VERSION "dbc-export 1 2025.20.8"

NS_ :

BS_:

BU_: ADSP APB APP APS APSB BB BMS CC CMP CMPD CP DAS DI DIF DIR DPB EPAS3P EPAS3S EPASTP EPASTS EPBL EPBR ESP EVSE FC GTW HCML HCMR HVP IBST ICR IDB LS OCS1P PARK PCS PM PMF PMR PNCD PTC RADC RCM RCM2 RCM3 RCU SCCM SCM SCS SDCR TAS TCU TPMS TRCM UI UIS UMC USM VC VCFRONT VCLEFT VCRIGHT VCSEC VEH

BO_ 1021 UI_autopilotControl: 8 UI
 SG_ UI_autopilotControlIndex M : 0|3@1+ (1,0) [0|7] "" Vector__XXX
 SG_ UI_hovEnabled m0 : 3|1@1+ (1,0) [0|1] "" Vector__XXX
 SG_ UI_donDisableAutoWiperDuration m0 : 4|3@1+ (1,0) [0|7] "" Vector__XXX
 SG_ UI_donDisableOnAutoWiperSpeed m0 : 7|4@1+ (1,0) [0|15] "" Vector__XXX
 SG_ UI_blindspotMinSpeed m0 : 11|4@1+ (1,0) [0|15] "" Vector__XXX
 SG_ UI_blindspotDistance m0 : 15|3@1+ (1,0) [0|7] "" Vector__XXX
 SG_ UI_blindspotTTC m0 : 18|3@1+ (1,0) [0|7] "" Vector__XXX
 SG_ UI_donStopEndOfRampBuffer m0 : 21|3@1+ (1,0) [0|7] "" Vector__XXX
 SG_ UI_donDisableCutin m0 : 24|1@1+ (1,0) [0|1] "" Vector__XXX
 SG_ UI_smartSetSpeedOffset m0 : 25|6@1+ (1,-30) [-30|33] "%" Vector__XXX
 SG_ UI_smartSetSpeedOffsetType m0 : 31|1@1+ (1,0) [0|1] "" Vector__XXX
 SG_ UI_autopilotMonarchBackup m0 : 32|1@1+ (1,0) [0|1] "" Vector__XXX
 SG_ UI_fsdVisualizationEnabled m0 : 37|1@1+ (1,0) [0|1] "" Vector__XXX
 SG_ UI_fsdStopsControlEnabled m0 : 38|1@1+ (1,0) [0|1] "" Vector__XXX
 SG_ UI_fsdContinueOnGreenWithCIPV m0 : 39|1@1+ (1,0) [0|1] "" Vector__XXX
 SG_ UI_smartSetSpeed m0 : 40|1@1+ (1,0) [0|1] "" Vector__XXX
 SG_ UI_automaticSetSpeedOffset m0 : 41|1@1+ (1,0) [0|1] "" Vector__XXX
 SG_ UI_apply2021_1958_ISA m0 : 42|1@1+ (1,0) [0|1] "" Vector__XXX
 SG_ UI_apply2021_646_ELKS m0 : 43|1@1+ (1,0) [0|1] "" Vector__XXX
 SG_ UI_apply2021_1341_DDAW m0 : 44|1@1+ (1,0) [0|1] "" Vector__XXX
 SG_ UI_homelinkNearby m0 : 45|1@1+ (1,0) [0|1] "" Vector__XXX
 SG_ UI_enableFullSelfDriving m0 : 46|1@1+ (1,0) [0|1] "" Vector__XXX
 SG_ UI_hasFullSelfDriving m0 : 47|1@1+ (1,0) [0|1] "" Vector__XXX
 SG_ UI_autosteerActivation m0 : 48|1@1+ (1,0) [0|1] "" Vector__XXX
 SG_ UI_autopilotDrivingProfile m0 : 49|2@1+ (1,0) [0|3] "" Vector__XXX
 SG_ UI_fsdBetaRequest m0 : 51|1@1+ (1,0) [0|1] "" Vector__XXX
 SG_ UI_fullSelfDrivingSuspended m0 : 52|1@1+ (1,0) [0|1] "" Vector__XXX
 SG_ UI_disableOptionalLaneChanges m0 : 53|1@1+ (1,0) [0|1] "" Vector__XXX
 SG_ UI_applyR152_AEBS m0 : 59|1@1+ (1,0) [0|1] "" Vector__XXX
 SG_ UI_autopilotControlMux0Valid m0 : 63|1@1+ (1,0) [0|1] "" Vector__XXX
 SG_ UI_selectableCameraRequest m1 : 8|4@1+ (1,0) [0|14] "" Vector__XXX
 SG_ UI_overrideSleepWithSuspend m1 : 16|1@1+ (1,0) [0|1] "" Vector__XXX
 SG_ UI_driverMonitorConfirmation m1 : 17|1@1+ (1,0) [0|1] "" Vector__XXX
 SG_ UI_parkAssistUseVision m1 : 18|1@1+ (1,0) [0|1] "" Vector__XXX
 SG_ UI_applyEceR79 m1 : 19|1@1+ (1,0) [0|1] "" Vector__XXX
 SG_ UI_enableMapStops m1 : 20|1@1+ (1,0) [0|1] "" Vector__XXX
 SG_ UI_disableMain m1 : 23|1@1+ (1,0) [0|1] "" Vector__XXX
 SG_ UI_disableNarrow m1 : 24|1@1+ (1,0) [0|1] "" Vector__XXX
 SG_ UI_disableFisheye m1 : 25|1@1+ (1,0) [0|1] "" Vector__XXX
 SG_ UI_disableLeftPillar m1 : 26|1@1+ (1,0) [0|1] "" Vector__XXX
 SG_ UI_disableRightPillar m1 : 27|1@1+ (1,0) [0|1] "" Vector__XXX
 SG_ UI_disableLeftRepeater m1 : 28|1@1+ (1,0) [0|1] "" Vector__XXX
 SG_ UI_disableRightRepeater m1 : 29|1@1+ (1,0) [0|1] "" Vector__XXX
 SG_ UI_disableBackup m1 : 30|1@1+ (1,0) [0|1] "" Vector__XXX
 SG_ UI_disableRadar m1 : 31|1@1+ (1,0) [0|1] "" Vector__XXX
 SG_ UI_noStalkConfirmAlertHaptic m1 : 32|1@1+ (1,0) [0|1] "" Vector__XXX
 SG_ UI_regulatoryLKA m1 : 33|1@1+ (1,0) [0|1] "" Vector__XXX
 SG_ UI_regulatoryLaneAssistLevel m1 : 34|1@1+ (1,0) [0|1] "" Vector__XXX
 SG_ UI_ulcSnooze m1 : 36|1@1+ (1,0) [0|1] "" Vector__XXX
 SG_ UI_noStalkConfirmAlertChime m1 : 37|1@1+ (1,0) [0|1] "" Vector__XXX
 SG_ UI_factorySummonEnable m1 : 39|1@1+ (1,0) [0|1] "" Vector__XXX
 SG_ UI_apmv3Branch m1 : 40|3@1+ (1,0) [0|7] "" Vector__XXX
 SG_ UI_enableCabinCamera m1 : 43|1@1+ (1,0) [0|1] "" Vector__XXX
 SG_ UI_enableAutopilotStopWarning m1 : 44|1@1+ (1,0) [0|1] "" Vector__XXX
 SG_ UI_showLaneGraph m1 : 45|1@1+ (1,0) [0|1] "" Vector__XXX
 SG_ UI_showTrackLabels m1 : 46|1@1+ (1,0) [0|1] "" Vector__XXX
 SG_ UI_hardCoreSummon m1 : 47|1@1+ (1,0) [0|1] "" Vector__XXX
 SG_ UI_enableCabinCameraTelemetry m1 : 48|1@1+ (1,0) [0|1] "" Vector__XXX
 SG_ UI_enableVisionSpeedControl m1 : 49|1@1+ (1,0) [0|1] "" Vector__XXX
 SG_ UI_autopilotTelemetryInChina m1 : 50|1@1+ (1,0) [0|1] "" Vector__XXX
 SG_ UI_enableTeslaAutopark m1 : 51|1@1+ (1,0) [0|1] "" Vector__XXX
 SG_ UI_autoTurnSignalMode m1 : 52|1@1+ (1,0) [0|1] "" Vector__XXX
 SG_ UI_enableCautionLightControl m1 : 54|1@1+ (1,0) [0|1] "" Vector__XXX
 SG_ UI_applyEceR79SmartSummonOnly m1 : 55|1@1+ (1,0) [0|1] "" Vector__XXX
 SG_ UI_autopilotMonarchEnabled m1 : 56|1@1+ (1,0) [0|1] "" Vector__XXX
 SG_ UI_autopilotEphemerisEnabled m1 : 57|1@1+ (1,0) [0|1] "" Vector__XXX
 SG_ UI_enableCabinAudioRecording m1 : 59|1@1+ (1,0) [0|1] "" Vector__XXX
 SG_ UI_autopilotControlMux1Valid m1 : 63|1@1+ (1,0) [0|1] "" Vector__XXX
 SG_ UI_enableApproachingEmergencyVeh m2 : 5|1@1+ (1,0) [0|1] "" Vector__XXX
 SG_ UI_enableStartFsdFromParkBrakeCo m2 : 6|1@1+ (1,0) [0|1] "" Vector__XXX
 SG_ UI_enableStartFsdFromPark m2 : 7|1@1+ (1,0) [0|1] "" Vector__XXX
 SG_ UI_fsdMaxSpeedOffsetPercentage m2 : 8|6@1+ (1,0) [0|63] "%" Vector__XXX
 SG_ UI_coldStartMonarchInFactory m2 : 16|1@1+ (1,0) [0|1] "" Vector__XXX
 SG_ UI_autopilotControlMux2Valid m2 : 63|1@1+ (1,0) [0|1] "" Vector__XXX

BO_ 819 UI_chargeRequest: 5 UI
 SG_ UI_openChargePortDoorRequest : 0|1@1+ (1,0) [0|1] "" Vector__XXX
 SG_ UI_closeChargePortDoorRequest : 1|1@1+ (1,0) [0|1] "" Vector__XXX
 SG_ UI_chargeEnableRequest : 2|1@1+ (1,0) [0|1] "" Vector__XXX
 SG_ UI_brickVLoggingRequest : 3|1@1+ (1,0) [0|1] "" Vector__XXX
 SG_ UI_brickBalancingDisabled : 4|1@1+ (1,0) [0|1] "" Vector__XXX
 SG_ UI_dSocAlertThreshold : 5|3@1+ (0.5,-4) [-4|-0.5] "%" Vector__XXX
 SG_ UI_acChargeCurrentLimit : 8|7@1+ (1,0) [0|126] "A" Vector__XXX
 SG_ UI_dSocAlertEnable : 15|1@1+ (1,0) [0|1] "" Vector__XXX
 SG_ UI_chargeTerminationPct : 16|10@1+ (0.1,0) [5|100] "%" Vector__XXX
 SG_ UI_chargeFeature1 : 26|1@1+ (1,0) [0|1] "" Vector__XXX
 SG_ UI_chargeFeature2 : 27|1@1+ (1,0) [0|1] "" Vector__XXX
 SG_ UI_chargeFeature3 : 28|1@1+ (1,0) [0|1] "" Vector__XXX
 SG_ UI_scheduledDepartureEnabled : 29|1@1+ (1,0) [0|1] "" Vector__XXX
 SG_ UI_chargePortLatchRequest : 30|2@1+ (1,0) [0|3] "" Vector__XXX
 SG_ UI_socSnapshotExpirationTime : 32|4@1+ (2,2) [2|32] "weeks" Vector__XXX
 SG_ UI_cpInletHeaterRequest : 36|2@1+ (1,0) [0|3] "" Vector__XXX
 SG_ UI_chargePowerSampleRequest : 38|1@1+ (1,0) [0|1] "" Vector__XXX
 SG_ UI_enableIso15118 : 39|1@1+ (1,0) [0|1] "" Vector__XXX

BO_ 659 UI_chassisControl: 8 UI
 SG_ UI_steeringTuneRequest : 0|2@1+ (1,0) [0|3] "" Vector__XXX
 SG_ UI_tractionControlMode : 2|3@1+ (1,0) [0|7] "" Vector__XXX
 SG_ UI_parkBrakeRequest : 5|2@1+ (1,0) [0|2] "" Vector__XXX
 SG_ UI_narrowGarages : 7|1@1+ (1,0) [0|1] "" Vector__XXX
 SG_ UI_winchModeRequest : 8|2@1+ (1,0) [0|3] "" Vector__XXX
 SG_ UI_zeroSpeedConfirmed : 10|2@1+ (1,0) [0|2] "" Vector__XXX
 SG_ UI_trailerMode : 12|1@1+ (1,0) [0|1] "" Vector__XXX
 SG_ UI_distanceUnits : 13|1@1+ (1,0) [0|1] "" Vector__XXX
 SG_ UI_dasDebugEnable : 14|1@1+ (1,0) [0|1] "" Vector__XXX
 SG_ UI_accOvertakeEnable : 16|2@1+ (1,0) [0|2] "" Vector__XXX
 SG_ UI_aebEnable : 18|2@1+ (1,0) [0|2] "" Vector__XXX
 SG_ UI_aesEnable : 20|2@1+ (1,0) [0|2] "" Vector__XXX
 SG_ UI_ahlbEnable : 22|2@1+ (1,0) [0|2] "" Vector__XXX
 SG_ UI_autoLaneChangeEnable : 24|2@1+ (1,0) [0|2] "" Vector__XXX
 SG_ UI_winchProxUserOverride : 26|1@1+ (1,0) [0|1] "" Vector__XXX
 SG_ UI_rebootAutopilot : 27|1@1+ (1,0) [0|1] "" Vector__XXX
 SG_ UI_autoParkRequest : 28|4@1+ (1,0) [0|14] "" Vector__XXX
 SG_ UI_bsdEnable : 32|2@1+ (1,0) [0|2] "" Vector__XXX
 SG_ UI_fcwEnable : 34|2@1+ (1,0) [0|2] "" Vector__XXX
 SG_ UI_fcwSensitivity : 36|2@1+ (1,0) [0|2] "" Vector__XXX
 SG_ UI_latControlEnable : 38|2@1+ (1,0) [0|2] "" Vector__XXX
 SG_ UI_ldwEnable : 40|2@1+ (1,0) [0|2] "" Vector__XXX
 SG_ UI_pedalSafetyEnable : 42|2@1+ (1,0) [0|2] "" Vector__XXX
 SG_ UI_pedalMap_epas : 44|2@1+ (1,0) [0|3] "" Vector__XXX
 SG_ UI_redLightStopSignEnable : 46|2@1+ (1,0) [0|2] "" Vector__XXX
 SG_ UI_selfParkTune : 48|4@1+ (1,0) [0|14] "" Vector__XXX
 SG_ UI_chassisControlCounter : 52|4@1+ (1,0) [0|15] "" Vector__XXX
 SG_ UI_chassisControlChecksum : 56|8@1+ (1,0) [0|255] "" Vector__XXX

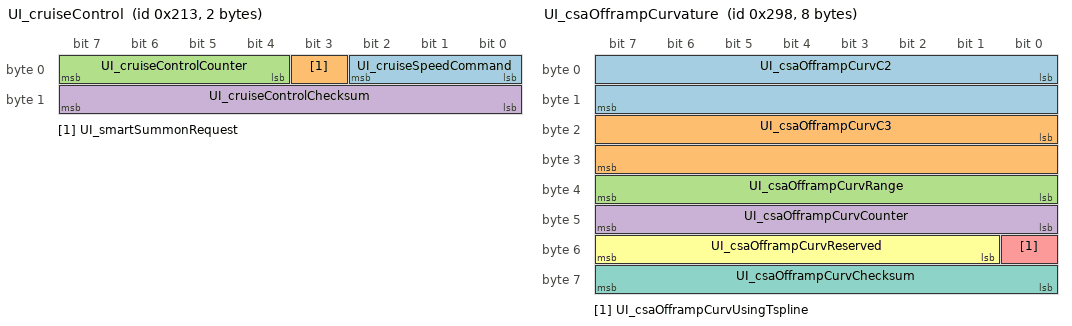
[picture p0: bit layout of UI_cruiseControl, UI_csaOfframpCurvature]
BO_ 531 UI_cruiseControl: 2 UI
 SG_ UI_cruiseSpeedCommand : 0|3@1+ (1,0) [0|7] "" Vector__XXX
 SG_ UI_smartSummonRequest : 3|1@1+ (1,0) [0|1] "" Vector__XXX
 SG_ UI_cruiseControlCounter : 4|4@1+ (1,0) [0|15] "" Vector__XXX
 SG_ UI_cruiseControlChecksum : 8|8@1+ (1,0) [0|255] "" Vector__XXX

BO_ 664 UI_csaOfframpCurvature: 8 UI
 SG_ UI_csaOfframpCurvC2 : 0|16@1- (1.0e-06,0) [-0.032768|0.032767] "1/m" Vector__XXX
 SG_ UI_csaOfframpCurvC3 : 16|16@1- (4.0e-09,0) [-0.000131072|0.000131068] "1/m2" Vector__XXX
 SG_ UI_csaOfframpCurvRange : 32|8@1+ (2,0) [0|510] "m" Vector__XXX
 SG_ UI_csaOfframpCurvCounter : 40|8@1+ (1,0) [0|255] "" Vector__XXX
 SG_ UI_csaOfframpCurvUsingTspline : 48|1@1+ (1,0) [0|1] "" Vector__XXX
 SG_ UI_csaOfframpCurvReserved : 49|7@1+ (1,0) [0|127] "" Vector__XXX
 SG_ UI_csaOfframpCurvChecksum : 56|8@1+ (1,0) [0|255] "" Vector__XXX

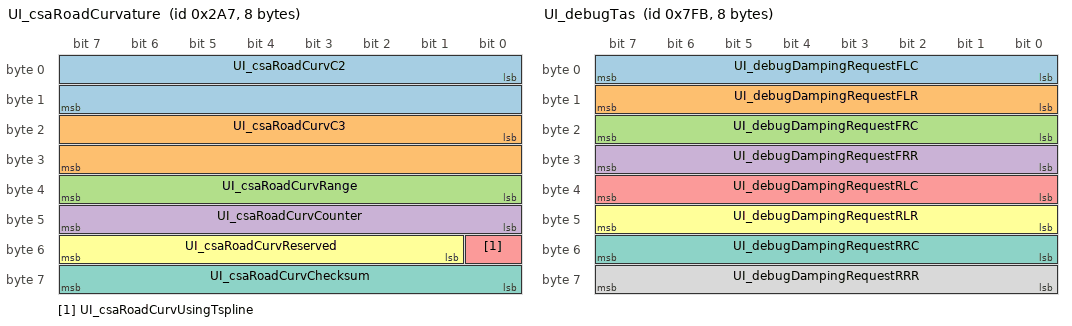
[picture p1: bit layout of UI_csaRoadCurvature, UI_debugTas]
BO_ 679 UI_csaRoadCurvature: 8 UI
 SG_ UI_csaRoadCurvC2 : 0|16@1- (1.0e-06,0) [-0.032768|0.032767] "1/m" Vector__XXX
 SG_ UI_csaRoadCurvC3 : 16|16@1- (4.0e-09,0) [-0.000131072|0.000131068] "1/m2" Vector__XXX
 SG_ UI_csaRoadCurvRange : 32|8@1+ (2,0) [0|510] "m" Vector__XXX
 SG_ UI_csaRoadCurvCounter : 40|8@1+ (1,0) [0|255] "" Vector__XXX
 SG_ UI_csaRoadCurvUsingTspline : 48|1@1+ (1,0) [0|1] "" Vector__XXX
 SG_ UI_csaRoadCurvReserved : 49|7@1+ (1,0) [0|127] "" Vector__XXX
 SG_ UI_csaRoadCurvChecksum : 56|8@1+ (1,0) [0|255] "" Vector__XXX

BO_ 1280 UI_debugECU: 2 UI
 SG_ UI_debugEcuTarget M : 0|5@1+ (1,0) [0|31] "" Vector__XXX
 SG_ UI_DI_debugEnable m1 : 8|1@1+ (1,0) [0|1] "" Vector__XXX
 SG_ UI_DIS_debugEnable m2 : 8|1@1+ (1,0) [0|1] "" Vector__XXX
 SG_ UI_PM_debugEnable m3 : 8|1@1+ (1,0) [0|1] "" Vector__XXX
 SG_ UI_PM_debugAt100Hz m3 : 9|1@1+ (1,0) [0|1] "" Vector__XXX
 SG_ UI_PMS_debugEnable m4 : 8|1@1+ (1,0) [0|1] "" Vector__XXX
 SG_ UI_PMS_debugAt100Hz m4 : 9|1@1+ (1,0) [0|1] "" Vector__XXX
 SG_ UI_BMS_debugAllEnable m5 : 8|1@1+ (1,0) [0|1] "" Vector__XXX
 SG_ UI_BMS_debugDisable m5 : 9|1@1+ (1,0) [0|1] "" Vector__XXX
 SG_ UI_VCRIGHT_debugEnable m6 : 8|1@1+ (1,0) [0|1] "" Vector__XXX
 SG_ UI_VCFRONT_debugEnable m7 : 5|1@1+ (1,0) [0|1] "" Vector__XXX
 SG_ UI_DIF_debugEnable m8 : 8|1@1+ (1,0) [0|1] "" Vector__XXX
 SG_ UI_DIR_debugEnable m9 : 8|1@1+ (1,0) [0|1] "" Vector__XXX
 SG_ UI_PMF_debugEnable m10 : 8|1@1+ (1,0) [0|1] "" Vector__XXX
 SG_ UI_PMR_debugEnable m11 : 8|1@1+ (1,0) [0|1] "" Vector__XXX

BO_ 2043 UI_debugTas: 8 UI
 SG_ UI_debugDampingRequestFLC : 0|8@1+ (0.01,0) [0|2.54] "A" Vector__XXX
 SG_ UI_debugDampingRequestFLR : 8|8@1+ (0.01,0) [0|2.54] "A" Vector__XXX
 SG_ UI_debugDampingRequestFRC : 16|8@1+ (0.01,0) [0|2.54] "A" Vector__XXX
 SG_ UI_debugDampingRequestFRR : 24|8@1+ (0.01,0) [0|2.54] "A" Vector__XXX
 SG_ UI_debugDampingRequestRLC : 32|8@1+ (0.01,0) [0|2.54] "A" Vector__XXX
 SG_ UI_debugDampingRequestRLR : 40|8@1+ (0.01,0) [0|2.54] "A" Vector__XXX
 SG_ UI_debugDampingRequestRRC : 48|8@1+ (0.01,0) [0|2.54] "A" Vector__XXX
 SG_ UI_debugDampingRequestRRR : 56|8@1+ (0.01,0) [0|2.54] "A" Vector__XXX

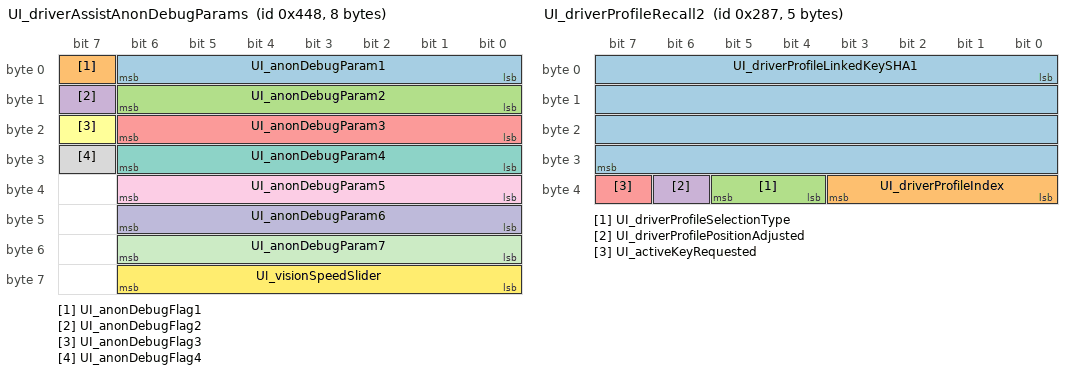
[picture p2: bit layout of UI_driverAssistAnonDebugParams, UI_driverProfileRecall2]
BO_ 1096 UI_driverAssistAnonDebugParams: 8 UI
 SG_ UI_anonDebugParam1 : 0|7@1+ (1,0) [0|127] "" Vector__XXX
 SG_ UI_anonDebugFlag1 : 7|1@1+ (1,0) [0|1] "" Vector__XXX
 SG_ UI_anonDebugParam2 : 8|7@1+ (1,0) [0|127] "" Vector__XXX
 SG_ UI_anonDebugFlag2 : 15|1@1+ (1,0) [0|1] "" Vector__XXX
 SG_ UI_anonDebugParam3 : 16|7@1+ (1,0) [0|127] "" Vector__XXX
 SG_ UI_anonDebugFlag3 : 23|1@1+ (1,0) [0|1] "" Vector__XXX
 SG_ UI_anonDebugParam4 : 24|7@1+ (1,0) [0|127] "" Vector__XXX
 SG_ UI_anonDebugFlag4 : 31|1@1+ (1,0) [0|1] "" Vector__XXX
 SG_ UI_anonDebugParam5 : 32|7@1+ (1,0) [0|127] "" Vector__XXX
 SG_ UI_anonDebugParam6 : 40|7@1+ (1,0) [0|127] "" Vector__XXX
 SG_ UI_anonDebugParam7 : 48|7@1+ (1,0) [0|127] "" Vector__XXX
 SG_ UI_visionSpeedSlider : 56|7@1+ (1,0) [0|127] "" Vector__XXX

BO_ 1016 UI_driverAssistControl: 8 UI
 SG_ UI_autopilotControlRequest : 0|1@1+ (1,0) [0|1] "" Vector__XXX
 SG_ UI_ulcStalkConfirm : 1|1@1+ (1,0) [0|1] "" Vector__XXX
 SG_ UI_summonHeartbeat : 2|2@1+ (1,0) [0|3] "" Vector__XXX
 SG_ UI_curvSpeedAdaptDisable : 4|1@1+ (1,0) [0|1] "" Vector__XXX
 SG_ UI_dasDeveloper : 5|1@1+ (1,0) [0|1] "" Vector__XXX
 SG_ UI_enableVinAssociation : 6|1@1+ (1,0) [0|1] "" Vector__XXX
 SG_ UI_lssLkaEnabled : 7|1@1+ (1,0) [0|1] "" Vector__XXX
 SG_ UI_lssLdwEnabled : 8|1@1+ (1,0) [0|1] "" Vector__XXX
 SG_ UI_coastToCoast : 9|1@1+ (1,0) [0|1] "" Vector__XXX
 SG_ UI_autoSummonEnable : 10|1@1+ (1,0) [0|1] "" Vector__XXX
 SG_ UI_exceptionListEnable : 11|1@1+ (1,0) [0|1] "" Vector__XXX
 SG_ UI_roadCheckDisable : 12|1@1+ (1,0) [0|1] "" Vector__XXX
 SG_ UI_driveOnMapsEnable : 13|1@1+ (1,0) [0|1] "" Vector__XXX
 SG_ UI_handsOnRequirementDisable : 14|1@1+ (1,0) [0|1] "" Vector__XXX
 SG_ UI_ulcOffHighway : 15|1@1+ (1,0) [0|1] "" Vector__XXX
 SG_ UI_fuseLanesDisable : 16|1@1+ (1,0) [0|1] "" Vector__XXX
 SG_ UI_fuseHPPDisable : 17|1@1+ (1,0) [0|1] "" Vector__XXX
 SG_ UI_fuseVehiclesDisable : 18|1@1+ (1,0) [0|1] "" Vector__XXX
 SG_ UI_enableClipParkedTelemetry : 19|1@1+ (1,0) [0|1] "" Vector__XXX
 SG_ UI_visionSpeedType : 20|2@1+ (1,0) [0|3] "" Vector__XXX
 SG_ UI_curvatureDatabaseOnly : 22|1@1+ (1,0) [0|1] "" Vector__XXX
 SG_ UI_lssElkEnabled : 23|1@1+ (1,0) [0|1] "" Vector__XXX
 SG_ UI_summonExitType : 24|2@1+ (1,0) [0|2] "" Vector__XXX
 SG_ UI_summonEntryType : 26|2@1+ (1,0) [0|2] "" Vector__XXX
 SG_ UI_selfParkRequest : 28|4@1+ (1,0) [0|14] "" Vector__XXX
 SG_ UI_summonReverseDist : 32|6@1+ (1,0) [0|62] "" Vector__XXX
 SG_ UI_undertakeAssistEnable : 38|1@1+ (1,0) [0|1] "" Vector__XXX
 SG_ UI_adaptiveSetSpeedEnable : 39|1@1+ (1,0) [0|1] "" Vector__XXX
 SG_ UI_drivingSide : 40|2@1+ (1,0) [0|3] "" Vector__XXX
 SG_ UI_enableClipTelemetry : 42|1@1+ (1,0) [0|1] "" Vector__XXX
 SG_ UI_enableTripTelemetry : 43|1@1+ (1,0) [0|1] "" Vector__XXX
 SG_ UI_enableRoadSegmentTelemetry : 44|1@1+ (1,0) [0|1] "" Vector__XXX
 SG_ UI_accFollowDistanceSetting : 45|3@1+ (1,0) [0|6] "" Vector__XXX
 SG_ UI_hasDriveOnNav : 48|1@1+ (1,0) [0|1] "" Vector__XXX
 SG_ UI_followNavRouteEnable : 49|1@1+ (1,0) [0|1] "" Vector__XXX
 SG_ UI_ulcSpeedConfig : 50|2@1+ (1,0) [0|3] "" Vector__XXX
 SG_ UI_ulcBlindSpotConfig : 52|2@1+ (1,0) [0|3] "" Vector__XXX
 SG_ UI_suppressExitPassingLane : 54|1@1+ (1,0) [0|1] "" Vector__XXX
 SG_ UI_enableClipStartStopTelemetry : 55|1@1+ (1,0) [0|1] "" Vector__XXX
 SG_ UI_alcOffHighwayEnable : 56|1@1+ (1,0) [0|1] "" Vector__XXX
 SG_ UI_validationLoop : 57|1@1+ (1,0) [0|1] "" Vector__XXX
 SG_ UI_smartSummonType : 58|2@1+ (1,0) [0|3] "" Vector__XXX
 SG_ UI_enableVisionOnlyStops : 60|1@1+ (1,0) [0|1] "" Vector__XXX
 SG_ UI_source3D : 61|2@1+ (1,0) [0|3] "" Vector__XXX
 SG_ UI_isaSpeedingChimeMuted : 63|1@1+ (1,0) [0|1] "" Vector__XXX

BO_ 568 UI_driverAssistMapData: 8 UI
 SG_ UI_mapSpeedLimitDependency : 0|3@1+ (1,0) [0|6] "" Vector__XXX
 SG_ UI_roadClass : 3|3@1+ (1,0) [1|7] "" Vector__XXX
 SG_ UI_inSuperchargerGeofence : 6|1@1+ (1,0) [0|1] "" Vector__XXX
 SG_ UI_mapSpeedUnits : 7|1@1+ (1,0) [0|1] "" Vector__XXX
 SG_ UI_mapSpeedLimit : 8|5@1+ (1,0) [0|30] "" Vector__XXX
 SG_ UI_mapSpeedLimitType : 13|3@1+ (1,0) [0|6] "" Vector__XXX
 SG_ UI_countryCode : 16|10@1+ (1,0) [0|1022] "" Vector__XXX
 SG_ UI_streetCount : 26|2@1+ (1,0) [0|3] "" Vector__XXX
 SG_ UI_gpsRoadMatch : 28|1@1+ (1,0) [0|1] "" Vector__XXX
 SG_ UI_navRouteActive : 29|1@1+ (1,0) [0|1] "" Vector__XXX
 SG_ UI_parallelAutoparkEnabled : 30|1@1+ (1,0) [0|1] "" Vector__XXX
 SG_ UI_perpendicularAutoparkEnabled : 31|1@1+ (1,0) [0|1] "" Vector__XXX
 SG_ UI_nextBranchDist : 32|5@1+ (10,0) [0|300] "m" Vector__XXX
 SG_ UI_controlledAccess : 37|1@1+ (1,0) [0|1] "" Vector__XXX
 SG_ UI_nextBranchLeftOffRamp : 38|1@1+ (1,0) [0|1] "" Vector__XXX
 SG_ UI_nextBranchRightOffRamp : 39|1@1+ (1,0) [0|1] "" Vector__XXX
 SG_ UI_rejectLeftLane : 40|1@1+ (1,0) [0|1] "" Vector__XXX
 SG_ UI_rejectRightLane : 41|1@1+ (1,0) [0|1] "" Vector__XXX
 SG_ UI_rejectHPP : 42|1@1+ (1,0) [0|1] "" Vector__XXX
 SG_ UI_rejectNav : 43|1@1+ (1,0) [0|1] "" Vector__XXX
 SG_ UI_rejectLeftFreeSpace : 44|1@1+ (1,0) [0|1] "" Vector__XXX
 SG_ UI_rejectRightFreeSpace : 45|1@1+ (1,0) [0|1] "" Vector__XXX
 SG_ UI_rejectAutosteer : 46|1@1+ (1,0) [0|1] "" Vector__XXX
 SG_ UI_rejectHandsOn : 47|1@1+ (1,0) [0|1] "" Vector__XXX
 SG_ UI_acceptBottsDots : 48|1@1+ (1,0) [0|1] "" Vector__XXX
 SG_ UI_autosteerRestricted : 49|1@1+ (1,0) [0|1] "" Vector__XXX
 SG_ UI_pmmEnabled : 50|1@1+ (1,0) [0|1] "" Vector__XXX
 SG_ UI_scaEnabled : 51|1@1+ (1,0) [0|1] "" Vector__XXX
 SG_ UI_mapDataCounter : 52|4@1+ (1,0) [0|15] "" Vector__XXX
 SG_ UI_mapDataChecksum : 56|8@1+ (1,0) [0|255] "" Vector__XXX

BO_ 536 UI_driverAssistRoadSign: 8 UI
 SG_ UI_roadSign M : 0|8@1+ (1,0) [0|254] "" Vector__XXX
 SG_ UI_splineLocConfidence : 40|7@1+ (1,0) [1|127] "1" Vector__XXX
 SG_ UI_splineID : 48|4@1+ (1,0) [0|15] "" Vector__XXX
 SG_ UI_roadSignCounter : 52|4@1+ (1,0) [0|15] "" Vector__XXX
 SG_ UI_roadSignChecksum : 56|8@1+ (1,0) [0|255] "" Vector__XXX
 SG_ UI_dummyData m0 : 8|1@1+ (1,0) [0|1] "" Vector__XXX
 SG_ UI_stopSignStopLineDist m1 : 8|10@1+ (0.25,-8) [-8|247.5] "m" Vector__XXX
 SG_ UI_stopSignStopLineConf m1 : 18|7@1+ (1,0) [1|127] "1" Vector__XXX
 SG_ UI_trafficLightStopLineDist m2 : 8|10@1+ (0.25,-8) [-8|247.5] "m" Vector__XXX
 SG_ UI_trafficLightStopLineConf m2 : 18|7@1+ (1,0) [1|127] "1" Vector__XXX
 SG_ UI_baseMapSpeedLimitMPS m3 : 8|8@1+ (0.25,0) [0|63.5] "m/s" Vector__XXX
 SG_ UI_bottomQrtlFleetSpeedMPS m3 : 16|8@1+ (0.25,0) [0|63.5] "m/s" Vector__XXX
 SG_ UI_topQrtlFleetSpeedMPS m3 : 24|8@1+ (0.25,0) [0|63.5] "m/s" Vector__XXX
 SG_ UI_meanFleetSplineSpeedMPS m4 : 8|8@1+ (0.25,0) [0|63.5] "m/s" Vector__XXX
 SG_ UI_medianFleetSpeedMPS m4 : 16|8@1+ (0.25,0) [0|63.5] "m/s" Vector__XXX
 SG_ UI_meanFleetSplineAccelMPS2 m4 : 24|8@1+ (0.05,-6.35) [-6.35|6.35] "m/s^2" Vector__XXX
 SG_ UI_rampType m4 : 32|3@1+ (1,0) [1|7] "" Vector__XXX
 SG_ UI_valhallaRamp m4 : 35|2@1+ (1,0) [1|3] "" Vector__XXX
 SG_ UI_overrideACMFleetSpeed m4 : 38|1@1+ (1,0) [0|1] "" Vector__XXX
 SG_ UI_currSplineIdFull m5 : 8|32@1+ (1,0) [1|4294967295] "1" Vector__XXX

BO_ 645 UI_driverProfileRecall: 8 UI
 SG_ UI_driverProfileRecallIndex M : 0|3@1+ (1,0) [1|7] "" Vector__XXX
 SG_ UI_driverProfileRecallStop : 3|1@1+ (1,0) [0|1] "" Vector__XXX
 SG_ UI_frontSeatRecallActive m1 : 4|1@1+ (1,0) [0|1] "" Vector__XXX
 SG_ UI_frontSeatTrackPos m1 : 5|10@1- (4,0) [-2048|2044] "mm" Vector__XXX
 SG_ UI_frontSeatBackPos m1 : 16|12@1- (0.1,0) [-204.8|204.7] "deg" Vector__XXX
 SG_ UI_frontSeatLiftPos m1 : 32|10@1- (4,0) [-2048|2044] "mm" Vector__XXX
 SG_ UI_frontSeatTiltPos m1 : 48|12@1- (0.1,0) [-204.8|204.7] "deg" Vector__XXX
 SG_ UI_columnAndLumbarRecallActive m2 : 4|1@1+ (1,0) [0|1] "" Vector__XXX
 SG_ UI_steeringColumnUpDownPos m2 : 8|8@1- (1,103) [-25|230] "mm" Vector__XXX
 SG_ UI_lumbarAPressureHpa m2 : 16|16@1+ (1,0) [0|65535] "" Vector__XXX
 SG_ UI_lumbarBPressureHpa m2 : 32|16@1+ (1,0) [0|65535] "" Vector__XXX
 SG_ UI_steeringColumnInOutPos m2 : 48|8@1- (1,103) [-25|230] "mm" Vector__XXX
 SG_ UI_leftMirrorTiltXPosition m3 : 8|8@1+ (0.02,0) [0|5] "V" Vector__XXX
 SG_ UI_leftMirrorTiltYPosition m3 : 16|8@1+ (0.02,0) [0|5] "V" Vector__XXX
 SG_ UI_rightMirrorTiltXPosition m3 : 24|8@1+ (0.02,0) [0|5.1] "V" Vector__XXX
 SG_ UI_rightMirrorTiltYPosition m3 : 32|8@1+ (0.02,0) [0|5.1] "V" Vector__XXX
 SG_ UI_mirrorRecallActive m4 : 4|1@1+ (1,0) [0|1] "" Vector__XXX
 SG_ UI_customMirrorDipPositionsSet m4 : 5|1@1+ (1,0) [0|1] "" Vector__XXX
 SG_ UI_leftMirrorDipXPosition m4 : 8|8@1+ (0.02,0) [0|5] "V" Vector__XXX
 SG_ UI_leftMirrorDipYPosition m4 : 16|8@1+ (0.02,0) [0|5] "V" Vector__XXX
 SG_ UI_rightMirrorDipXPosition m4 : 24|8@1+ (0.02,0) [0|5.1] "V" Vector__XXX
 SG_ UI_rightMirrorDipYPosition m4 : 32|8@1+ (0.02,0) [0|5.1] "V" Vector__XXX
 SG_ UI_modifyMirrorDipRequest m4 : 40|2@1+ (1,0) [0|3] "" Vector__XXX

BO_ 647 UI_driverProfileRecall2: 5 UI
 SG_ UI_driverProfileLinkedKeySHA1 : 0|32@1+ (1,0) [0|4294967294] "" Vector__XXX
 SG_ UI_driverProfileIndex : 32|4@1+ (1,0) [0|15] "" Vector__XXX
 SG_ UI_driverProfileSelectionType : 36|2@1+ (1,0) [0|3] "" Vector__XXX
 SG_ UI_driverProfilePositionAdjusted : 38|1@1+ (1,0) [0|1] "" Vector__XXX
 SG_ UI_activeKeyRequested : 39|1@1+ (1,0) [0|1] "" Vector__XXX

BO_ 1971 UI_dynamicTriggersCampaignFired: 8 UI
 SG_ UI_campaignFired : 0|64@1+ (1,0) [0|1.84467440737e+19] "" Vector__XXX

BO_ 984 UI_elevationStatus: 4 UI
 SG_ UI_elevation : 0|14@1- (1,0) [-8192|8190] "m" Vector__XXX
 SG_ UI_navElevation : 16|14@1- (1,0) [-8192|8190] "m" Vector__XXX

BO_ 1279 UI_energyConsumptionInfo: 8 UI
 SG_ UI_energyConsumptionInfoIndex M : 0|5@1+ (1,0) [0|31] "" Vector__XXX
 SG_ UI_energyLossTotal_epa m0 : 16|16@1- (1,0) [-32768|32767] "Wh" Vector__XXX
 SG_ UI_energyLossDriving_epa m0 : 32|16@1- (1,0) [-32768|32767] "Wh" Vector__XXX
 SG_ UI_energyLossClimate_epa m0 : 48|16@1- (1,0) [-32768|32767] "Wh" Vector__XXX
 SG_ UI_energyLossBattCond_epa m1 : 16|16@1- (1,0) [-32768|32767] "Wh" Vector__XXX
 SG_ UI_energyLossElevation_epa m1 : 32|16@1- (1,0) [-32768|32767] "Wh" Vector__XXX
 SG_ UI_energyLossAcc_epa m1 : 48|16@1- (1,0) [-32768|32767] "Wh" Vector__XXX
 SG_ UI_energyLossTotalSinceCharge_ep m2 : 16|16@1- (1,0) [-32768|32767] "Wh" Vector__XXX
 SG_ UI_energyLossDrivingSinceCharge_ m2 : 32|16@1- (1,0) [-32768|32767] "Wh" Vector__XXX
 SG_ UI_energyLossClimateSinceCharge_ m2 : 48|16@1- (1,0) [-32768|32767] "Wh" Vector__XXX
 SG_ UI_energyLossBattCondSinceCharge m3 : 16|16@1- (1,0) [-32768|32767] "Wh" Vector__XXX
 SG_ UI_energyLossElevationSinceCharg m3 : 32|16@1- (1,0) [-32768|32767] "Wh" Vector__XXX
 SG_ UI_energyLossAccSinceCharge_epa m3 : 48|16@1- (1,0) [-32768|32767] "Wh" Vector__XXX
 SG_ UI_energyLossTotalSinceTripStart m4 : 16|16@1- (1,0) [-32768|32767] "Wh" Vector__XXX
 SG_ UI_energyLossDrivingSinceTripSta m4 : 32|16@1- (1,0) [-32768|32767] "Wh" Vector__XXX
 SG_ UI_energyLossClimateSinceTripSta m4 : 48|16@1- (1,0) [-32768|32767] "Wh" Vector__XXX
 SG_ UI_energyLossBattCondSinceTripSt m5 : 16|16@1- (1,0) [-32768|32767] "Wh" Vector__XXX
 SG_ UI_energyLossElevationSinceTripS m5 : 32|16@1- (1,0) [-32768|32767] "Wh" Vector__XXX
 SG_ UI_energyLossAccSinceTripStart m5 : 48|16@1- (1,0) [-32768|32767] "Wh" Vector__XXX
 SG_ UI_energyDeltaTotal_epa m6 : 16|16@1- (1,0) [-32768|32767] "Wh" Vector__XXX
 SG_ UI_energyDeltaDriving_epa m6 : 32|16@1- (1,0) [-32768|32767] "Wh" Vector__XXX
 SG_ UI_energyDeltaClimate_epa m6 : 48|16@1- (1,0) [-32768|32767] "Wh" Vector__XXX
 SG_ UI_energyDeltaBattCond_epa m7 : 16|16@1- (1,0) [-32768|32767] "Wh" Vector__XXX
 SG_ UI_energyDeltaElevation_epa m7 : 32|16@1- (1,0) [-32768|32767] "Wh" Vector__XXX
 SG_ UI_energyDeltaAcc_epa m7 : 48|16@1- (1,0) [-32768|32767] "Wh" Vector__XXX
 SG_ UI_uiDeltaOffsetTotal_epa m8 : 16|16@1- (1,0) [-32768|32767] "Wh" Vector__XXX
 SG_ UI_uiDeltaOffsetDriving_epa m8 : 32|16@1- (1,0) [-32768|32767] "Wh" Vector__XXX
 SG_ UI_uiDeltaOffsetClimate_epa m8 : 48|16@1- (1,0) [-32768|32767] "Wh" Vector__XXX
 SG_ UI_uiDeltaOffsetBattCond_epa m9 : 16|16@1- (1,0) [-32768|32767] "Wh" Vector__XXX
 SG_ UI_uiDeltaOffsetElevation_epa m9 : 32|16@1- (1,0) [-32768|32767] "Wh" Vector__XXX
 SG_ UI_uiDeltaOffsetAcc_epa m9 : 48|16@1- (1,0) [-32768|32767] "Wh" Vector__XXX
 SG_ UI_rawToUiEnergyRatio_epa m10 : 8|8@1+ (0.01,0) [0|2.55] "-" Vector__XXX
 SG_ UI_driveDistance_epa m10 : 16|16@1+ (0.01,0) [0|655.35] "miles" Vector__XXX
 SG_ UI_energyDeltaTotalSinceCharge_e m11 : 16|16@1- (1,0) [-32768|32767] "Wh" Vector__XXX
 SG_ UI_energyDeltaDrivingSinceCharge m11 : 32|16@1- (1,0) [-32768|32767] "Wh" Vector__XXX
 SG_ UI_energyDeltaClimateSinceCharge m11 : 48|16@1- (1,0) [-32768|32767] "Wh" Vector__XXX
 SG_ UI_energyDeltaBattCondSinceCharg m12 : 16|16@1- (1,0) [-32768|32767] "Wh" Vector__XXX
 SG_ UI_energyDeltaElevationSinceChar m12 : 32|16@1- (1,0) [-32768|32767] "Wh" Vector__XXX
 SG_ UI_energyDeltaAccSinceCharge_epa m12 : 48|16@1- (1,0) [-32768|32767] "Wh" Vector__XXX
 SG_ UI_uiDeltaOffsetTotalSinceCharge m13 : 16|16@1- (1,0) [-32768|32767] "Wh" Vector__XXX
 SG_ UI_uiDeltaOffsetDrivingSinceChar m13 : 32|16@1- (1,0) [-32768|32767] "Wh" Vector__XXX
 SG_ UI_uiDeltaOffsetClimateSinceChar m13 : 48|16@1- (1,0) [-32768|32767] "Wh" Vector__XXX
 SG_ UI_uiDeltaOffsetBattCondSinceCha m14 : 16|16@1- (1,0) [-32768|32767] "Wh" Vector__XXX
 SG_ UI_uiDeltaOffsetElevationSinceCh m14 : 32|16@1- (1,0) [-32768|32767] "Wh" Vector__XXX
 SG_ UI_uiDeltaOffsetAccSinceCharge_e m14 : 48|16@1- (1,0) [-32768|32767] "Wh" Vector__XXX
 SG_ UI_rawToUiEnergyRatioSinceCharge m15 : 8|8@1+ (0.01,0) [0|2.55] "-" Vector__XXX
 SG_ UI_driveDistanceSinceCharge_epa m15 : 16|16@1+ (0.01,0) [0|655.35] "miles" Vector__XXX
 SG_ UI_energyDeltaTotalSinceTripStar m16 : 16|16@1- (1,0) [-32768|32767] "Wh" Vector__XXX
 SG_ UI_energyDeltaDrivingSinceTripSt m16 : 32|16@1- (1,0) [-32768|32767] "Wh" Vector__XXX
 SG_ UI_energyDeltaClimateSinceTripSt m16 : 48|16@1- (1,0) [-32768|32767] "Wh" Vector__XXX
 SG_ UI_energyDeltaBattCondSinceTripS m17 : 16|16@1- (1,0) [-32768|32767] "Wh" Vector__XXX
 SG_ UI_energyDeltaElevationSinceTrip m17 : 32|16@1- (1,0) [-32768|32767] "Wh" Vector__XXX
 SG_ UI_energyDeltaAccSinceTripStart m17 : 48|16@1- (1,0) [-32768|32767] "Wh" Vector__XXX
 SG_ UI_uiDeltaOffsetTotalSinceTripSt m18 : 16|16@1- (1,0) [-32768|32767] "Wh" Vector__XXX
 SG_ UI_uiDeltaOffsetDrivingSinceTrip m18 : 32|16@1- (1,0) [-32768|32767] "Wh" Vector__XXX
 SG_ UI_uiDeltaOffsetClimateSinceTrip m18 : 48|16@1- (1,0) [-32768|32767] "Wh" Vector__XXX
 SG_ UI_uiDeltaOffsetBattCondSinceTri m19 : 16|16@1- (1,0) [-32768|32767] "Wh" Vector__XXX
 SG_ UI_uiDeltaOffsetElevationSinceTr m19 : 32|16@1- (1,0) [-32768|32767] "Wh" Vector__XXX
 SG_ UI_uiDeltaOffsetAccSinceTripStar m19 : 48|16@1- (1,0) [-32768|32767] "Wh" Vector__XXX
 SG_ UI_rawToUiEnergyRatioSinceTripSt m20 : 8|8@1+ (0.01,0) [0|2.55] "-" Vector__XXX
 SG_ UI_driveDistanceSinceTripStart m20 : 16|16@1+ (0.01,0) [0|655.35] "miles" Vector__XXX
 SG_ UI_voyagerEnabled m21 : 5|1@1+ (1,0) [0|1] "" Vector__XXX
 SG_ UI_trailerMass m21 : 16|16@1+ (1,0) [0|65535] "kg" Vector__XXX

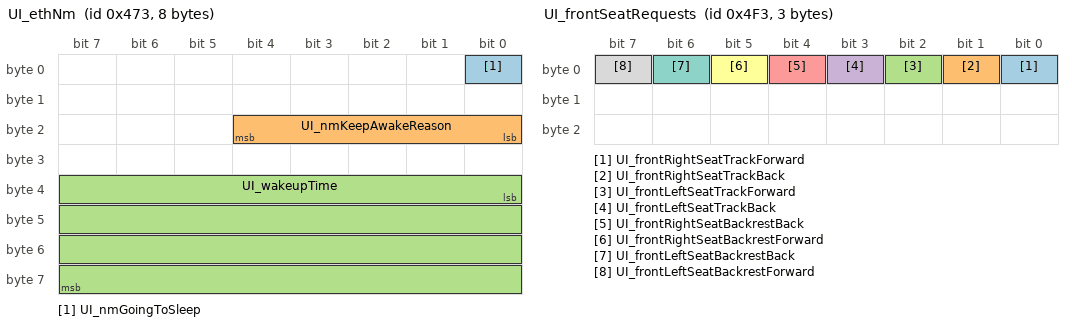
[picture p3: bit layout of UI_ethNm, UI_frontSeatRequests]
BO_ 1139 UI_ethNm: 8 UI
 SG_ UI_nmGoingToSleep : 0|1@1+ (1,0) [0|1] "" Vector__XXX
 SG_ UI_nmKeepAwakeReason : 16|5@1+ (1,0) [1|31] "" Vector__XXX
 SG_ UI_wakeupTime : 32|32@1+ (1,0) [0|4294967295] "" Vector__XXX

BO_ 1267 UI_frontSeatRequests: 3 UI
 SG_ UI_frontRightSeatTrackForward : 0|1@1+ (1,0) [0|1] "" Vector__XXX
 SG_ UI_frontRightSeatTrackBack : 1|1@1+ (1,0) [0|1] "" Vector__XXX
 SG_ UI_frontLeftSeatTrackForward : 2|1@1+ (1,0) [0|1] "" Vector__XXX
 SG_ UI_frontLeftSeatTrackBack : 3|1@1+ (1,0) [0|1] "" Vector__XXX
 SG_ UI_frontRightSeatBackrestBack : 4|1@1+ (1,0) [0|1] "" Vector__XXX
 SG_ UI_frontRightSeatBackrestForward : 5|1@1+ (1,0) [0|1] "" Vector__XXX
 SG_ UI_frontLeftSeatBackrestBack : 6|1@1+ (1,0) [0|1] "" Vector__XXX
 SG_ UI_frontLeftSeatBackrestForward : 7|1@1+ (1,0) [0|1] "" Vector__XXX

BO_ 804 UI_gpsTime: 8 UI
 SG_ UI_gpsTime : 0|64@1+ (1,0) [0|1.84467440737e+19] "" Vector__XXX

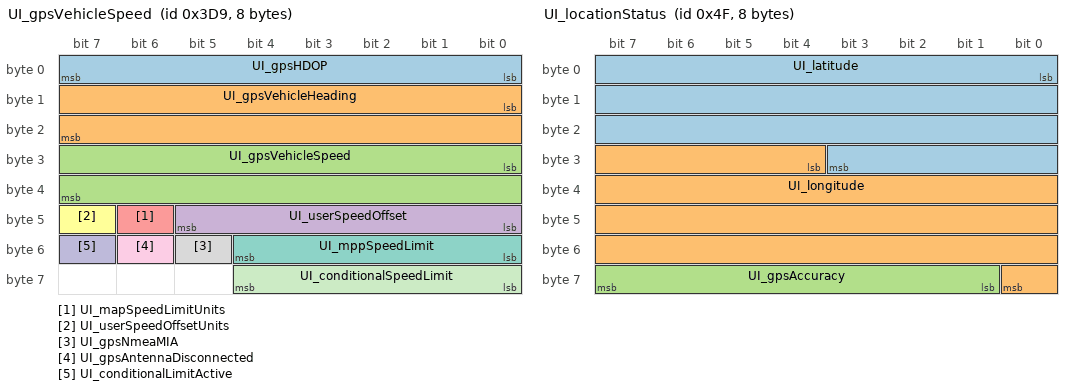
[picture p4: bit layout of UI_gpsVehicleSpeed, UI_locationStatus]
BO_ 985 UI_gpsVehicleSpeed: 8 UI
 SG_ UI_gpsHDOP : 0|8@1+ (0.1,0) [0|25.5] "1" Vector__XXX
 SG_ UI_gpsVehicleHeading : 8|16@1+ (0.0078125,0) [0|511.9921875] "deg" Vector__XXX
 SG_ UI_gpsVehicleSpeed : 24|16@1+ (0.00390625,0) [0|255.99609375] "km/hr" Vector__XXX
 SG_ UI_userSpeedOffset : 40|6@1+ (1,-30) [-30|33] "kph/mph" Vector__XXX
 SG_ UI_mapSpeedLimitUnits : 46|1@1+ (1,0) [0|1] "" Vector__XXX
 SG_ UI_userSpeedOffsetUnits : 47|1@1+ (1,0) [0|1] "" Vector__XXX
 SG_ UI_mppSpeedLimit : 48|5@1+ (5,0) [0|155] "kph/mph" Vector__XXX
 SG_ UI_gpsNmeaMIA : 53|1@1+ (1,0) [0|1] "" Vector__XXX
 SG_ UI_gpsAntennaDisconnected : 54|1@1+ (1,0) [0|1] "" Vector__XXX
 SG_ UI_conditionalLimitActive : 55|1@1+ (1,0) [0|1] "" Vector__XXX
 SG_ UI_conditionalSpeedLimit : 56|5@1+ (5,0) [0|150] "kph/mph" Vector__XXX

BO_ 755 UI_hvacRequest: 8 UI
 SG_ UI_hvacReqTempSetpointLeft : 0|5@1+ (0.5,15) [15|28] "degC" Vector__XXX
 SG_ UI_hvacReqAutoBlowerLevel : 5|3@1+ (1,0) [0|7] "" Vector__XXX
 SG_ UI_hvacReqTempSetpointRight : 8|5@1+ (0.5,15) [15|28] "degC" Vector__XXX
 SG_ UI_hvacReqAirDistributionMode : 13|3@1+ (1,0) [0|7] "" Vector__XXX
 SG_ UI_hvacReqBlowerSegment : 16|4@1+ (1,0) [0|15] "" Vector__XXX
 SG_ UI_hvacReqRecirc : 20|2@1+ (1,0) [0|3] "" Vector__XXX
 SG_ UI_hvacReqACDisable : 22|2@1+ (1,0) [0|3] "" Vector__XXX
 SG_ UI_hvacDefogState : 24|2@1+ (1,0) [0|3] "" Vector__XXX
 SG_ UI_hvacReqUserPowerState : 26|3@1+ (1,0) [0|7] "" Vector__XXX
 SG_ UI_hvacReqSecondRowState : 29|3@1+ (1,0) [0|7] "" Vector__XXX
 SG_ UI_hvacUseModeledDuctTemp : 32|1@1+ (1,0) [0|1] "" Vector__XXX
 SG_ UI_hvacReqKeepClimateOn : 33|2@1+ (1,0) [0|3] "" Vector__XXX
 SG_ UI_hvacReqBioWeaponDefMode : 35|1@1+ (1,0) [0|1] "" Vector__XXX
 SG_ UI_hvacLatchPassengerPresent : 39|1@1+ (1,0) [0|1] "" Vector__XXX
 SG_ UI_enableHvacControlsFeatures1 : 44|1@1+ (1,0) [0|1] "" Vector__XXX
 SG_ UI_enableHvacNotifications : 45|1@1+ (1,0) [0|1] "" Vector__XXX
 SG_ UI_hvacPhoneCallAirFlowAdjustEna : 46|1@1+ (1,0) [0|1] "" Vector__XXX
 SG_ UI_enableHvacVOCPurgeRoutine : 47|1@1+ (1,0) [0|1] "" Vector__XXX
 SG_ UI_enableCustomerTHSAlerts : 53|1@1+ (1,0) [0|1] "" Vector__XXX
 SG_ UI_evapDryingSelectiveEnable : 54|1@1+ (1,0) [0|1] "" Vector__XXX
 SG_ UI_enableHvacWeatherDataBasedHum : 55|1@1+ (1,0) [0|1] "" Vector__XXX
 SG_ UI_hvacReqTempSetpointCOP : 56|2@1+ (1,0) [0|3] "" Vector__XXX
 SG_ UI_hvacClimateNudgeStatus : 58|3@1+ (1,0) [0|7] "" Vector__XXX
 SG_ UI_enableHvacControlsFeatures2 : 61|1@1+ (1,0) [0|1] "" Vector__XXX
 SG_ UI_enableHvacAPFoggingMonitor : 62|1@1+ (1,0) [0|1] "" Vector__XXX
 SG_ UI_enableHvacLimpMode : 63|1@1+ (1,0) [0|1] "" Vector__XXX

BO_ 989 UI_locationOffset: 8 UI
 SG_ UI_latitudeOffset : 0|28@1- (1.0e-06,0) [-134.217728|134.217727] "deg" Vector__XXX
 SG_ UI_longitudeOffset : 28|29@1- (1.0e-06,0) [-268.435456|268.435455] "deg" Vector__XXX

BO_ 79 UI_locationStatus: 8 UI
 SG_ UI_latitude : 0|28@1- (1.0e-06,0) [-134.217728|134.217727] "deg" Vector__XXX
 SG_ UI_longitude : 28|29@1- (1.0e-06,0) [-268.435456|268.435455] "deg" Vector__XXX
 SG_ UI_gpsAccuracy : 57|7@1+ (0.2,0) [0|25.2] "m" Vector__XXX

BO_ 1011 UI_odo: 3 UI
 SG_ UI_odometer : 0|24@1+ (0.1,0) [0|1677721.4] "km" Vector__XXX

BO_ 443 UI_peripheralPowerRequests: 1 UI
 SG_ UI_usbFrontHubPowerStateRequest : 0|2@1+ (1,0) [1|3] "" Vector__XXX

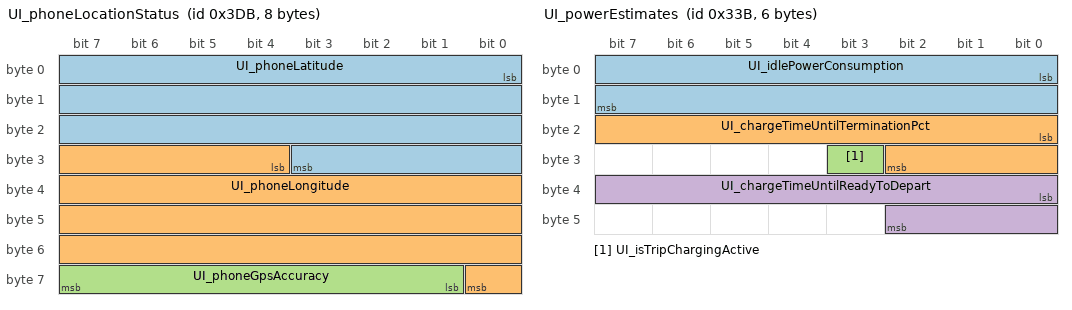
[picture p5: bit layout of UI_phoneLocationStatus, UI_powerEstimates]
BO_ 987 UI_phoneLocationStatus: 8 UI
 SG_ UI_phoneLatitude : 0|28@1- (1.0e-06,0) [-134.217728|134.217727] "deg" Vector__XXX
 SG_ UI_phoneLongitude : 28|29@1- (1.0e-06,0) [-268.435456|268.435455] "deg" Vector__XXX
 SG_ UI_phoneGpsAccuracy : 57|7@1+ (0.5,0) [0|63] "m" Vector__XXX

BO_ 955 UI_power: 2 UI
 SG_ UI_powerExpected : 0|8@1+ (1,0) [0|255] "kW" Vector__XXX
 SG_ UI_powerIdeal : 8|8@1+ (1,0) [0|255] "kW" Vector__XXX

BO_ 827 UI_powerEstimates: 6 UI
 SG_ UI_idlePowerConsumption : 0|16@1+ (0.001,0) [0|50] "kW" Vector__XXX
 SG_ UI_chargeTimeUntilTerminationPct : 16|11@1+ (1,0) [0|2046] "min" Vector__XXX
 SG_ UI_isTripChargingActive : 27|1@1+ (1,0) [0|1] "" Vector__XXX
 SG_ UI_chargeTimeUntilReadyToDepart : 32|11@1+ (1,0) [0|2046] "min" Vector__XXX

BO_ 629 UI_powerRationalityConfig: 8 UI
 SG_ UI_powerRationalityConfigIndex M : 56|8@1+ (1,0) [0|255] "" Vector__XXX
 SG_ UI_vcleftCfgRationalityThreshold m0 : 0|4@1+ (1,0) [1|15] "" Vector__XXX
 SG_ UI_vcleftCfgRationalityTime0 m0 : 4|4@1+ (1,0) [1|15] "" Vector__XXX
 SG_ UI_vcleftCfgRationalityThre_0001 m0 : 8|4@1+ (1,0) [1|15] "" Vector__XXX
 SG_ UI_vcleftCfgRationalityTime1 m0 : 12|4@1+ (1,0) [1|15] "" Vector__XXX
 SG_ UI_vcleftCfgRationalityStaticA m1 : 0|16@1+ (50,0) [0|3276700] "-" Vector__XXX
 SG_ UI_vcleftCfgRationalityStaticB m1 : 16|16@1- (1,0) [-32768|32767] "-" Vector__XXX
 SG_ UI_vcleftCfgRationalityStaticC m1 : 32|16@1- (50,0) [-1638400|1638350] "-" Vector__XXX
 SG_ UI_vcleftCfgRationalityDynamicA m2 : 0|16@1+ (50,0) [0|3276700] "-" Vector__XXX
 SG_ UI_vcleftCfgRationalityDynamicB m2 : 16|16@1- (1,0) [-32768|32767] "-" Vector__XXX
 SG_ UI_vcleftCfgRationalityDynamicC m2 : 32|16@1- (50,0) [-1638400|1638350] "-" Vector__XXX
 SG_ UI_vcrightCfgRationalityThreshol m3 : 0|4@1+ (1,0) [1|15] "" Vector__XXX
 SG_ UI_vcrightCfgRationalityTime0 m3 : 4|4@1+ (1,0) [1|15] "" Vector__XXX
 SG_ UI_vcrightCfgRationalityThr_0001 m3 : 8|4@1+ (1,0) [1|15] "" Vector__XXX
 SG_ UI_vcrightCfgRationalityTime1 m3 : 12|4@1+ (1,0) [1|15] "" Vector__XXX
 SG_ UI_vcrightCfgRationalityStaticA m4 : 0|16@1+ (50,0) [0|3276700] "-" Vector__XXX
 SG_ UI_vcrightCfgRationalityStaticB m4 : 16|16@1- (1,0) [-32768|32767] "-" Vector__XXX
 SG_ UI_vcrightCfgRationalityStaticC m4 : 32|16@1- (50,0) [-1638400|1638350] "-" Vector__XXX
 SG_ UI_vcrightCfgRationalityDynamicA m5 : 0|16@1+ (50,0) [0|3276700] "-" Vector__XXX
 SG_ UI_vcrightCfgRationalityDynamicB m5 : 16|16@1- (1,0) [-32768|32767] "-" Vector__XXX
 SG_ UI_vcrightCfgRationalityDynamicC m5 : 32|16@1- (50,0) [-1638400|1638350] "-" Vector__XXX
 SG_ UI_vcleftCfgCutoffThreshold0 m6 : 0|4@1+ (1,0) [1|15] "" Vector__XXX
 SG_ UI_vcleftCfgCutoffTime0 m6 : 4|4@1+ (1,0) [1|15] "" Vector__XXX
 SG_ UI_vcleftCfgCutoffThreshold1 m6 : 8|4@1+ (1,0) [1|15] "" Vector__XXX
 SG_ UI_vcleftCfgCutoffTime1 m6 : 12|4@1+ (1,0) [1|15] "" Vector__XXX
 SG_ UI_vcleftCfgCutoffStaticA m7 : 0|16@1+ (50,0) [0|3276700] "-" Vector__XXX
 SG_ UI_vcleftCfgCutoffStaticB m7 : 16|16@1- (1,0) [-32768|32767] "-" Vector__XXX
 SG_ UI_vcleftCfgCutoffStaticC m7 : 32|16@1- (50,0) [-1638400|1638350] "-" Vector__XXX
 SG_ UI_vcleftCfgCutoffDynamicA m8 : 0|16@1+ (50,0) [0|3276700] "-" Vector__XXX
 SG_ UI_vcleftCfgCutoffDynamicB m8 : 16|16@1- (1,0) [-32768|32767] "-" Vector__XXX
 SG_ UI_vcleftCfgCutoffDynamicC m8 : 32|16@1- (50,0) [-1638400|1638350] "-" Vector__XXX
 SG_ UI_vcrightCfgCutoffThreshold0 m9 : 0|4@1+ (1,0) [1|15] "" Vector__XXX
 SG_ UI_vcrightCfgCutoffTime0 m9 : 4|4@1+ (1,0) [1|15] "" Vector__XXX
 SG_ UI_vcrightCfgCutoffThreshold1 m9 : 8|4@1+ (1,0) [1|15] "" Vector__XXX
 SG_ UI_vcrightCfgCutoffTime1 m9 : 12|4@1+ (1,0) [1|15] "" Vector__XXX
 SG_ UI_vcrightCfgCutoffStaticA m10 : 0|16@1+ (50,0) [0|3276700] "-" Vector__XXX
 SG_ UI_vcrightCfgCutoffStaticB m10 : 16|16@1- (1,0) [-32768|32767] "-" Vector__XXX
 SG_ UI_vcrightCfgCutoffStaticC m10 : 32|16@1- (50,0) [-1638400|1638350] "-" Vector__XXX
 SG_ UI_vcrightCfgCutoffDynamicA m11 : 0|16@1+ (50,0) [0|3276700] "-" Vector__XXX
 SG_ UI_vcrightCfgCutoffDynamicB m11 : 16|16@1- (1,0) [-32768|32767] "-" Vector__XXX
 SG_ UI_vcrightCfgCutoffDynamicC m11 : 32|16@1- (50,0) [-1638400|1638350] "-" Vector__XXX

BO_ 820 UI_powertrainControl: 8 UI
 SG_ UI_systemPowerLimit : 0|5@1+ (20,20) [20|620] "kW" Vector__XXX
 SG_ UI_pedalMap : 5|2@1+ (1,0) [0|3] "" Vector__XXX
 SG_ UI_enableRegenBackfill : 7|1@1+ (1,0) [0|1] "" Vector__XXX
 SG_ UI_systemTorqueLimit : 8|6@1+ (150,1000) [1000|10300] "Nm" Vector__XXX
 SG_ UI_closureConfirmed : 14|2@1+ (1,0) [0|3] "" Vector__XXX
 SG_ UI_regenTorqueMax : 16|5@1+ (5,0) [0|100] "%" Vector__XXX
 SG_ UI_limitMode : 21|2@1+ (1,0) [0|3] "" Vector__XXX
 SG_ UI_factoryCustomerDrivingModeReq : 23|1@1+ (1,0) [0|1] "" Vector__XXX
 SG_ UI_motorOnMode : 24|2@1+ (1,0) [0|3] "" Vector__XXX
 SG_ UI_wasteMode : 26|2@1+ (1,0) [0|3] "" Vector__XXX
 SG_ UI_wasteModeRegenLimit : 28|2@1+ (1,0) [0|3] "" Vector__XXX
 SG_ UI_stoppingMode : 30|2@1+ (1,0) [0|3] "" Vector__XXX
 SG_ UI_DIAppSliderDebug : 32|2@1+ (1,0) [0|3] "" Vector__XXX
 SG_ UI_speedLimit : 34|12@1+ (0.1,0) [0|335] "kph" Vector__XXX
 SG_ UI_enableSmartShift : 46|2@1+ (1,0) [0|3] "" Vector__XXX
 SG_ UI_navVehParallelToRdCanContinue : 49|2@1+ (1,0) [1|3] "" Vector__XXX
 SG_ UI_powertrainControlCounter : 52|4@1+ (1,0) [0|15] "" Vector__XXX
 SG_ UI_powertrainControlChecksum : 56|8@1+ (1,0) [0|255] "" Vector__XXX

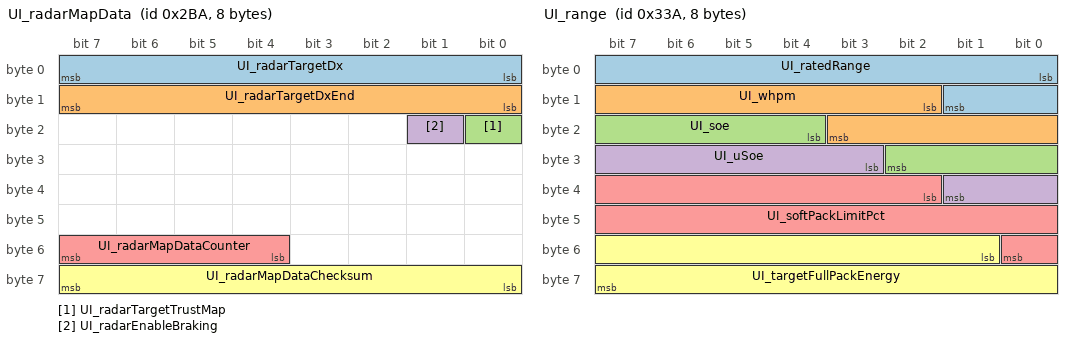
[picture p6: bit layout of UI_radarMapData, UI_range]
BO_ 698 UI_radarMapData: 8 UI
 SG_ UI_radarTargetDx : 0|8@1+ (1,-95) [-95|160] "m" Vector__XXX
 SG_ UI_radarTargetDxEnd : 8|8@1+ (1,0) [0|255] "m" Vector__XXX
 SG_ UI_radarTargetTrustMap : 16|1@1+ (1,0) [0|1] "" Vector__XXX
 SG_ UI_radarEnableBraking : 17|1@1+ (1,0) [0|1] "" Vector__XXX
 SG_ UI_radarMapDataCounter : 52|4@1+ (1,0) [0|15] "" Vector__XXX
 SG_ UI_radarMapDataChecksum : 56|8@1+ (1,0) [0|255] "" Vector__XXX

BO_ 826 UI_range: 8 UI
 SG_ UI_ratedRange : 0|10@1+ (1,0) [0|1023] "mi" Vector__XXX
 SG_ UI_whpm : 10|10@1+ (1,0) [0|1023] "" Vector__XXX
 SG_ UI_soe : 20|7@1+ (1,0) [0|127] "%" Vector__XXX
 SG_ UI_uSoe : 27|7@1+ (1,0) [0|127] "%" Vector__XXX
 SG_ UI_softPackLimitPct : 34|15@1+ (0.003051851,0) [0|100.000001717] "%" Vector__XXX
 SG_ UI_targetFullPackEnergy : 49|15@1+ (0.006103702,0) [0|200.000003434] "kWh" Vector__XXX

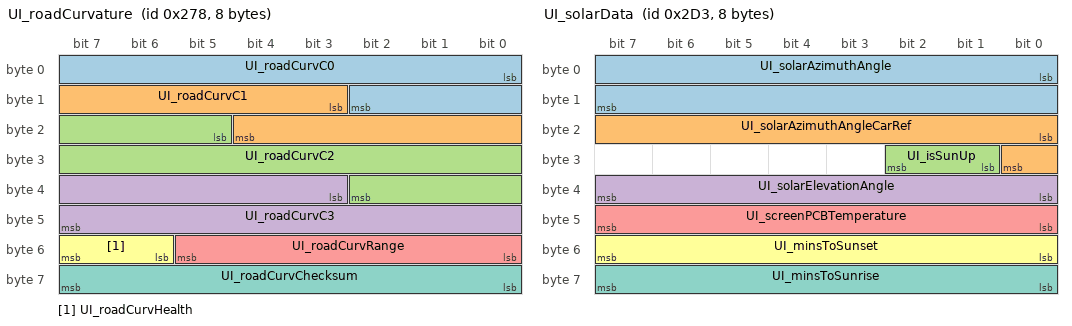
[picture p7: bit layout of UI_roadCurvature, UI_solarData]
BO_ 632 UI_roadCurvature: 8 UI
 SG_ UI_roadCurvC0 : 0|11@1- (0.02,0) [-20.48|20.46] "m" Vector__XXX
 SG_ UI_roadCurvC1 : 11|10@1- (0.00075,0) [-0.384|0.38325] "1" Vector__XXX
 SG_ UI_roadCurvC2 : 21|14@1- (7.5e-06,0) [-0.06144|0.0614325] "1/m" Vector__XXX
 SG_ UI_roadCurvC3 : 35|13@1- (3.0e-08,0) [-0.00012288|0.00012285] "1/m2" Vector__XXX
 SG_ UI_roadCurvRange : 48|6@1+ (4,0) [0|252] "m" Vector__XXX
 SG_ UI_roadCurvHealth : 54|2@1+ (1,0) [0|3] "" Vector__XXX
 SG_ UI_roadCurvChecksum : 56|8@1+ (1,0) [0|255] "" Vector__XXX

BO_ 723 UI_solarData: 8 UI
 SG_ UI_solarAzimuthAngle : 0|16@1- (1,0) [-32768|32767] "degrees" Vector__XXX
 SG_ UI_solarAzimuthAngleCarRef : 16|9@1- (1,0) [-256|254] "degrees" Vector__XXX
 SG_ UI_isSunUp : 25|2@1+ (1,0) [0|2] "" Vector__XXX
 SG_ UI_solarElevationAngle : 32|8@1- (1,0) [-128|126] "degrees" Vector__XXX
 SG_ UI_screenPCBTemperature : 40|8@1- (0.5,40) [-20|100] "degC" Vector__XXX
 SG_ UI_minsToSunset : 48|8@1+ (10,0) [0|2550] "min" Vector__XXX
 SG_ UI_minsToSunrise : 56|8@1+ (10,0) [0|2550] "min" Vector__XXX

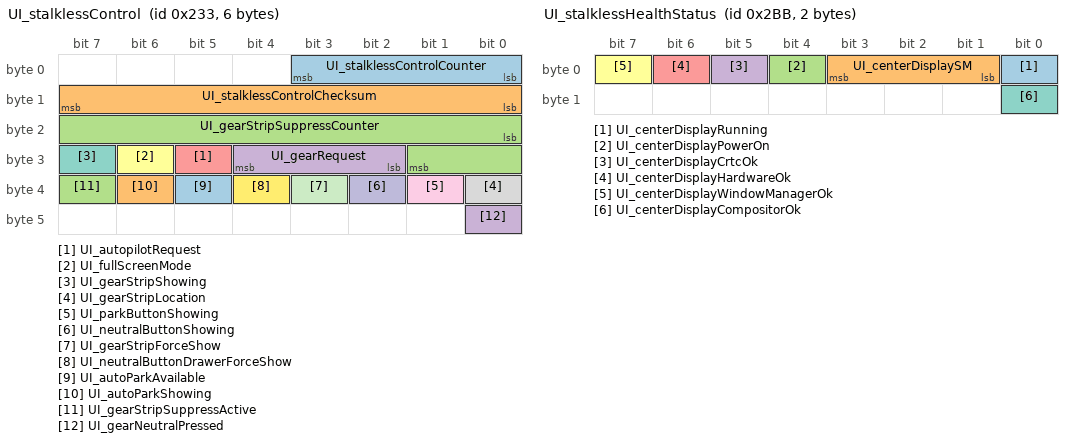
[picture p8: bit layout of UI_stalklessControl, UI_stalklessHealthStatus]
BO_ 563 UI_stalklessControl: 6 UI
 SG_ UI_stalklessControlCounter : 0|4@1+ (1,0) [0|15] "" Vector__XXX
 SG_ UI_stalklessControlChecksum : 8|8@1+ (1,0) [0|255] "" Vector__XXX
 SG_ UI_gearStripSuppressCounter : 16|10@1+ (1,0) [0|1023] "" Vector__XXX
 SG_ UI_gearRequest : 26|3@1+ (1,0) [1|7] "" Vector__XXX
 SG_ UI_autopilotRequest : 29|1@1+ (1,0) [0|1] "" Vector__XXX
 SG_ UI_fullScreenMode : 30|1@1+ (1,0) [0|1] "" Vector__XXX
 SG_ UI_gearStripShowing : 31|1@1+ (1,0) [0|1] "" Vector__XXX
 SG_ UI_gearStripLocation : 32|1@1+ (1,0) [0|1] "" Vector__XXX
 SG_ UI_parkButtonShowing : 33|1@1+ (1,0) [0|1] "" Vector__XXX
 SG_ UI_neutralButtonShowing : 34|1@1+ (1,0) [0|1] "" Vector__XXX
 SG_ UI_gearStripForceShow : 35|1@1+ (1,0) [0|1] "" Vector__XXX
 SG_ UI_neutralButtonDrawerForceShow : 36|1@1+ (1,0) [0|1] "" Vector__XXX
 SG_ UI_autoParkAvailable : 37|1@1+ (1,0) [0|1] "" Vector__XXX
 SG_ UI_autoParkShowing : 38|1@1+ (1,0) [0|1] "" Vector__XXX
 SG_ UI_gearStripSuppressActive : 39|1@1+ (1,0) [0|1] "" Vector__XXX
 SG_ UI_gearNeutralPressed : 40|1@1+ (1,0) [0|1] "" Vector__XXX

BO_ 699 UI_stalklessHealthStatus: 2 UI
 SG_ UI_centerDisplayRunning : 0|1@1+ (1,0) [0|1] "" Vector__XXX
 SG_ UI_centerDisplaySM : 1|3@1+ (1,0) [0|7] "" Vector__XXX
 SG_ UI_centerDisplayPowerOn : 4|1@1+ (1,0) [0|1] "" Vector__XXX
 SG_ UI_centerDisplayCrtcOk : 5|1@1+ (1,0) [0|1] "" Vector__XXX
 SG_ UI_centerDisplayHardwareOk : 6|1@1+ (1,0) [0|1] "" Vector__XXX
 SG_ UI_centerDisplayWindowManagerOk : 7|1@1+ (1,0) [0|1] "" Vector__XXX
 SG_ UI_centerDisplayCompositorOk : 8|1@1+ (1,0) [0|1] "" Vector__XXX

BO_ 851 UI_status: 8 UI
 SG_ UI_touchActive : 0|1@1+ (1,0) [0|1] "" Vector__XXX
 SG_ UI_audioActive : 1|1@1+ (1,0) [0|1] "" Vector__XXX
 SG_ UI_bluetoothActive : 2|1@1+ (1,0) [0|1] "" Vector__XXX
 SG_ UI_cellActive : 3|1@1+ (1,0) [0|1] "" Vector__XXX
 SG_ UI_displayReady : 4|1@1+ (1,0) [0|1] "" Vector__XXX
 SG_ UI_displayOn : 5|1@1+ (1,0) [0|1] "" Vector__XXX
 SG_ UI_wifiActive : 6|1@1+ (1,0) [0|1] "" Vector__XXX
 SG_ UI_wifiConnected : 7|1@1+ (1,0) [0|1] "" Vector__XXX
 SG_ UI_systemActive : 8|1@1+ (1,0) [0|1] "" Vector__XXX
 SG_ UI_readyForDrive : 9|1@1+ (1,0) [0|1] "" Vector__XXX
 SG_ UI_cellConnected : 10|1@1+ (1,0) [0|1] "" Vector__XXX
 SG_ UI_vpnActive : 11|1@1+ (1,0) [0|1] "" Vector__XXX
 SG_ UI_autopilotTrial : 12|2@1+ (1,0) [0|3] "" Vector__XXX
 SG_ UI_factoryReset : 14|2@1+ (1,0) [1|3] "" Vector__XXX
 SG_ UI_gpsActive : 16|1@1+ (1,0) [0|1] "" Vector__XXX
 SG_ UI_screenshotActive : 17|1@1+ (1,0) [0|1] "" Vector__XXX
 SG_ UI_radioActive : 18|1@1+ (1,0) [0|1] "" Vector__XXX
 SG_ UI_cellNetworkTechnology : 19|4@1+ (1,0) [0|14] "" Vector__XXX
 SG_ UI_cellReceiverPower : 24|8@1+ (1,-128) [-128|127] "dB" Vector__XXX
 SG_ UI_falseTouchCounter : 32|8@1+ (1,0) [0|255] "1" Vector__XXX
 SG_ UI_developmentCar : 40|1@1+ (1,0) [0|1] "" Vector__XXX
 SG_ UI_cameraActive : 41|1@1+ (1,0) [0|1] "" Vector__XXX
 SG_ UI_cellSignalBars : 42|3@1+ (1,0) [0|6] "" Vector__XXX
 SG_ UI_trailerModeTelltale : 45|2@1+ (1,0) [0|3] "" Vector__XXX
 SG_ UI_pcbTemperature : 48|8@1- (1,40) [-20|100] "degC" Vector__XXX
 SG_ UI_cpuTemperature : 56|8@1- (1,40) [-20|100] "degC" Vector__XXX

BO_ 991 UI_status2: 8 UI
 SG_ UI_mobileAppStepCount : 0|16@1+ (1,0) [0|65535] "" Vector__XXX
 SG_ UI_userRequestSnapshot : 16|1@1+ (1,0) [0|1] "" Vector__XXX
 SG_ UI_touchDetected : 17|1@1+ (1,0) [0|1] "" Vector__XXX
 SG_ UI_validDeviceForEUSummon : 18|1@1+ (1,0) [0|1] "" Vector__XXX
 SG_ UI_locatedAtHome : 19|1@1+ (1,0) [0|1] "" Vector__XXX
 SG_ UI_locatedAtWork : 20|1@1+ (1,0) [0|1] "" Vector__XXX
 SG_ UI_locatedAtFavorite : 21|1@1+ (1,0) [0|1] "" Vector__XXX
 SG_ UI_displayInDarkMode : 22|1@1+ (1,0) [0|1] "" Vector__XXX
 SG_ UI_userActivity : 23|1@1+ (1,0) [0|1] "" Vector__XXX
 SG_ UI_activeTouchPoints : 24|8@1+ (1,0) [0|255] "1" Vector__XXX
 SG_ UI_linkState : 32|2@1+ (1,0) [0|3] "" Vector__XXX
 SG_ UI_sentryModeState : 34|3@1+ (1,0) [0|7] "" Vector__XXX
 SG_ UI_autopilotSentryRequest : 37|1@1+ (1,0) [0|1] "" Vector__XXX
 SG_ UI_mobileAppConnected : 38|1@1+ (1,0) [0|1] "" Vector__XXX
 SG_ UI_autoshiftDRState : 40|3@1+ (1,0) [0|7] "" Vector__XXX
 SG_ UI_wifiBtModuleType : 43|3@1+ (1,0) [0|7] "" Vector__XXX
 SG_ UI_sohHealthStatus : 46|2@1+ (1,0) [0|3] "" Vector__XXX
 SG_ UI_selfParkState : 48|8@1+ (1,0) [0|254] "" Vector__XXX
 SG_ UI_summonDeviceIndex : 56|2@1+ (1,0) [0|3] "" Vector__XXX
 SG_ UI_sentryModeCameraDetection : 58|1@1+ (1,0) [0|1] "" Vector__XXX
 SG_ UI_wakeOnIPActive : 59|1@1+ (1,0) [0|1] "" Vector__XXX

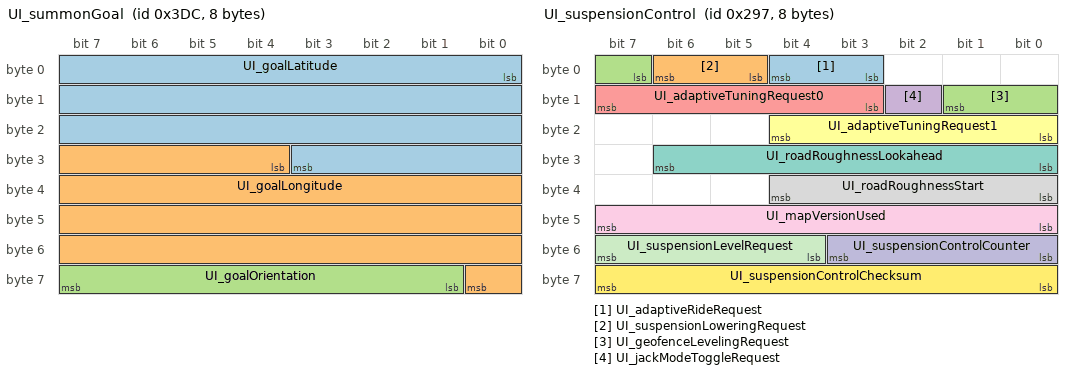
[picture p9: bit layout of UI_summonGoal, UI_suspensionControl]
BO_ 988 UI_summonGoal: 8 UI
 SG_ UI_goalLatitude : 0|28@1- (1.0e-06,0) [-134.217728|134.217727] "deg" Vector__XXX
 SG_ UI_goalLongitude : 28|29@1- (1.0e-06,0) [-268.435456|268.435455] "deg" Vector__XXX
 SG_ UI_goalOrientation : 57|7@1+ (2.8125,0) [0|357.1875] "deg" Vector__XXX

BO_ 663 UI_suspensionControl: 8 UI
 SG_ UI_adaptiveRideRequest : 3|2@1+ (1,0) [0|3] "" Vector__XXX
 SG_ UI_suspensionLoweringRequest : 5|2@1+ (1,0) [0|2] "" Vector__XXX
 SG_ UI_geofenceLevelingRequest : 7|3@1+ (1,0) [0|7] "" Vector__XXX
 SG_ UI_jackModeToggleRequest : 10|1@1+ (1,0) [0|1] "" Vector__XXX
 SG_ UI_adaptiveTuningRequest0 : 11|5@1- (0.1,0) [-1.6|1.5] "-" Vector__XXX
 SG_ UI_adaptiveTuningRequest1 : 16|5@1- (0.1,0) [-1.6|1.5] "-" Vector__XXX
 SG_ UI_roadRoughnessLookahead : 24|7@1+ (0.01,0) [0|1.26] "%" Vector__XXX
 SG_ UI_roadRoughnessStart : 32|5@1+ (10,0) [0|300] "m" Vector__XXX
 SG_ UI_mapVersionUsed : 40|8@1+ (1,0) [0|254] "-" Vector__XXX
 SG_ UI_suspensionControlCounter : 48|4@1+ (1,0) [0|15] "" Vector__XXX
 SG_ UI_suspensionLevelRequest : 52|4@1+ (1,0) [0|15] "" Vector__XXX
 SG_ UI_suspensionControlChecksum : 56|8@1+ (1,0) [0|255] "" Vector__XXX

BO_ 661 UI_systemMonitor: 8 UI
 SG_ UI_systemMonitorIndex M : 0|1@1+ (1,0) [0|1] "" Vector__XXX
 SG_ UI_SystemMemUsage m0 : 8|16@1+ (1,0) [0|65535] "MB" Vector__XXX
 SG_ UI_QtCarMemUsage m0 : 24|16@1+ (1,0) [0|65535] "MB" Vector__XXX
 SG_ UI_QtCarCPUUsage m0 : 40|7@1+ (1,0) [0|127] "%" Vector__XXX
 SG_ UI_emmcStatus m0 : 47|1@1+ (1,0) [0|1] "" Vector__XXX
 SG_ UI_SystemCPUUsage m0 : 48|7@1+ (1,0) [0|127] "%" Vector__XXX
 SG_ UI_HomeHealth m0 : 55|1@1+ (1,0) [0|1] "" Vector__XXX
 SG_ UI_VarHealth m0 : 56|1@1+ (1,0) [0|1] "" Vector__XXX
 SG_ UI_LogHealth m0 : 57|1@1+ (1,0) [0|1] "" Vector__XXX
 SG_ UI_TmpfsHealth m0 : 58|1@1+ (1,0) [0|1] "" Vector__XXX
 SG_ UI_emmcDataWritten m1 : 8|24@1+ (1,0) [0|16777215] "" Vector__XXX
 SG_ UI_emmcTotalErases m1 : 32|16@1+ (1,0) [0|65535] "" Vector__XXX

BO_ 1064 UI_telemetryControl: 8 UI
 SG_ UI_TCR_enable : 0|1@1+ (1,0) [0|1] "" Vector__XXX
 SG_ UI_TCR_moveStateStanding : 1|1@1+ (1,0) [0|1] "" Vector__XXX
 SG_ UI_TCR_moveStateStopped : 2|1@1+ (1,0) [0|1] "" Vector__XXX
 SG_ UI_TCR_moveStateMoving : 3|1@1+ (1,0) [0|1] "" Vector__XXX
 SG_ UI_TCR_moveStateIndeterm : 4|1@1+ (1,0) [0|1] "" Vector__XXX
 SG_ UI_TCR_classConstElem : 5|1@1+ (1,0) [0|1] "" Vector__XXX
 SG_ UI_TCR_classMovingPed : 6|1@1+ (1,0) [0|1] "" Vector__XXX
 SG_ UI_TCR_classMovingTwoWheel : 7|1@1+ (1,0) [0|1] "" Vector__XXX
 SG_ UI_TCR_classMovingFourWheel : 8|1@1+ (1,0) [0|1] "" Vector__XXX
 SG_ UI_TCR_classUnknown : 9|1@1+ (1,0) [0|1] "" Vector__XXX
 SG_ UI_TCR_downSampleFactor : 10|4@1+ (1,0) [0|15] "" Vector__XXX
 SG_ UI_TCR_wExist : 24|5@1+ (1,0) [0|31] "" Vector__XXX
 SG_ UI_TCR_vehSpeed : 32|8@1+ (1,0) [0|255] "" Vector__XXX
 SG_ UI_TCR_minRCS : 40|8@1+ (0.25,-14) [-14|49.75] "dB" Vector__XXX
 SG_ UI_TCR_maxDy : 48|5@1+ (0.5,0) [0|15.5] "m" Vector__XXX
 SG_ UI_TCR_maxObjects : 56|5@1+ (1,0) [0|31] "" Vector__XXX
 SG_ UI_TCR_maxRoadClass : 61|3@1+ (1,0) [0|7] "" Vector__XXX

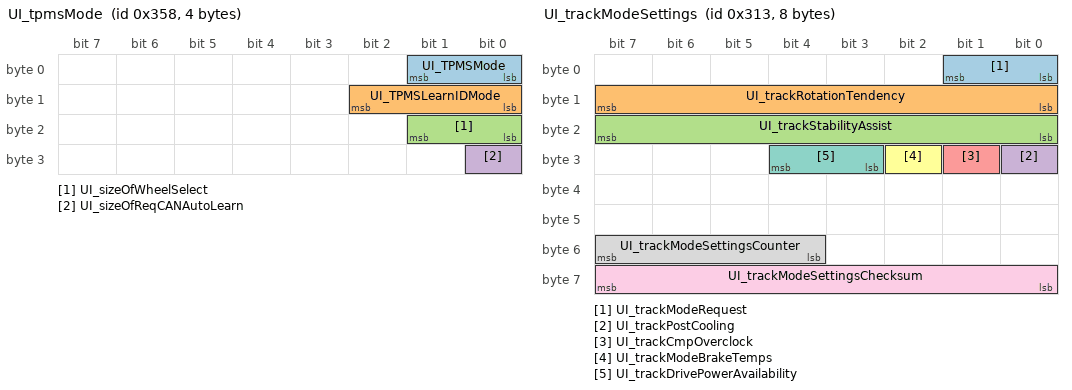
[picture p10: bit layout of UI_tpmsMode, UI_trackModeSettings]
BO_ 856 UI_tpmsMode: 4 UI
 SG_ UI_TPMSMode : 0|2@1+ (1,0) [0|3] "" Vector__XXX
 SG_ UI_TPMSLearnIDMode : 8|3@1+ (1,0) [0|7] "" Vector__XXX
 SG_ UI_sizeOfWheelSelect : 16|2@1+ (1,0) [0|3] "" Vector__XXX
 SG_ UI_sizeOfReqCANAutoLearn : 24|1@1+ (1,0) [0|1] "" Vector__XXX

BO_ 952 UI_tpmsRCPsetting: 4 UI
 SG_ UI_setRCPFront : 16|8@1+ (0.025,0) [0|6.375] "bar" Vector__XXX
 SG_ UI_setRCPRear : 24|8@1+ (0.025,0) [0|6.375] "bar" Vector__XXX

BO_ 787 UI_trackModeSettings: 8 UI
 SG_ UI_trackModeRequest : 0|2@1+ (1,0) [0|3] "" Vector__XXX
 SG_ UI_trackRotationTendency : 8|8@1+ (0.5,0) [0|127.5] "%" Vector__XXX
 SG_ UI_trackStabilityAssist : 16|8@1+ (0.5,0) [0|127.5] "%" Vector__XXX
 SG_ UI_trackPostCooling : 24|1@1+ (1,0) [0|1] "" Vector__XXX
 SG_ UI_trackCmpOverclock : 25|1@1+ (1,0) [0|1] "" Vector__XXX
 SG_ UI_trackModeBrakeTemps : 26|1@1+ (1,0) [0|1] "" Vector__XXX
 SG_ UI_trackDrivePowerAvailability : 27|2@1+ (1,0) [0|3] "" Vector__XXX
 SG_ UI_trackModeSettingsCounter : 52|4@1+ (1,0) [0|15] "" Vector__XXX
 SG_ UI_trackModeSettingsChecksum : 56|8@1+ (1,0) [0|255] "" Vector__XXX

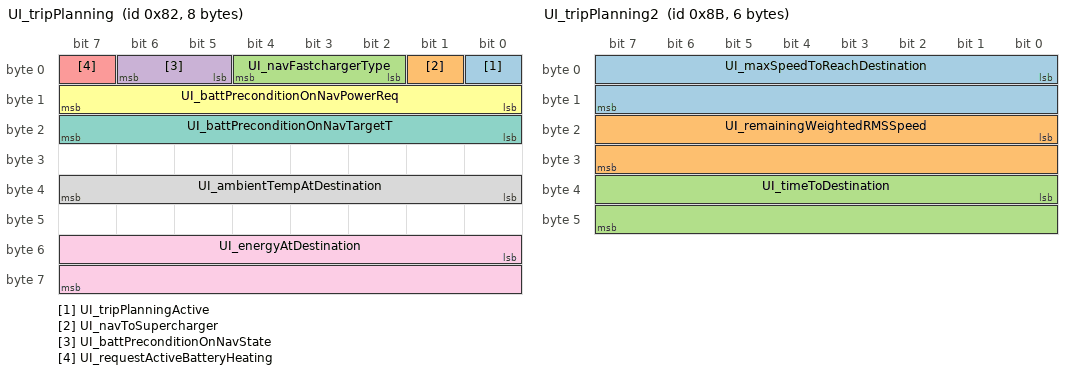
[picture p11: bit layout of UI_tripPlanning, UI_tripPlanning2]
BO_ 130 UI_tripPlanning: 8 UI
 SG_ UI_tripPlanningActive : 0|1@1+ (1,0) [0|1] "" Vector__XXX
 SG_ UI_navToSupercharger : 1|1@1+ (1,0) [0|1] "" Vector__XXX
 SG_ UI_navFastchargerType : 2|3@1+ (1,0) [0|7] "" Vector__XXX
 SG_ UI_battPreconditionOnNavState : 5|2@1+ (1,0) [0|3] "" Vector__XXX
 SG_ UI_requestActiveBatteryHeating : 7|1@1+ (1,0) [0|1] "" Vector__XXX
 SG_ UI_battPreconditionOnNavPowerReq : 8|8@1- (125,0) [-16000|15750] "W" Vector__XXX
 SG_ UI_battPreconditionOnNavTargetT : 16|8@1+ (0.25,0) [0|63.5] "degC" Vector__XXX
 SG_ UI_ambientTempAtDestination : 32|8@1- (0.5,0) [-64|63.5] "degC" Vector__XXX
 SG_ UI_energyAtDestination : 48|16@1- (0.01,0) [-327.67|327.67] "kWh" Vector__XXX

BO_ 139 UI_tripPlanning2: 6 UI
 SG_ UI_maxSpeedToReachDestination : 0|16@1+ (0.01,0) [0|655.34] "m/s" Vector__XXX
 SG_ UI_remainingWeightedRMSSpeed : 16|16@1+ (0.01,0) [0|655.34] "m/s" Vector__XXX
 SG_ UI_timeToDestination : 32|16@1+ (1,0) [0|65534] "s" Vector__XXX

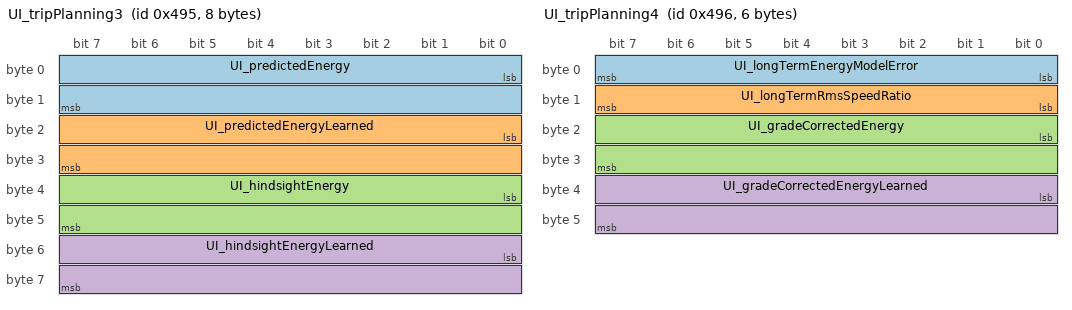
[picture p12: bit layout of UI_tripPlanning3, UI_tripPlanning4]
BO_ 1173 UI_tripPlanning3: 8 UI
 SG_ UI_predictedEnergy : 0|16@1- (0.01,0) [-327.67|327.67] "kWh" Vector__XXX
 SG_ UI_predictedEnergyLearned : 16|16@1- (0.01,0) [-327.68|327.67] "kWh" Vector__XXX
 SG_ UI_hindsightEnergy : 32|16@1- (0.01,0) [-327.67|327.67] "kWh" Vector__XXX
 SG_ UI_hindsightEnergyLearned : 48|16@1- (0.01,0) [-327.68|327.67] "kWh" Vector__XXX

BO_ 1174 UI_tripPlanning4: 6 UI
 SG_ UI_longTermEnergyModelError : 0|8@1- (0.5,0) [-64|63.5] "whpm" Vector__XXX
 SG_ UI_longTermRmsSpeedRatio : 8|8@1+ (0.01,0) [0|2.54] "1" Vector__XXX
 SG_ UI_gradeCorrectedEnergy : 16|16@1- (0.01,0) [-327.68|327.67] "kWh" Vector__XXX
 SG_ UI_gradeCorrectedEnergyLearned : 32|16@1- (0.01,0) [-327.68|327.67] "kWh" Vector__XXX

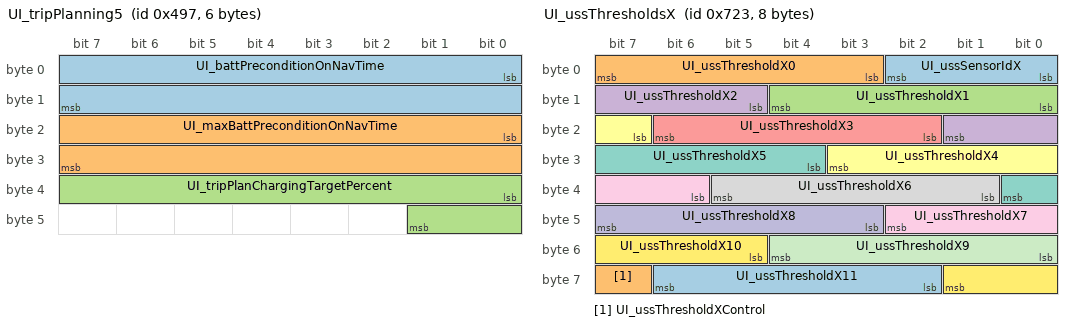
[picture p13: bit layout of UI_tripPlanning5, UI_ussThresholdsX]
BO_ 1175 UI_tripPlanning5: 6 UI
 SG_ UI_battPreconditionOnNavTime : 0|16@1+ (1,0) [0|65534] "s" Vector__XXX
 SG_ UI_maxBattPreconditionOnNavTime : 16|16@1+ (1,0) [0|65534] "s" Vector__XXX
 SG_ UI_tripPlanChargingTargetPercent : 32|10@1+ (0.1,0) [0|102.2] "%" Vector__XXX

BO_ 1827 UI_ussThresholdsX: 8 UI
 SG_ UI_ussSensorIdX : 0|3@1+ (1,0) [0|7] "" Vector__XXX
 SG_ UI_ussThresholdX0 : 3|5@1+ (1,0) [0|31] "" Vector__XXX
 SG_ UI_ussThresholdX1 : 8|5@1+ (1,0) [0|31] "" Vector__XXX
 SG_ UI_ussThresholdX2 : 13|5@1+ (1,0) [0|31] "" Vector__XXX
 SG_ UI_ussThresholdX3 : 18|5@1+ (1,0) [0|31] "" Vector__XXX
 SG_ UI_ussThresholdX4 : 23|5@1+ (1,0) [0|31] "" Vector__XXX
 SG_ UI_ussThresholdX5 : 28|5@1+ (1,0) [0|31] "" Vector__XXX
 SG_ UI_ussThresholdX6 : 33|5@1+ (1,0) [0|31] "" Vector__XXX
 SG_ UI_ussThresholdX7 : 38|5@1+ (1,0) [0|31] "" Vector__XXX
 SG_ UI_ussThresholdX8 : 43|5@1+ (1,0) [0|31] "" Vector__XXX
 SG_ UI_ussThresholdX9 : 48|5@1+ (1,0) [0|31] "" Vector__XXX
 SG_ UI_ussThresholdX10 : 53|5@1+ (1,0) [0|31] "" Vector__XXX
 SG_ UI_ussThresholdX11 : 58|5@1+ (1,0) [0|31] "" Vector__XXX
 SG_ UI_ussThresholdXControl : 63|1@1+ (1,0) [0|1] "" Vector__XXX

BO_TX_BU_ 1021 : UI;
BO_TX_BU_ 819 : UI;
BO_TX_BU_ 659 : UI;
BO_TX_BU_ 531 : UI;
BO_TX_BU_ 664 : UI;
BO_TX_BU_ 679 : UI;
BO_TX_BU_ 1280 : UI;
BO_TX_BU_ 2043 : UI;
BO_TX_BU_ 1096 : UI;
BO_TX_BU_ 1016 : UI;
BO_TX_BU_ 568 : UI;
BO_TX_BU_ 536 : UI;
BO_TX_BU_ 645 : UI;
BO_TX_BU_ 647 : UI;
BO_TX_BU_ 1971 : UI;
BO_TX_BU_ 984 : UI;
BO_TX_BU_ 1279 : UI;
BO_TX_BU_ 1139 : UI;
BO_TX_BU_ 1267 : UI;
BO_TX_BU_ 804 : UI;
BO_TX_BU_ 985 : UI;
BO_TX_BU_ 755 : UI;
BO_TX_BU_ 989 : UI;
BO_TX_BU_ 79 : UI;
BO_TX_BU_ 1011 : UI;
BO_TX_BU_ 443 : UI;
BO_TX_BU_ 987 : UI;
BO_TX_BU_ 955 : UI;
BO_TX_BU_ 827 : UI;
BO_TX_BU_ 629 : UI;
BO_TX_BU_ 820 : UI;
BO_TX_BU_ 698 : UI;
BO_TX_BU_ 826 : UI;
BO_TX_BU_ 632 : UI;
BO_TX_BU_ 723 : UI;
BO_TX_BU_ 563 : UI;
BO_TX_BU_ 699 : UI;
BO_TX_BU_ 851 : UI;
BO_TX_BU_ 991 : UI;
BO_TX_BU_ 988 : UI;
BO_TX_BU_ 663 : UI;
BO_TX_BU_ 661 : UI;
BO_TX_BU_ 1064 : UI;
BO_TX_BU_ 856 : UI;
BO_TX_BU_ 952 : UI;
BO_TX_BU_ 787 : UI;
BO_TX_BU_ 130 : UI;
BO_TX_BU_ 139 : UI;
BO_TX_BU_ 1173 : UI;
BO_TX_BU_ 1174 : UI;
BO_TX_BU_ 1175 : UI;
BO_TX_BU_ 1827 : UI;
CM_ BO_ 1021 "Touchscreen user interface computer message: autopilot control";
CM_ SG_ 1021 UI_autopilotControlIndex "Touchscreen user interface computer: autopilot control index";
CM_ SG_ 1021 UI_hovEnabled "UI HOV routes enabled";
CM_ SG_ 1021 UI_donDisableAutoWiperDuration "Touchscreen user interface computer: don disable auto wiper duration";
CM_ SG_ 1021 UI_donDisableOnAutoWiperSpeed "Touchscreen user interface computer: don disable on auto wiper speed";
CM_ SG_ 1021 UI_blindspotMinSpeed "Touchscreen user interface computer: blindspot min speed";
CM_ SG_ 1021 UI_blindspotDistance "Touchscreen user interface computer: blindspot distance";
CM_ SG_ 1021 UI_blindspotTTC "Touchscreen user interface computer: blindspot TTC";
CM_ SG_ 1021 UI_donStopEndOfRampBuffer "Touchscreen user interface computer: don stop end of ramp buffer";
CM_ SG_ 1021 UI_donDisableCutin "Touchscreen user interface computer: don disable cutin";
CM_ SG_ 1021 UI_smartSetSpeedOffset "TACC will apply this offset over the speed limit";
CM_ SG_ 1021 UI_smartSetSpeedOffsetType "Offset applied will be a percentage or fixed value based on this setting";
CM_ SG_ 1021 UI_autopilotMonarchBackup "Touchscreen user interface computer: autopilot monarch backup";
CM_ SG_ 1021 UI_fsdVisualizationEnabled "Touchscreen user interface computer: fsd visualization enabled";
CM_ SG_ 1021 UI_fsdStopsControlEnabled "Indicates if autopilot control for traffic lights and stops signs has been enabled by the driver";
CM_ SG_ 1021 UI_fsdContinueOnGreenWithCIPV "Touchscreen user interface computer: fsd continue on green with CIPV";
CM_ SG_ 1021 UI_smartSetSpeed "TACC will use speed limit + offset as user set speed when enabled";
CM_ SG_ 1021 UI_automaticSetSpeedOffset "Maximum set speed offset would be determined automatically when this option is enabled";
CM_ SG_ 1021 UI_apply2021_1958_ISA "Touchscreen user interface computer: apply2021 1958 ISA";
CM_ SG_ 1021 UI_apply2021_646_ELKS "Touchscreen user interface computer: apply2021 646 ELKS";
CM_ SG_ 1021 UI_apply2021_1341_DDAW "Touchscreen user interface computer: apply2021 1341 DDAW";
CM_ SG_ 1021 UI_homelinkNearby "Touchscreen user interface computer: homelink nearby";
CM_ SG_ 1021 UI_enableFullSelfDriving "Indicates if the driver has enabled FSD behaviors";
CM_ SG_ 1021 UI_hasFullSelfDriving "Indicates if the vehicle hardware, software, and dependencies allow FSD";
CM_ SG_ 1021 UI_autosteerActivation "User-selected autosteer activation method";
CM_ SG_ 1021 UI_autopilotDrivingProfile "Driving profile for autopilot control";
CM_ SG_ 1021 UI_fsdBetaRequest "User accepted disclaimer and requested FSD (Supervised) builds";
CM_ SG_ 1021 UI_fullSelfDrivingSuspended "Full self driving is suspended";
CM_ SG_ 1021 UI_disableOptionalLaneChanges "Disable optional lane changes while FSD is controlling";
CM_ SG_ 1021 UI_applyR152_AEBS "Touchscreen user interface computer: apply R152 AEBS";
CM_ SG_ 1021 UI_autopilotControlMux0Valid "Touchscreen user interface computer: autopilot control mux0 valid";
CM_ SG_ 1021 UI_selectableCameraRequest "Infotainment selectable camera state request from AP signal; raw 15 = signal not available (SNA)";
CM_ SG_ 1021 UI_overrideSleepWithSuspend "Touchscreen user interface computer: override sleep with suspend";
CM_ SG_ 1021 UI_driverMonitorConfirmation "Driver attentiveness confirmation";
CM_ SG_ 1021 UI_parkAssistUseVision "Reports if the vehicle should use vision park assist.";
CM_ SG_ 1021 UI_applyEceR79 "Touchscreen user interface computer: apply ece R79";
CM_ SG_ 1021 UI_enableMapStops "Touchscreen user interface computer: enable map stops";
CM_ SG_ 1021 UI_disableMain "Touchscreen user interface computer: disable main";
CM_ SG_ 1021 UI_disableNarrow "Touchscreen user interface computer: disable narrow";
CM_ SG_ 1021 UI_disableFisheye "Touchscreen user interface computer: disable fisheye";
CM_ SG_ 1021 UI_disableLeftPillar "Touchscreen user interface computer: disable left pillar";
CM_ SG_ 1021 UI_disableRightPillar "Touchscreen user interface computer: disable right pillar";
CM_ SG_ 1021 UI_disableLeftRepeater "Touchscreen user interface computer: disable left repeater";
CM_ SG_ 1021 UI_disableRightRepeater "Touchscreen user interface computer: disable right repeater";
CM_ SG_ 1021 UI_disableBackup "Touchscreen user interface computer: disable backup";
CM_ SG_ 1021 UI_disableRadar "Touchscreen user interface computer: disable radar";
CM_ SG_ 1021 UI_noStalkConfirmAlertHaptic "Detects if alert haptic feedback should trigger.";
CM_ SG_ 1021 UI_regulatoryLKA "Touchscreen user interface computer: regulatory LKA";
CM_ SG_ 1021 UI_regulatoryLaneAssistLevel "Touchscreen user interface computer: regulatory lane assist level";
CM_ SG_ 1021 UI_ulcSnooze "Touchscreen user interface computer: ulc snooze";
CM_ SG_ 1021 UI_noStalkConfirmAlertChime "Detects if alert chime should trigger.";
CM_ SG_ 1021 UI_factorySummonEnable "Controls Factory Summon.";
CM_ SG_ 1021 UI_apmv3Branch "Touchscreen user interface computer: apmv3 branch";
CM_ SG_ 1021 UI_enableCabinCamera "Indicates if autopilot can enable cabin camera";
CM_ SG_ 1021 UI_enableAutopilotStopWarning "Enables the Autopilot active red light warning function.";
CM_ SG_ 1021 UI_showLaneGraph "Touchscreen user interface computer: show lane graph";
CM_ SG_ 1021 UI_showTrackLabels "Touchscreen user interface computer: show track labels";
CM_ SG_ 1021 UI_hardCoreSummon "Touchscreen user interface computer: hard core summon";
CM_ SG_ 1021 UI_enableCabinCameraTelemetry "Touchscreen user interface computer: enable cabin camera telemetry";
CM_ SG_ 1021 UI_enableVisionSpeedControl "Indicates if autopilot can enable vision speed control";
CM_ SG_ 1021 UI_autopilotTelemetryInChina "Touchscreen user interface computer: autopilot telemetry in china";
CM_ SG_ 1021 UI_enableTeslaAutopark "Indicates if autopilot can enable Telsa Autopark control";
CM_ SG_ 1021 UI_autoTurnSignalMode "Turn signal activation mode";
CM_ SG_ 1021 UI_enableCautionLightControl "Touchscreen user interface computer: enable caution light control";
CM_ SG_ 1021 UI_applyEceR79SmartSummonOnly "Touchscreen user interface computer: apply ece R79 smart summon only";
CM_ SG_ 1021 UI_autopilotMonarchEnabled "Touchscreen user interface computer: autopilot monarch enabled";
CM_ SG_ 1021 UI_autopilotEphemerisEnabled "Touchscreen user interface computer: autopilot ephemeris enabled";
CM_ SG_ 1021 UI_enableCabinAudioRecording "Indicates if autopilot can record cabin audio";
CM_ SG_ 1021 UI_autopilotControlMux1Valid "Touchscreen user interface computer: autopilot control mux1 valid";
CM_ SG_ 1021 UI_enableApproachingEmergencyVeh "Touchscreen user interface computer: enable approaching emergency vehicle detection";
CM_ SG_ 1021 UI_enableStartFsdFromParkBrakeCo "Touchscreen user interface computer: enable start fsd from park brake confirmation";
CM_ SG_ 1021 UI_enableStartFsdFromPark "Touchscreen user interface computer: enable start fsd from park";
CM_ SG_ 1021 UI_fsdMaxSpeedOffsetPercentage "Touchscreen user interface computer: fsd max speed offset percentage";
CM_ SG_ 1021 UI_coldStartMonarchInFactory "Touchscreen user interface computer: cold start monarch in factory";
CM_ SG_ 1021 UI_autopilotControlMux2Valid "Touchscreen user interface computer: autopilot control mux2 valid";
CM_ BO_ 819 "Touchscreen user interface computer message: charge request";
CM_ SG_ 819 UI_openChargePortDoorRequest "Request to open charge port.";
CM_ SG_ 819 UI_closeChargePortDoorRequest "Request to close charge port.";
CM_ SG_ 819 UI_chargeEnableRequest "Charging request initiated";
CM_ SG_ 819 UI_brickVLoggingRequest "Touchscreen user interface computer: brick v logging request";
CM_ SG_ 819 UI_brickBalancingDisabled "Touchscreen user interface computer: brick balancing disabled";
CM_ SG_ 819 UI_dSocAlertThreshold "Touchscreen user interface computer: d soc alert threshold";
CM_ SG_ 819 UI_acChargeCurrentLimit "UI charging line current request; raw 127 = signal not available (SNA)";
CM_ SG_ 819 UI_dSocAlertEnable "Set when the BMS_a117_SW_Delta_SOC_Weak_Short alert for the BMS should have a functional response";
CM_ SG_ 819 UI_chargeTerminationPct "Charge Termination Limit Percent";
CM_ SG_ 819 UI_chargeFeature1 "Touchscreen user interface computer: charge feature1";
CM_ SG_ 819 UI_chargeFeature2 "Touchscreen user interface computer: charge feature2";
CM_ SG_ 819 UI_chargeFeature3 "Touchscreen user interface computer: charge feature3";
CM_ SG_ 819 UI_scheduledDepartureEnabled "Reports scheduled departure feature enablement.";
CM_ SG_ 819 UI_chargePortLatchRequest "Request to engage or disengage the latch.";
CM_ SG_ 819 UI_socSnapshotExpirationTime "Touchscreen user interface computer: soc snapshot expiration time";
CM_ SG_ 819 UI_cpInletHeaterRequest "Enable charge port inlet heater";
CM_ SG_ 819 UI_chargePowerSampleRequest "Touchscreen user interface computer: charge power sample request";
CM_ SG_ 819 UI_enableIso15118 "Touchscreen user interface computer: enable iso15118";
CM_ BO_ 659 "Touchscreen user interface computer message: chassis control";
CM_ SG_ 659 UI_steeringTuneRequest "UI customer level request for steering feel. MS had comfort, normal, sport. M3 intent is Normal, sport see SW-95934";
CM_ SG_ 659 UI_tractionControlMode "Transport user selected traction control modes";
CM_ SG_ 659 UI_parkBrakeRequest "User selection for Park brake; raw 3 = signal not available (SNA)";
CM_ SG_ 659 UI_narrowGarages "Touchscreen user interface computer: narrow garages";
CM_ SG_ 659 UI_winchModeRequest "Winch mode (towing) request";
CM_ SG_ 659 UI_zeroSpeedConfirmed "Touchscreen user interface computer: zero speed confirmed; raw 3 = signal not available (SNA)";
CM_ SG_ 659 UI_trailerMode "Indicates whether trailer mode is selected. To be used when towing a trailer.";
CM_ SG_ 659 UI_distanceUnits "Touchscreen user interface computer: distance units";
CM_ SG_ 659 UI_dasDebugEnable "Touchscreen user interface computer: das debug enable";
CM_ SG_ 659 UI_accOvertakeEnable "Enable ACC Overtake assistance (reduce follow distance when the turn signal is on), UI firmware only sets datavalue to True; raw 3 = signal not available (SNA)";
CM_ SG_ 659 UI_aebEnable "Enable Autonomous Emergency Brakes; raw 3 = signal not available (SNA)";
CM_ SG_ 659 UI_aesEnable "Enable Automatic Emergency Steering (associated datavalue set to true and never changed by UI firmware); raw 3 = signal not available (SNA)";
CM_ SG_ 659 UI_ahlbEnable "Enable Automatic High/Low Beams; raw 3 = signal not available (SNA)";
CM_ SG_ 659 UI_autoLaneChangeEnable "Enable Automatic Lane Change; raw 3 = signal not available (SNA)";
CM_ SG_ 659 UI_winchProxUserOverride "User feedback from tow mode panel confirming that charge cable is disconnected when vehicle is unable to determine cable status";
CM_ SG_ 659 UI_rebootAutopilot "Touchscreen user interface computer: reboot autopilot";
CM_ SG_ 659 UI_autoParkRequest "Request Automatic Parking; raw 15 = signal not available (SNA)";
CM_ SG_ 659 UI_bsdEnable "Enable Blind Spot Detection (datavalue defaults to true and not changed by UI firmware); raw 3 = signal not available (SNA)";
CM_ SG_ 659 UI_fcwEnable "Enable Forward Collision Warning; raw 3 = signal not available (SNA)";
CM_ SG_ 659 UI_fcwSensitivity "Forward Collision Warning Level; raw 3 = signal not available (SNA)";
CM_ SG_ 659 UI_latControlEnable "Enable Lateral Control (lane centering, lane keeping, lane changing); raw 3 = signal not available (SNA)";
CM_ SG_ 659 UI_ldwEnable "Enable Lane Departure Warning; raw 3 = signal not available (SNA)";
CM_ SG_ 659 UI_pedalSafetyEnable "Touchscreen user interface computer: pedal safety enable; raw 3 = signal not available (SNA)";
CM_ SG_ 659 UI_pedalMap_epas "Touchscreen user interface computer: pedal map epas";
CM_ SG_ 659 UI_redLightStopSignEnable "Touchscreen user interface computer: red light stop sign enable; raw 3 = signal not available (SNA)";
CM_ SG_ 659 UI_selfParkTune "Touchscreen user interface computer: self park tune; raw 15 = signal not available (SNA)";
CM_ SG_ 659 UI_chassisControlCounter "Touchscreen user interface computer: chassis control counter";
CM_ SG_ 659 UI_chassisControlChecksum "Touchscreen user interface computer: chassis control checksum";
CM_ BO_ 531 "Touchscreen user interface computer message: cruise control";
CM_ SG_ 531 UI_cruiseSpeedCommand "User command to change the cruise set speed.";
CM_ SG_ 531 UI_smartSummonRequest "Touchscreen user interface computer: smart summon request";
CM_ SG_ 531 UI_cruiseControlCounter "Touchscreen user interface computer: cruise control counter";
CM_ SG_ 531 UI_cruiseControlChecksum "Touchscreen user interface computer: cruise control checksum";
CM_ BO_ 664 "Touchscreen user interface computer message: csa offramp curvature";
CM_ SG_ 664 UI_csaOfframpCurvC2 "Touchscreen user interface computer: csa offramp curv C2";
CM_ SG_ 664 UI_csaOfframpCurvC3 "Touchscreen user interface computer: csa offramp curv C3";
CM_ SG_ 664 UI_csaOfframpCurvRange "Touchscreen user interface computer: csa offramp curv range";
CM_ SG_ 664 UI_csaOfframpCurvCounter "Touchscreen user interface computer: csa offramp curv counter";
CM_ SG_ 664 UI_csaOfframpCurvUsingTspline "Touchscreen user interface computer: csa offramp curv using tspline";
CM_ SG_ 664 UI_csaOfframpCurvReserved "Touchscreen user interface computer: csa offramp curv reserved";
CM_ SG_ 664 UI_csaOfframpCurvChecksum "Touchscreen user interface computer: csa offramp curv checksum";
CM_ BO_ 679 "Touchscreen user interface computer message: csa road curvature";
CM_ SG_ 679 UI_csaRoadCurvC2 "Touchscreen user interface computer: csa road curv C2";
CM_ SG_ 679 UI_csaRoadCurvC3 "Touchscreen user interface computer: csa road curv C3";
CM_ SG_ 679 UI_csaRoadCurvRange "Touchscreen user interface computer: csa road curv range";
CM_ SG_ 679 UI_csaRoadCurvCounter "Touchscreen user interface computer: csa road curv counter";
CM_ SG_ 679 UI_csaRoadCurvUsingTspline "Touchscreen user interface computer: csa road curv using tspline";
CM_ SG_ 679 UI_csaRoadCurvReserved "Touchscreen user interface computer: csa road curv reserved";
CM_ SG_ 679 UI_csaRoadCurvChecksum "Touchscreen user interface computer: csa road curv checksum";
CM_ BO_ 1280 "Touchscreen user interface computer message: debug ECU";
CM_ SG_ 1280 UI_debugEcuTarget "Touchscreen user interface computer: debug ecu target";
CM_ SG_ 1280 UI_DI_debugEnable "Touchscreen user interface computer: DI debug enable";
CM_ SG_ 1280 UI_DIS_debugEnable "Touchscreen user interface computer: DIS debug enable";
CM_ SG_ 1280 UI_PM_debugEnable "Touchscreen user interface computer: PM debug enable";
CM_ SG_ 1280 UI_PM_debugAt100Hz "Touchscreen user interface computer: PM debug at100 hz";
CM_ SG_ 1280 UI_PMS_debugEnable "Touchscreen user interface computer: PMS debug enable";
CM_ SG_ 1280 UI_PMS_debugAt100Hz "Touchscreen user interface computer: PMS debug at100 hz";
CM_ SG_ 1280 UI_BMS_debugAllEnable "Touchscreen user interface computer: BMS debug all enable";
CM_ SG_ 1280 UI_BMS_debugDisable "Touchscreen user interface computer: BMS debug disable";
CM_ SG_ 1280 UI_VCRIGHT_debugEnable "Touchscreen user interface computer: VCRIGHT debug enable";
CM_ SG_ 1280 UI_VCFRONT_debugEnable "Touchscreen user interface computer: VCFRONT debug enable";
CM_ SG_ 1280 UI_DIF_debugEnable "Touchscreen user interface computer: DIF debug enable";
CM_ SG_ 1280 UI_DIR_debugEnable "Touchscreen user interface computer: DIR debug enable";
CM_ SG_ 1280 UI_PMF_debugEnable "Touchscreen user interface computer: PMF debug enable";
CM_ SG_ 1280 UI_PMR_debugEnable "Touchscreen user interface computer: PMR debug enable";
CM_ BO_ 2043 "Touchscreen user interface computer message: debug tas";
CM_ SG_ 2043 UI_debugDampingRequestFLC "Touchscreen user interface computer: debug damping request FLC; raw 255 = signal not available (SNA)";
CM_ SG_ 2043 UI_debugDampingRequestFLR "Touchscreen user interface computer: debug damping request FLR; raw 255 = signal not available (SNA)";
CM_ SG_ 2043 UI_debugDampingRequestFRC "Touchscreen user interface computer: debug damping request FRC; raw 255 = signal not available (SNA)";
CM_ SG_ 2043 UI_debugDampingRequestFRR "Touchscreen user interface computer: debug damping request FRR; raw 255 = signal not available (SNA)";
CM_ SG_ 2043 UI_debugDampingRequestRLC "Touchscreen user interface computer: debug damping request RLC; raw 255 = signal not available (SNA)";
CM_ SG_ 2043 UI_debugDampingRequestRLR "Touchscreen user interface computer: debug damping request RLR; raw 255 = signal not available (SNA)";
CM_ SG_ 2043 UI_debugDampingRequestRRC "Touchscreen user interface computer: debug damping request RRC; raw 255 = signal not available (SNA)";
CM_ SG_ 2043 UI_debugDampingRequestRRR "Touchscreen user interface computer: debug damping request RRR; raw 255 = signal not available (SNA)";
CM_ BO_ 1096 "Touchscreen user interface computer message: driver assist anon debug params";
CM_ SG_ 1096 UI_anonDebugParam1 "Touchscreen user interface computer: anon debug param1";
CM_ SG_ 1096 UI_anonDebugFlag1 "Touchscreen user interface computer: anon debug flag1";
CM_ SG_ 1096 UI_anonDebugParam2 "Touchscreen user interface computer: anon debug param2";
CM_ SG_ 1096 UI_anonDebugFlag2 "Touchscreen user interface computer: anon debug flag2";
CM_ SG_ 1096 UI_anonDebugParam3 "Touchscreen user interface computer: anon debug param3";
CM_ SG_ 1096 UI_anonDebugFlag3 "Touchscreen user interface computer: anon debug flag3";
CM_ SG_ 1096 UI_anonDebugParam4 "Touchscreen user interface computer: anon debug param4";
CM_ SG_ 1096 UI_anonDebugFlag4 "Touchscreen user interface computer: anon debug flag4";
CM_ SG_ 1096 UI_anonDebugParam5 "Touchscreen user interface computer: anon debug param5";
CM_ SG_ 1096 UI_anonDebugParam6 "Touchscreen user interface computer: anon debug param6";
CM_ SG_ 1096 UI_anonDebugParam7 "Touchscreen user interface computer: anon debug param7";
CM_ SG_ 1096 UI_visionSpeedSlider "Touchscreen user interface computer: vision speed slider";
CM_ BO_ 1016 "Touchscreen user interface computer message: driver assist control";
CM_ SG_ 1016 UI_autopilotControlRequest "Touchscreen user interface computer: autopilot control request";
CM_ SG_ 1016 UI_ulcStalkConfirm "Drive on autopilot stalk confirmation mode (set by feature config).";
CM_ SG_ 1016 UI_summonHeartbeat "Touchscreen user interface computer: summon heartbeat";
CM_ SG_ 1016 UI_curvSpeedAdaptDisable "Touchscreen user interface computer: curv speed adapt disable";
CM_ SG_ 1016 UI_dasDeveloper "Touchscreen user interface computer: das developer";
CM_ SG_ 1016 UI_enableVinAssociation "Touchscreen user interface computer: enable vin association";
CM_ SG_ 1016 UI_lssLkaEnabled "User setting for lane keep assist";
CM_ SG_ 1016 UI_lssLdwEnabled "User setting for lane departure warning";
CM_ SG_ 1016 UI_coastToCoast "Touchscreen user interface computer: coast to coast";
CM_ SG_ 1016 UI_autoSummonEnable "Touchscreen user interface computer: auto summon enable";
CM_ SG_ 1016 UI_exceptionListEnable "Touchscreen user interface computer: exception list enable";
CM_ SG_ 1016 UI_roadCheckDisable "Touchscreen user interface computer: road check disable";
CM_ SG_ 1016 UI_driveOnMapsEnable "Drive on Autopilot enabled";
CM_ SG_ 1016 UI_handsOnRequirementDisable "Touchscreen user interface computer: hands on requirement disable";
CM_ SG_ 1016 UI_ulcOffHighway "Touchscreen user interface computer: ulc off highway";
CM_ SG_ 1016 UI_fuseLanesDisable "Touchscreen user interface computer: fuse lanes disable";
CM_ SG_ 1016 UI_fuseHPPDisable "Touchscreen user interface computer: fuse HPP disable";
CM_ SG_ 1016 UI_fuseVehiclesDisable "Touchscreen user interface computer: fuse vehicles disable";
CM_ SG_ 1016 UI_enableClipParkedTelemetry "Touchscreen user interface computer: enable clip parked telemetry";
CM_ SG_ 1016 UI_visionSpeedType "Touchscreen user interface computer: vision speed type";
CM_ SG_ 1016 UI_curvatureDatabaseOnly "Touchscreen user interface computer: curvature database only";
CM_ SG_ 1016 UI_lssElkEnabled "User setting for emergency lane keep";
CM_ SG_ 1016 UI_summonExitType "Touchscreen user interface computer: summon exit type; raw 3 = signal not available (SNA)";
CM_ SG_ 1016 UI_summonEntryType "Touchscreen user interface computer: summon entry type; raw 3 = signal not available (SNA)";
CM_ SG_ 1016 UI_selfParkRequest "Self park request; raw 15 = signal not available (SNA)";
CM_ SG_ 1016 UI_summonReverseDist "Touchscreen user interface computer: summon reverse dist; raw 63 = signal not available (SNA)";
CM_ SG_ 1016 UI_undertakeAssistEnable "Touchscreen user interface computer: undertake assist enable";
CM_ SG_ 1016 UI_adaptiveSetSpeedEnable "Touchscreen user interface computer: adaptive set speed enable";
CM_ SG_ 1016 UI_drivingSide "Touchscreen user interface computer: driving side";
CM_ SG_ 1016 UI_enableClipTelemetry "Touchscreen user interface computer: enable clip telemetry";
CM_ SG_ 1016 UI_enableTripTelemetry "Touchscreen user interface computer: enable trip telemetry";
CM_ SG_ 1016 UI_enableRoadSegmentTelemetry "Touchscreen user interface computer: enable road segment telemetry";
CM_ SG_ 1016 UI_accFollowDistanceSetting "Touchscreen user interface computer: acc follow distance setting; raw 7 = signal not available (SNA)";
CM_ SG_ 1016 UI_hasDriveOnNav "Touchscreen user interface computer: has drive on nav";
CM_ SG_ 1016 UI_followNavRouteEnable "Following route with Drive on Autopilot";
CM_ SG_ 1016 UI_ulcSpeedConfig "Drive on autopilot speed base lane changes mode.";
CM_ SG_ 1016 UI_ulcBlindSpotConfig "Touchscreen user interface computer: ulc blind spot config";
CM_ SG_ 1016 UI_suppressExitPassingLane "Navigate on Autopilot will not suggest lane changes out of the passing lane";
CM_ SG_ 1016 UI_enableClipStartStopTelemetry "Touchscreen user interface computer: enable clip start stop telemetry";
CM_ SG_ 1016 UI_alcOffHighwayEnable "Touchscreen user interface computer: alc off highway enable";
CM_ SG_ 1016 UI_validationLoop "Touchscreen user interface computer: validation loop";
CM_ SG_ 1016 UI_smartSummonType "Type of smart summon session (Find Me, Pin Drop, Smart Autopark)";
CM_ SG_ 1016 UI_enableVisionOnlyStops "Touchscreen user interface computer: enable vision only stops";
CM_ SG_ 1016 UI_source3D "Touchscreen user interface computer: source3 d";
CM_ SG_ 1016 UI_isaSpeedingChimeMuted "Reports the user input of Intelligent Speed Assist (ISA) speed chime alert option.";
CM_ BO_ 568 "Touchscreen user interface computer message: driver assist map data";
CM_ SG_ 568 UI_mapSpeedLimitDependency "Touchscreen user interface computer: map speed limit dependency; raw 7 = signal not available (SNA)";
CM_ SG_ 568 UI_roadClass "Autopilot map road class; raw 0 = signal not available (SNA)";
CM_ SG_ 568 UI_inSuperchargerGeofence "Touchscreen user interface computer: in supercharger geofence";
CM_ SG_ 568 UI_mapSpeedUnits "Touchscreen user interface computer: map speed units";
CM_ SG_ 568 UI_mapSpeedLimit "Touchscreen user interface computer: map speed limit; raw 31 = signal not available (SNA)";
CM_ SG_ 568 UI_mapSpeedLimitType "Touchscreen user interface computer: map speed limit type; raw 7 = signal not available (SNA)";
CM_ SG_ 568 UI_countryCode "Touchscreen user interface computer: country code; raw 1023 = signal not available (SNA)";
CM_ SG_ 568 UI_streetCount "Touchscreen user interface computer: street count";
CM_ SG_ 568 UI_gpsRoadMatch "Touchscreen user interface computer: gps road match";
CM_ SG_ 568 UI_navRouteActive "Navigation route is active";
CM_ SG_ 568 UI_parallelAutoparkEnabled "Autopilot map parallel park enabled.";
CM_ SG_ 568 UI_perpendicularAutoparkEnabled "Autopilot map perpendicular park enabled.";
CM_ SG_ 568 UI_nextBranchDist "Touchscreen user interface computer: next branch dist; raw 31 = signal not available (SNA)";
CM_ SG_ 568 UI_controlledAccess "DAS map controlled access segment.";
CM_ SG_ 568 UI_nextBranchLeftOffRamp "Touchscreen user interface computer: next branch left off ramp";
CM_ SG_ 568 UI_nextBranchRightOffRamp "Touchscreen user interface computer: next branch right off ramp";
CM_ SG_ 568 UI_rejectLeftLane "Touchscreen user interface computer: reject left lane";
CM_ SG_ 568 UI_rejectRightLane "Touchscreen user interface computer: reject right lane";
CM_ SG_ 568 UI_rejectHPP "Touchscreen user interface computer: reject HPP";
CM_ SG_ 568 UI_rejectNav "Touchscreen user interface computer: reject nav";
CM_ SG_ 568 UI_rejectLeftFreeSpace "Touchscreen user interface computer: reject left free space";
CM_ SG_ 568 UI_rejectRightFreeSpace "Touchscreen user interface computer: reject right free space";
CM_ SG_ 568 UI_rejectAutosteer "Touchscreen user interface computer: reject autosteer";
CM_ SG_ 568 UI_rejectHandsOn "Touchscreen user interface computer: reject hands on";
CM_ SG_ 568 UI_acceptBottsDots "Touchscreen user interface computer: accept botts dots";
CM_ SG_ 568 UI_autosteerRestricted "Autopilot map is autostreer restricted.";
CM_ SG_ 568 UI_pmmEnabled "Touchscreen user interface computer: pmm enabled";
CM_ SG_ 568 UI_scaEnabled "Touchscreen user interface computer: sca enabled";
CM_ SG_ 568 UI_mapDataCounter "Touchscreen user interface computer: map data counter";
CM_ SG_ 568 UI_mapDataChecksum "Touchscreen user interface computer: map data checksum";
CM_ BO_ 536 "Touchscreen user interface computer message: driver assist road sign";
CM_ SG_ 536 UI_roadSign "Touchscreen user interface computer: road sign; raw 255 = signal not available (SNA)";
CM_ SG_ 536 UI_splineLocConfidence "Touchscreen user interface computer: spline loc confidence; raw 0 = signal not available (SNA)";
CM_ SG_ 536 UI_splineID "Touchscreen user interface computer: spline ID";
CM_ SG_ 536 UI_roadSignCounter "Touchscreen user interface computer: road sign counter";
CM_ SG_ 536 UI_roadSignChecksum "Touchscreen user interface computer: road sign checksum";
CM_ SG_ 536 UI_dummyData "Touchscreen user interface computer: dummy data";
CM_ SG_ 536 UI_stopSignStopLineDist "Touchscreen user interface computer: stop sign stop line dist; raw 1023 = signal not available (SNA)";
CM_ SG_ 536 UI_stopSignStopLineConf "Touchscreen user interface computer: stop sign stop line conf; raw 0 = signal not available (SNA)";
CM_ SG_ 536 UI_trafficLightStopLineDist "Touchscreen user interface computer: traffic light stop line dist; raw 1023 = signal not available (SNA)";
CM_ SG_ 536 UI_trafficLightStopLineConf "Touchscreen user interface computer: traffic light stop line conf; raw 0 = signal not available (SNA)";
CM_ SG_ 536 UI_baseMapSpeedLimitMPS "Touchscreen user interface computer: base map speed limit MPS; raw 255 = signal not available (SNA)";
CM_ SG_ 536 UI_bottomQrtlFleetSpeedMPS "Touchscreen user interface computer: bottom qrtl fleet speed MPS; raw 255 = signal not available (SNA)";
CM_ SG_ 536 UI_topQrtlFleetSpeedMPS "Touchscreen user interface computer: top qrtl fleet speed MPS; raw 255 = signal not available (SNA)";
CM_ SG_ 536 UI_meanFleetSplineSpeedMPS "Touchscreen user interface computer: mean fleet spline speed MPS; raw 255 = signal not available (SNA)";
CM_ SG_ 536 UI_medianFleetSpeedMPS "Touchscreen user interface computer: median fleet speed MPS; raw 255 = signal not available (SNA)";
CM_ SG_ 536 UI_meanFleetSplineAccelMPS2 "Touchscreen user interface computer: mean fleet spline accel MPS2; raw 255 = signal not available (SNA)";
CM_ SG_ 536 UI_rampType "Touchscreen user interface computer: ramp type; raw 0 = signal not available (SNA)";
CM_ SG_ 536 UI_valhallaRamp "Touchscreen user interface computer: valhalla ramp; raw 0 = signal not available (SNA)";
CM_ SG_ 536 UI_overrideACMFleetSpeed "Touchscreen user interface computer: override ACM fleet speed";
CM_ SG_ 536 UI_currSplineIdFull "Touchscreen user interface computer: curr spline id full; raw 0 = signal not available (SNA)";
CM_ BO_ 645 "Touchscreen user interface computer message: driver profile recall";
CM_ SG_ 645 UI_driverProfileRecallIndex "Touchscreen user interface computer: driver profile recall index; raw 0 = signal not available (SNA)";
CM_ SG_ 645 UI_driverProfileRecallStop "notifies controller to stop profile recall action";
CM_ SG_ 645 UI_frontSeatRecallActive "signals when driver seat presets are being recalled";
CM_ SG_ 645 UI_frontSeatTrackPos "Touchscreen user interface computer: front seat track pos";
CM_ SG_ 645 UI_frontSeatBackPos "Touchscreen user interface computer: front seat back pos";
CM_ SG_ 645 UI_frontSeatLiftPos "Touchscreen user interface computer: front seat lift pos";
CM_ SG_ 645 UI_frontSeatTiltPos "Touchscreen user interface computer: front seat tilt pos";
CM_ SG_ 645 UI_columnAndLumbarRecallActive "Touchscreen user interface computer: column and lumbar recall active";
CM_ SG_ 645 UI_steeringColumnUpDownPos "Touchscreen user interface computer: steering column up down pos";
CM_ SG_ 645 UI_lumbarAPressureHpa "Touchscreen user interface computer: lumbar a pressure hpa";
CM_ SG_ 645 UI_lumbarBPressureHpa "Touchscreen user interface computer: lumbar b pressure hpa";
CM_ SG_ 645 UI_steeringColumnInOutPos "Touchscreen user interface computer: steering column in out pos";
CM_ SG_ 645 UI_leftMirrorTiltXPosition "signal from ui to command mirror X tilt position";
CM_ SG_ 645 UI_leftMirrorTiltYPosition "signal from ui to command mirror Y tilt position";
CM_ SG_ 645 UI_rightMirrorTiltXPosition "Touchscreen user interface computer: right mirror tilt x position";
CM_ SG_ 645 UI_rightMirrorTiltYPosition "Touchscreen user interface computer: right mirror tilt y position";
CM_ SG_ 645 UI_mirrorRecallActive "Touchscreen user interface computer: mirror recall active";
CM_ SG_ 645 UI_customMirrorDipPositionsSet "Reports whether custom mirror dip positions are set.";
CM_ SG_ 645 UI_leftMirrorDipXPosition "signal from ui to command left mirror X dip position";
CM_ SG_ 645 UI_leftMirrorDipYPosition "signal from ui to command mirror Y dip position";
CM_ SG_ 645 UI_rightMirrorDipXPosition "Touchscreen user interface computer: right mirror dip x position";
CM_ SG_ 645 UI_rightMirrorDipYPosition "Touchscreen user interface computer: right mirror dip y position";
CM_ SG_ 645 UI_modifyMirrorDipRequest "Reports that a user is trying to modify the mirrors in the dipped position.";
CM_ BO_ 647 "Touchscreen user interface computer message: driver profile recall2";
CM_ SG_ 647 UI_driverProfileLinkedKeySHA1 "Touchscreen user interface computer: driver profile linked key SHA1; raw 4294967295 = signal not available (SNA)";
CM_ SG_ 647 UI_driverProfileIndex "Tracks manual driver profile selection. Shows the linked phonekey / key card / key fob or profile index if not linked";
CM_ SG_ 647 UI_driverProfileSelectionType "Tracks manual driver profile selection. Shows the linked phonekey / key card / key fob or profile index if not linked";
CM_ SG_ 647 UI_driverProfilePositionAdjusted "Tracks adjustments to driver profile. Sets when a profile position has been adjusted from what was saved";
CM_ SG_ 647 UI_activeKeyRequested "Tracks manual driver profile selection. Shows the linked phonekey / key card / key fob or profile index if not linked";
CM_ BO_ 1971 "Touchscreen user interface computer message: dynamic triggers campaign fired";
CM_ SG_ 1971 UI_campaignFired "Touchscreen user interface computer: campaign fired";
CM_ BO_ 984 "Touchscreen user interface computer message: elevation status";
CM_ SG_ 984 UI_elevation "Touchscreen user interface computer: elevation; raw 8191 = signal not available (SNA)";
CM_ SG_ 984 UI_navElevation "Touchscreen user interface computer: nav elevation; raw 8191 = signal not available (SNA)";
CM_ BO_ 1279 "Touchscreen user interface computer message: energy consumption info";
CM_ SG_ 1279 UI_energyConsumptionInfoIndex "Touchscreen user interface computer: energy consumption info index";
CM_ SG_ 1279 UI_energyLossTotal_epa "Energy amount for a given bucket for an energy consumption baseline (raw/real energy consumed)";
CM_ SG_ 1279 UI_energyLossDriving_epa "Energy amount for a given bucket for an energy consumption baseline (raw/real energy consumed)";
CM_ SG_ 1279 UI_energyLossClimate_epa "Energy amount for a given bucket for an energy consumption baseline (raw/real energy consumed)";
CM_ SG_ 1279 UI_energyLossBattCond_epa "Energy amount for a given bucket for an energy consumption baseline (raw/real energy consumed)";
CM_ SG_ 1279 UI_energyLossElevation_epa "Energy amount for a given bucket for an energy consumption baseline (raw/real energy consumed)";
CM_ SG_ 1279 UI_energyLossAcc_epa "Energy amount for a given bucket for an energy consumption baseline (raw/real energy consumed)";
CM_ SG_ 1279 UI_energyLossTotalSinceCharge_ep "Energy amount for a given bucket for an energy consumption baseline (raw/real energy consumed)";
CM_ SG_ 1279 UI_energyLossDrivingSinceCharge_ "Energy amount for a given bucket for an energy consumption baseline (raw/real energy consumed)";
CM_ SG_ 1279 UI_energyLossClimateSinceCharge_ "Energy amount for a given bucket for an energy consumption baseline (raw/real energy consumed)";
CM_ SG_ 1279 UI_energyLossBattCondSinceCharge "Energy amount for a given bucket for an energy consumption baseline (raw/real energy consumed)";
CM_ SG_ 1279 UI_energyLossElevationSinceCharg "Energy amount for a given bucket for an energy consumption baseline (raw/real energy consumed)";
CM_ SG_ 1279 UI_energyLossAccSinceCharge_epa "Energy amount for a given bucket for an energy consumption baseline (raw/real energy consumed)";
CM_ SG_ 1279 UI_energyLossTotalSinceTripStart "Energy amount for a given bucket for an energy consumption baseline (raw/real energy consumed)";
CM_ SG_ 1279 UI_energyLossDrivingSinceTripSta "Energy amount for a given bucket for an energy consumption baseline (raw/real energy consumed)";
CM_ SG_ 1279 UI_energyLossClimateSinceTripSta "Energy amount for a given bucket for an energy consumption baseline (raw/real energy consumed)";
CM_ SG_ 1279 UI_energyLossBattCondSinceTripSt "Energy amount for a given bucket for an energy consumption baseline (raw/real energy consumed)";
CM_ SG_ 1279 UI_energyLossElevationSinceTripS "Energy amount for a given bucket for an energy consumption baseline (raw/real energy consumed)";
CM_ SG_ 1279 UI_energyLossAccSinceTripStart "Energy amount for a given bucket for an energy consumption baseline (raw/real energy consumed)";
CM_ SG_ 1279 UI_energyDeltaTotal_epa "Energy amount for a given bucket for an energy consumption baseline (raw/real energy consumed)";
CM_ SG_ 1279 UI_energyDeltaDriving_epa "Energy amount for a given bucket for an energy consumption baseline (raw/real energy consumed)";
CM_ SG_ 1279 UI_energyDeltaClimate_epa "Energy amount for a given bucket for an energy consumption baseline (raw/real energy consumed)";
CM_ SG_ 1279 UI_energyDeltaBattCond_epa "Energy amount for a given bucket for an energy consumption baseline (raw/real energy consumed)";
CM_ SG_ 1279 UI_energyDeltaElevation_epa "Energy amount for a given bucket for an energy consumption baseline (raw/real energy consumed)";
CM_ SG_ 1279 UI_energyDeltaAcc_epa "Energy amount for a given bucket for an energy consumption baseline (raw/real energy consumed)";
CM_ SG_ 1279 UI_uiDeltaOffsetTotal_epa "Energy amount for a given bucket for an energy consumption baseline (raw/real energy consumed)";
CM_ SG_ 1279 UI_uiDeltaOffsetDriving_epa "Energy amount for a given bucket for an energy consumption baseline (raw/real energy consumed)";
CM_ SG_ 1279 UI_uiDeltaOffsetClimate_epa "Energy amount for a given bucket for an energy consumption baseline (raw/real energy consumed)";
CM_ SG_ 1279 UI_uiDeltaOffsetBattCond_epa "Energy amount for a given bucket for an energy consumption baseline (raw/real energy consumed)";
CM_ SG_ 1279 UI_uiDeltaOffsetElevation_epa "Energy amount for a given bucket for an energy consumption baseline (raw/real energy consumed)";
CM_ SG_ 1279 UI_uiDeltaOffsetAcc_epa "Energy amount for a given bucket for an energy consumption baseline (raw/real energy consumed)";
CM_ SG_ 1279 UI_rawToUiEnergyRatio_epa "Ratio used for conversion between UI and raw energy domains";
CM_ SG_ 1279 UI_driveDistance_epa "Distance driven for an energy consumption baseline";
CM_ SG_ 1279 UI_energyDeltaTotalSinceCharge_e "Energy amount for a given bucket for an energy consumption baseline (raw/real energy consumed)";
CM_ SG_ 1279 UI_energyDeltaDrivingSinceCharge "Energy amount for a given bucket for an energy consumption baseline (raw/real energy consumed)";
CM_ SG_ 1279 UI_energyDeltaClimateSinceCharge "Energy amount for a given bucket for an energy consumption baseline (raw/real energy consumed)";
CM_ SG_ 1279 UI_energyDeltaBattCondSinceCharg "Energy amount for a given bucket for an energy consumption baseline (raw/real energy consumed)";
CM_ SG_ 1279 UI_energyDeltaElevationSinceChar "Energy amount for a given bucket for an energy consumption baseline (raw/real energy consumed)";
CM_ SG_ 1279 UI_energyDeltaAccSinceCharge_epa "Energy amount for a given bucket for an energy consumption baseline (raw/real energy consumed)";
CM_ SG_ 1279 UI_uiDeltaOffsetTotalSinceCharge "Energy amount for a given bucket for an energy consumption baseline (raw/real energy consumed)";
CM_ SG_ 1279 UI_uiDeltaOffsetDrivingSinceChar "Energy amount for a given bucket for an energy consumption baseline (raw/real energy consumed)";
CM_ SG_ 1279 UI_uiDeltaOffsetClimateSinceChar "Energy amount for a given bucket for an energy consumption baseline (raw/real energy consumed)";
CM_ SG_ 1279 UI_uiDeltaOffsetBattCondSinceCha "Energy amount for a given bucket for an energy consumption baseline (raw/real energy consumed)";
CM_ SG_ 1279 UI_uiDeltaOffsetElevationSinceCh "Energy amount for a given bucket for an energy consumption baseline (raw/real energy consumed)";
CM_ SG_ 1279 UI_uiDeltaOffsetAccSinceCharge_e "Energy amount for a given bucket for an energy consumption baseline (raw/real energy consumed)";
CM_ SG_ 1279 UI_rawToUiEnergyRatioSinceCharge "Ratio used for conversion between UI and raw energy domains";
CM_ SG_ 1279 UI_driveDistanceSinceCharge_epa "Distance driven for an energy consumption baseline";
CM_ SG_ 1279 UI_energyDeltaTotalSinceTripStar "Energy amount for a given bucket for an energy consumption baseline (raw/real energy consumed)";
CM_ SG_ 1279 UI_energyDeltaDrivingSinceTripSt "Energy amount for a given bucket for an energy consumption baseline (raw/real energy consumed)";
CM_ SG_ 1279 UI_energyDeltaClimateSinceTripSt "Energy amount for a given bucket for an energy consumption baseline (raw/real energy consumed)";
CM_ SG_ 1279 UI_energyDeltaBattCondSinceTripS "Energy amount for a given bucket for an energy consumption baseline (raw/real energy consumed)";
CM_ SG_ 1279 UI_energyDeltaElevationSinceTrip "Energy amount for a given bucket for an energy consumption baseline (raw/real energy consumed)";
CM_ SG_ 1279 UI_energyDeltaAccSinceTripStart "Energy amount for a given bucket for an energy consumption baseline (raw/real energy consumed)";
CM_ SG_ 1279 UI_uiDeltaOffsetTotalSinceTripSt "Energy amount for a given bucket for an energy consumption baseline (raw/real energy consumed)";
CM_ SG_ 1279 UI_uiDeltaOffsetDrivingSinceTrip "Energy amount for a given bucket for an energy consumption baseline (raw/real energy consumed)";
CM_ SG_ 1279 UI_uiDeltaOffsetClimateSinceTrip "Energy amount for a given bucket for an energy consumption baseline (raw/real energy consumed)";
CM_ SG_ 1279 UI_uiDeltaOffsetBattCondSinceTri "Energy amount for a given bucket for an energy consumption baseline (raw/real energy consumed)";
CM_ SG_ 1279 UI_uiDeltaOffsetElevationSinceTr "Energy amount for a given bucket for an energy consumption baseline (raw/real energy consumed)";
CM_ SG_ 1279 UI_uiDeltaOffsetAccSinceTripStar "Energy amount for a given bucket for an energy consumption baseline (raw/real energy consumed)";
CM_ SG_ 1279 UI_rawToUiEnergyRatioSinceTripSt "Ratio used for conversion between UI and raw energy domains";
CM_ SG_ 1279 UI_driveDistanceSinceTripStart "Distance driven for an energy consumption baseline";
CM_ SG_ 1279 UI_voyagerEnabled "Touchscreen user interface computer: voyager enabled";
CM_ SG_ 1279 UI_trailerMass "Trailer mass from user input";
CM_ BO_ 1139 "Touchscreen user interface computer message: eth nm";
CM_ SG_ 1139 UI_nmGoingToSleep "Touchscreen user interface computer: nm going to sleep";
CM_ SG_ 1139 UI_nmKeepAwakeReason "reason UI is being kept awake; raw 0 = signal not available (SNA)";
CM_ SG_ 1139 UI_wakeupTime "Unix epoch time at which vehicle should wake for scheduled charge or update.";
CM_ BO_ 1267 "Touchscreen user interface computer message: front seat requests";
CM_ SG_ 1267 UI_frontRightSeatTrackForward "Touchscreen user interface computer: front right seat track forward";
CM_ SG_ 1267 UI_frontRightSeatTrackBack "Touchscreen user interface computer: front right seat track back";
CM_ SG_ 1267 UI_frontLeftSeatTrackForward "Touchscreen user interface computer: front left seat track forward";
CM_ SG_ 1267 UI_frontLeftSeatTrackBack "Touchscreen user interface computer: front left seat track back";
CM_ SG_ 1267 UI_frontRightSeatBackrestBack "Touchscreen user interface computer: front right seat backrest back";
CM_ SG_ 1267 UI_frontRightSeatBackrestForward "Touchscreen user interface computer: front right seat backrest forward";
CM_ SG_ 1267 UI_frontLeftSeatBackrestBack "Touchscreen user interface computer: front left seat backrest back";
CM_ SG_ 1267 UI_frontLeftSeatBackrestForward "Touchscreen user interface computer: front left seat backrest forward";
CM_ BO_ 804 "Touchscreen user interface computer message: gps time";
CM_ SG_ 804 UI_gpsTime "Touchscreen user interface computer: gps time";
CM_ BO_ 985 "Touchscreen user interface computer message: gps vehicle speed";
CM_ SG_ 985 UI_gpsHDOP "Touchscreen user interface computer: gps HDOP";
CM_ SG_ 985 UI_gpsVehicleHeading "Touchscreen user interface computer: gps vehicle heading";
CM_ SG_ 985 UI_gpsVehicleSpeed "Touchscreen user interface computer: gps vehicle speed";
CM_ SG_ 985 UI_userSpeedOffset "Touchscreen user interface computer: user speed offset";
CM_ SG_ 985 UI_mapSpeedLimitUnits "Autopilot map speed limit units.";
CM_ SG_ 985 UI_userSpeedOffsetUnits "Touchscreen user interface computer: user speed offset units";
CM_ SG_ 985 UI_mppSpeedLimit "Autopilot map speed limit";
CM_ SG_ 985 UI_gpsNmeaMIA "GPS NMEA data MIA";
CM_ SG_ 985 UI_gpsAntennaDisconnected "GPS antenna state";
CM_ SG_ 985 UI_conditionalLimitActive "Conditional speed limit condition is currently active";
CM_ SG_ 985 UI_conditionalSpeedLimit "Conditional speed limit value; raw 31 = signal not available (SNA)";
CM_ BO_ 755 "Touchscreen user interface computer message: hvac request";
CM_ SG_ 755 UI_hvacReqTempSetpointLeft "HVAC left set temperature.";
CM_ SG_ 755 UI_hvacReqAutoBlowerLevel "Reports the auto Heating, Ventilation, and Air Conditioning (HVAC) speed aggressiveness setting.";
CM_ SG_ 755 UI_hvacReqTempSetpointRight "HVAC right set temperature.";
CM_ SG_ 755 UI_hvacReqAirDistributionMode "Request for air distribution mode.";
CM_ SG_ 755 UI_hvacReqBlowerSegment "HVAC manual blower request (GUI_hvacManualBlowerRequest)";
CM_ SG_ 755 UI_hvacReqRecirc "HVAC recirculation mode";
CM_ SG_ 755 UI_hvacReqACDisable "Request to disable AC.";
CM_ SG_ 755 UI_hvacDefogState "HVAC defog state.";
CM_ SG_ 755 UI_hvacReqUserPowerState "Reports HVAC power state.";
CM_ SG_ 755 UI_hvacReqSecondRowState "HVAC rear fan request speed.";
CM_ SG_ 755 UI_hvacUseModeledDuctTemp "Touchscreen user interface computer: hvac use modeled duct temp";
CM_ SG_ 755 UI_hvacReqKeepClimateOn "Request accessory power";
CM_ SG_ 755 UI_hvacReqBioWeaponDefMode "Request for BioWeapon Defense Mode";
CM_ SG_ 755 UI_hvacLatchPassengerPresent "Touchscreen user interface computer: hvac latch passenger present";
CM_ SG_ 755 UI_enableHvacControlsFeatures1 "Touchscreen user interface computer: enable hvac controls features1";
CM_ SG_ 755 UI_enableHvacNotifications "Touchscreen user interface computer: enable hvac notifications";
CM_ SG_ 755 UI_hvacPhoneCallAirFlowAdjustEna "Touchscreen user interface computer: hvac phone call air flow adjust enabled";
CM_ SG_ 755 UI_enableHvacVOCPurgeRoutine "Touchscreen user interface computer: enable hvac VOC purge routine";
CM_ SG_ 755 UI_enableCustomerTHSAlerts "Touchscreen user interface computer: enable customer THS alerts";
CM_ SG_ 755 UI_evapDryingSelectiveEnable "Touchscreen user interface computer: evap drying selective enable";
CM_ SG_ 755 UI_enableHvacWeatherDataBasedHum "Touchscreen user interface computer: enable hvac weather data based humidity controls";
CM_ SG_ 755 UI_hvacReqTempSetpointCOP "HVAC cabin overheat protection set temperature.";
CM_ SG_ 755 UI_hvacClimateNudgeStatus "Touchscreen user interface computer: hvac climate nudge status";
CM_ SG_ 755 UI_enableHvacControlsFeatures2 "Touchscreen user interface computer: enable hvac controls features2";
CM_ SG_ 755 UI_enableHvacAPFoggingMonitor "Touchscreen user interface computer: enable hvac AP fogging monitor";
CM_ SG_ 755 UI_enableHvacLimpMode "Touchscreen user interface computer: enable hvac limp mode";
CM_ BO_ 989 "Touchscreen user interface computer message: location offset";
CM_ SG_ 989 UI_latitudeOffset "Touchscreen user interface computer: latitude offset";
CM_ SG_ 989 UI_longitudeOffset "Touchscreen user interface computer: longitude offset";
CM_ BO_ 79 "Touchscreen user interface computer message: location status";
CM_ SG_ 79 UI_latitude "Touchscreen user interface computer: latitude";
CM_ SG_ 79 UI_longitude "Touchscreen user interface computer: longitude";
CM_ SG_ 79 UI_gpsAccuracy "Touchscreen user interface computer: gps accuracy; raw 127 = signal not available (SNA)";
CM_ BO_ 1011 "Touchscreen user interface computer message: odo";
CM_ SG_ 1011 UI_odometer "Odometer; raw 16777215 = signal not available (SNA)";
CM_ BO_ 443 "Touchscreen user interface computer message: peripheral power requests";
CM_ SG_ 443 UI_usbFrontHubPowerStateRequest "Reports the Universal Serial Bus (USB) Hub power request.; raw 0 = signal not available (SNA)";
CM_ BO_ 987 "Touchscreen user interface computer message: phone location status";
CM_ SG_ 987 UI_phoneLatitude "Touchscreen user interface computer: phone latitude";
CM_ SG_ 987 UI_phoneLongitude "Touchscreen user interface computer: phone longitude";
CM_ SG_ 987 UI_phoneGpsAccuracy "Touchscreen user interface computer: phone gps accuracy; raw 127 = signal not available (SNA)";
CM_ BO_ 955 "Touchscreen user interface computer message: power";
CM_ SG_ 955 UI_powerExpected "Touchscreen user interface computer: power expected";
CM_ SG_ 955 UI_powerIdeal "Touchscreen user interface computer: power ideal";
CM_ BO_ 827 "Touchscreen user interface computer message: power estimates";
CM_ SG_ 827 UI_idlePowerConsumption "Power consumption when idle";
CM_ SG_ 827 UI_chargeTimeUntilTerminationPct "Charge time minutes until reached uSoe target; raw 2047 = signal not available (SNA)";
CM_ SG_ 827 UI_isTripChargingActive "Touchscreen user interface computer: is trip charging active";
CM_ SG_ 827 UI_chargeTimeUntilReadyToDepart "Charge time minutes until enough energy to depart for rest of trip; raw 2047 = signal not available (SNA)";
CM_ BO_ 629 "Touchscreen user interface computer message: power rationality config";
CM_ SG_ 629 UI_powerRationalityConfigIndex "Touchscreen user interface computer: power rationality config index";
CM_ SG_ 629 UI_vcleftCfgRationalityThreshold "Touchscreen user interface computer: vcleft cfg rationality threshold0; raw 0 = signal not available (SNA)";
CM_ SG_ 629 UI_vcleftCfgRationalityTime0 "Touchscreen user interface computer: vcleft cfg rationality time0; raw 0 = signal not available (SNA)";
CM_ SG_ 629 UI_vcleftCfgRationalityThre_0001 "Touchscreen user interface computer: vcleft cfg rationality threshold1; raw 0 = signal not available (SNA)";
CM_ SG_ 629 UI_vcleftCfgRationalityTime1 "Touchscreen user interface computer: vcleft cfg rationality time1; raw 0 = signal not available (SNA)";
CM_ SG_ 629 UI_vcleftCfgRationalityStaticA "Touchscreen user interface computer: vcleft cfg rationality static a; raw 65535 = signal not available (SNA)";
CM_ SG_ 629 UI_vcleftCfgRationalityStaticB "Touchscreen user interface computer: vcleft cfg rationality static b; raw 32768 = signal not available (SNA)";
CM_ SG_ 629 UI_vcleftCfgRationalityStaticC "Touchscreen user interface computer: vcleft cfg rationality static c; raw 32768 = signal not available (SNA)";
CM_ SG_ 629 UI_vcleftCfgRationalityDynamicA "Touchscreen user interface computer: vcleft cfg rationality dynamic a; raw 65535 = signal not available (SNA)";
CM_ SG_ 629 UI_vcleftCfgRationalityDynamicB "Touchscreen user interface computer: vcleft cfg rationality dynamic b; raw 32768 = signal not available (SNA)";
CM_ SG_ 629 UI_vcleftCfgRationalityDynamicC "Touchscreen user interface computer: vcleft cfg rationality dynamic c; raw 32768 = signal not available (SNA)";
CM_ SG_ 629 UI_vcrightCfgRationalityThreshol "Touchscreen user interface computer: vcright cfg rationality threshold0; raw 0 = signal not available (SNA)";
CM_ SG_ 629 UI_vcrightCfgRationalityTime0 "Touchscreen user interface computer: vcright cfg rationality time0; raw 0 = signal not available (SNA)";
CM_ SG_ 629 UI_vcrightCfgRationalityThr_0001 "Touchscreen user interface computer: vcright cfg rationality threshold1; raw 0 = signal not available (SNA)";
CM_ SG_ 629 UI_vcrightCfgRationalityTime1 "Touchscreen user interface computer: vcright cfg rationality time1; raw 0 = signal not available (SNA)";
CM_ SG_ 629 UI_vcrightCfgRationalityStaticA "Touchscreen user interface computer: vcright cfg rationality static a; raw 65535 = signal not available (SNA)";
CM_ SG_ 629 UI_vcrightCfgRationalityStaticB "Touchscreen user interface computer: vcright cfg rationality static b; raw 32768 = signal not available (SNA)";
CM_ SG_ 629 UI_vcrightCfgRationalityStaticC "Touchscreen user interface computer: vcright cfg rationality static c; raw 32768 = signal not available (SNA)";
CM_ SG_ 629 UI_vcrightCfgRationalityDynamicA "Touchscreen user interface computer: vcright cfg rationality dynamic a; raw 65535 = signal not available (SNA)";
CM_ SG_ 629 UI_vcrightCfgRationalityDynamicB "Touchscreen user interface computer: vcright cfg rationality dynamic b; raw 32768 = signal not available (SNA)";
CM_ SG_ 629 UI_vcrightCfgRationalityDynamicC "Touchscreen user interface computer: vcright cfg rationality dynamic c; raw 32768 = signal not available (SNA)";
CM_ SG_ 629 UI_vcleftCfgCutoffThreshold0 "Touchscreen user interface computer: vcleft cfg cutoff threshold0; raw 0 = signal not available (SNA)";
CM_ SG_ 629 UI_vcleftCfgCutoffTime0 "Touchscreen user interface computer: vcleft cfg cutoff time0; raw 0 = signal not available (SNA)";
CM_ SG_ 629 UI_vcleftCfgCutoffThreshold1 "Touchscreen user interface computer: vcleft cfg cutoff threshold1; raw 0 = signal not available (SNA)";
CM_ SG_ 629 UI_vcleftCfgCutoffTime1 "Touchscreen user interface computer: vcleft cfg cutoff time1; raw 0 = signal not available (SNA)";
CM_ SG_ 629 UI_vcleftCfgCutoffStaticA "Touchscreen user interface computer: vcleft cfg cutoff static a; raw 65535 = signal not available (SNA)";
CM_ SG_ 629 UI_vcleftCfgCutoffStaticB "Touchscreen user interface computer: vcleft cfg cutoff static b; raw 32768 = signal not available (SNA)";
CM_ SG_ 629 UI_vcleftCfgCutoffStaticC "Touchscreen user interface computer: vcleft cfg cutoff static c; raw 32768 = signal not available (SNA)";
CM_ SG_ 629 UI_vcleftCfgCutoffDynamicA "Touchscreen user interface computer: vcleft cfg cutoff dynamic a; raw 65535 = signal not available (SNA)";
CM_ SG_ 629 UI_vcleftCfgCutoffDynamicB "Touchscreen user interface computer: vcleft cfg cutoff dynamic b; raw 32768 = signal not available (SNA)";
CM_ SG_ 629 UI_vcleftCfgCutoffDynamicC "Touchscreen user interface computer: vcleft cfg cutoff dynamic c; raw 32768 = signal not available (SNA)";
CM_ SG_ 629 UI_vcrightCfgCutoffThreshold0 "Touchscreen user interface computer: vcright cfg cutoff threshold0; raw 0 = signal not available (SNA)";
CM_ SG_ 629 UI_vcrightCfgCutoffTime0 "Touchscreen user interface computer: vcright cfg cutoff time0; raw 0 = signal not available (SNA)";
CM_ SG_ 629 UI_vcrightCfgCutoffThreshold1 "Touchscreen user interface computer: vcright cfg cutoff threshold1; raw 0 = signal not available (SNA)";
CM_ SG_ 629 UI_vcrightCfgCutoffTime1 "Touchscreen user interface computer: vcright cfg cutoff time1; raw 0 = signal not available (SNA)";
CM_ SG_ 629 UI_vcrightCfgCutoffStaticA "Touchscreen user interface computer: vcright cfg cutoff static a; raw 65535 = signal not available (SNA)";
CM_ SG_ 629 UI_vcrightCfgCutoffStaticB "Touchscreen user interface computer: vcright cfg cutoff static b; raw 32768 = signal not available (SNA)";
CM_ SG_ 629 UI_vcrightCfgCutoffStaticC "Touchscreen user interface computer: vcright cfg cutoff static c; raw 32768 = signal not available (SNA)";
CM_ SG_ 629 UI_vcrightCfgCutoffDynamicA "Touchscreen user interface computer: vcright cfg cutoff dynamic a; raw 65535 = signal not available (SNA)";
CM_ SG_ 629 UI_vcrightCfgCutoffDynamicB "Touchscreen user interface computer: vcright cfg cutoff dynamic b; raw 32768 = signal not available (SNA)";
CM_ SG_ 629 UI_vcrightCfgCutoffDynamicC "Touchscreen user interface computer: vcright cfg cutoff dynamic c; raw 32768 = signal not available (SNA)";
CM_ BO_ 820 "Touchscreen user interface computer message: powertrain control";
CM_ SG_ 820 UI_systemPowerLimit "Touchscreen user interface computer: system power limit; raw 31 = signal not available (SNA)";
CM_ SG_ 820 UI_pedalMap "Switch between various platform specific pedal maps";
CM_ SG_ 820 UI_enableRegenBackfill "Indicates if regenerative braking backfill has been enabled by the driver";
CM_ SG_ 820 UI_systemTorqueLimit "Touchscreen user interface computer: system torque limit; raw 63 = signal not available (SNA)";
CM_ SG_ 820 UI_closureConfirmed "Touchscreen user interface computer: closure confirmed";
CM_ SG_ 820 UI_regenTorqueMax "Maximum regen torque from UI - reports different value when in track mode";
CM_ SG_ 820 UI_limitMode "Commands limited drive inverter capabilities based on special vehicle modes";
CM_ SG_ 820 UI_factoryCustomerDrivingModeReq "Touchscreen user interface computer: factory customer driving mode request";
CM_ SG_ 820 UI_motorOnMode "Request from the UI to selectively enable or disable a drive unit (dev-only)";
CM_ SG_ 820 UI_wasteMode "Touchscreen user interface computer: waste mode";
CM_ SG_ 820 UI_wasteModeRegenLimit "Touchscreen user interface computer: waste mode regen limit";
CM_ SG_ 820 UI_stoppingMode "Low-speed behavior when no pedal is pressed (stopping/rolling/creeping)";
CM_ SG_ 820 UI_DIAppSliderDebug "Touchscreen user interface computer: DI app slider debug";
CM_ SG_ 820 UI_speedLimit "Maximum allowed speed enforced at vehicle level.; raw 511 = signal not available (SNA)";
CM_ SG_ 820 UI_enableSmartShift "Stalkless convenience feature that allows unparking with only a firm press of brake pedal";
CM_ SG_ 820 UI_navVehParallelToRdCanContinue "Whether the vehicle is parallel parked on a public road; raw 0 = signal not available (SNA)";
CM_ SG_ 820 UI_powertrainControlCounter "Touchscreen user interface computer: powertrain control counter";
CM_ SG_ 820 UI_powertrainControlChecksum "Touchscreen user interface computer: powertrain control checksum";
CM_ BO_ 698 "Touchscreen user interface computer message: radar map data";
CM_ SG_ 698 UI_radarTargetDx "Touchscreen user interface computer: radar target dx";
CM_ SG_ 698 UI_radarTargetDxEnd "Touchscreen user interface computer: radar target dx end";
CM_ SG_ 698 UI_radarTargetTrustMap "Touchscreen user interface computer: radar target trust map";
CM_ SG_ 698 UI_radarEnableBraking "Touchscreen user interface computer: radar enable braking";
CM_ SG_ 698 UI_radarMapDataCounter "Touchscreen user interface computer: radar map data counter";
CM_ SG_ 698 UI_radarMapDataChecksum "Touchscreen user interface computer: radar map data checksum";
CM_ BO_ 826 "Touchscreen user interface computer message: range";
CM_ SG_ 826 UI_ratedRange "Rated range in miles";
CM_ SG_ 826 UI_whpm "Touchscreen user interface computer: whpm";
CM_ SG_ 826 UI_soe "State of energy";
CM_ SG_ 826 UI_uSoe "Usable state of energy";
CM_ SG_ 826 UI_softPackLimitPct "Touchscreen user interface computer: soft pack limit pct";
CM_ SG_ 826 UI_targetFullPackEnergy "Touchscreen user interface computer: target full pack energy";
CM_ BO_ 632 "Touchscreen user interface computer message: road curvature";
CM_ SG_ 632 UI_roadCurvC0 "Touchscreen user interface computer: road curv C0";
CM_ SG_ 632 UI_roadCurvC1 "Touchscreen user interface computer: road curv C1";
CM_ SG_ 632 UI_roadCurvC2 "Touchscreen user interface computer: road curv C2";
CM_ SG_ 632 UI_roadCurvC3 "Touchscreen user interface computer: road curv C3";
CM_ SG_ 632 UI_roadCurvRange "Touchscreen user interface computer: road curv range";
CM_ SG_ 632 UI_roadCurvHealth "Touchscreen user interface computer: road curv health";
CM_ SG_ 632 UI_roadCurvChecksum "Touchscreen user interface computer: road curv checksum";
CM_ BO_ 723 "Touchscreen user interface computer message: solar data";
CM_ SG_ 723 UI_solarAzimuthAngle "Touchscreen user interface computer: solar azimuth angle; raw 32768 = signal not available (SNA)";
CM_ SG_ 723 UI_solarAzimuthAngleCarRef "Touchscreen user interface computer: solar azimuth angle car ref; raw 255 = signal not available (SNA)";
CM_ SG_ 723 UI_isSunUp "is sun up; raw 3 = signal not available (SNA)";
CM_ SG_ 723 UI_solarElevationAngle "Solar Elevation Angle; raw 127 = signal not available (SNA)";
CM_ SG_ 723 UI_screenPCBTemperature "Temperature of display PCB";
CM_ SG_ 723 UI_minsToSunset "time until to sunset";
CM_ SG_ 723 UI_minsToSunrise "time until to sunrise";
CM_ BO_ 563 "Touchscreen user interface computer message: stalkless control";
CM_ SG_ 563 UI_stalklessControlCounter "Touchscreen user interface computer: stalkless control counter";
CM_ SG_ 563 UI_stalklessControlChecksum "Touchscreen user interface computer: stalkless control checksum";
CM_ SG_ 563 UI_gearStripSuppressCounter "Touchscreen user interface computer: gear strip suppress counter";
CM_ SG_ 563 UI_gearRequest "UI gear request from UI; raw 0 = signal not available (SNA)";
CM_ SG_ 563 UI_autopilotRequest "Touchscreen user interface computer: autopilot request";
CM_ SG_ 563 UI_fullScreenMode "Aggregates all situations with which the UI is using the entire screen so stalkless gear controls are not present";
CM_ SG_ 563 UI_gearStripShowing "UI communicating to GTW that the gear strip is visible on the screen as part of a handshake";
CM_ SG_ 563 UI_gearStripLocation "Touchscreen user interface computer: gear strip location";
CM_ SG_ 563 UI_parkButtonShowing "Touchscreen user interface computer: park button showing";
CM_ SG_ 563 UI_neutralButtonShowing "Touchscreen user interface computer: neutral button showing";
CM_ SG_ 563 UI_gearStripForceShow "UI request to GTW to show the gear strip";
CM_ SG_ 563 UI_neutralButtonDrawerForceShow "Touchscreen user interface computer: neutral button drawer force show";
CM_ SG_ 563 UI_autoParkAvailable "UI communicating to GTW that the autpark functionality is available";
CM_ SG_ 563 UI_autoParkShowing "Touchscreen user interface computer: auto park showing";
CM_ SG_ 563 UI_gearStripSuppressActive "UI communicating to GTW that the gear strip should not be shown";
CM_ SG_ 563 UI_gearNeutralPressed "Neutral button is being pressed";
CM_ BO_ 699 "Touchscreen user interface computer message: stalkless health status";
CM_ SG_ 699 UI_centerDisplayRunning "is center display running";
CM_ SG_ 699 UI_centerDisplaySM "Touchscreen user interface computer: center display SM";
CM_ SG_ 699 UI_centerDisplayPowerOn "center display power on";
CM_ SG_ 699 UI_centerDisplayCrtcOk "Touchscreen user interface computer: center display crtc ok";
CM_ SG_ 699 UI_centerDisplayHardwareOk "Touchscreen user interface computer: center display hardware ok";
CM_ SG_ 699 UI_centerDisplayWindowManagerOk "Touchscreen user interface computer: center display window manager ok";
CM_ SG_ 699 UI_centerDisplayCompositorOk "Touchscreen user interface computer: center display compositor ok";
CM_ BO_ 851 "Touchscreen user interface computer message: status";
CM_ SG_ 851 UI_touchActive "No touchscreen errors";
CM_ SG_ 851 UI_audioActive "Audio system is ready.";
CM_ SG_ 851 UI_bluetoothActive "Touchscreen user interface computer: bluetooth active";
CM_ SG_ 851 UI_cellActive "Cell is powered";
CM_ SG_ 851 UI_displayReady "UI is ready (GUI_allReady) and display is ok (GUI_displayHardwareOK)";
CM_ SG_ 851 UI_displayOn "UI display on/off status";
CM_ SG_ 851 UI_wifiActive "WiFi active.";
CM_ SG_ 851 UI_wifiConnected "WiFi Connected.";
CM_ SG_ 851 UI_systemActive "Touchscreen user interface computer: system active";
CM_ SG_ 851 UI_readyForDrive "Ready for drive (UI ready or self park request)";
CM_ SG_ 851 UI_cellConnected "Detects if the cell is connected to a network.";
CM_ SG_ 851 UI_vpnActive "VPN connected.";
CM_ SG_ 851 UI_autopilotTrial "Touchscreen user interface computer: autopilot trial";
CM_ SG_ 851 UI_factoryReset "UI request for factory reset; raw 0 = signal not available (SNA)";
CM_ SG_ 851 UI_gpsActive "GPS has valid fix";
CM_ SG_ 851 UI_screenshotActive "Touchscreen user interface computer: screenshot active";
CM_ SG_ 851 UI_radioActive "Touchscreen user interface computer: radio active";
CM_ SG_ 851 UI_cellNetworkTechnology "Describes the type of cellular network to which the car computer is connected: GPRS_2G(114Kbps) < EGDE_2G(368Kbps) < 3G(3Mbps) < HSDPA_3G(14Mbps) < HSPAplus_4Gg(168Mbps) < 4G_LTE(299Mbps); raw 15 = signal not available (SNA)";
CM_ SG_ 851 UI_cellReceiverPower "Touchscreen user interface computer: cell receiver power";
CM_ SG_ 851 UI_falseTouchCounter "Count false touches after display is off.";
CM_ SG_ 851 UI_developmentCar "Touchscreen user interface computer: development car";
CM_ SG_ 851 UI_cameraActive "Touchscreen user interface computer: camera active";
CM_ SG_ 851 UI_cellSignalBars "Number of cellular signal bars displayed on the UI, derived from cellSignalStrength; raw 7 = signal not available (SNA)";
CM_ SG_ 851 UI_trailerModeTelltale "Color of the trailer mode telltale";
CM_ SG_ 851 UI_pcbTemperature "PCB digital temp sensor reading in DegC";
CM_ SG_ 851 UI_cpuTemperature "Apollo Lake SOC temperature in DegC";
CM_ BO_ 991 "Touchscreen user interface computer message: status2";
CM_ SG_ 991 UI_mobileAppStepCount "Touchscreen user interface computer: mobile app step count";
CM_ SG_ 991 UI_userRequestSnapshot "Touchscreen user interface computer: user request snapshot";
CM_ SG_ 991 UI_touchDetected "Touchscreen user interface computer: touch detected";
CM_ SG_ 991 UI_validDeviceForEUSummon "Touchscreen user interface computer: valid device for EU summon";
CM_ SG_ 991 UI_locatedAtHome "Touchscreen user interface computer: located at home";
CM_ SG_ 991 UI_locatedAtWork "Touchscreen user interface computer: located at work";
CM_ SG_ 991 UI_locatedAtFavorite "Touchscreen user interface computer: located at favorite";
CM_ SG_ 991 UI_displayInDarkMode "Touchscreen user interface computer: display in dark mode";
CM_ SG_ 991 UI_userActivity "Indicates user interaction with the center display";
CM_ SG_ 991 UI_activeTouchPoints "Quantity of active touch points on the Center Display";
CM_ SG_ 991 UI_linkState "Connectivity link state";
CM_ SG_ 991 UI_sentryModeState "Touchscreen user interface computer: sentry mode state; raw 6 = signal not available (SNA)";
CM_ SG_ 991 UI_autopilotSentryRequest "whether AP sentry mode should be enabled";
CM_ SG_ 991 UI_mobileAppConnected "Reports if Web Real-Time Communication (WebRTC) connection is connected while summon screen is open on the mobile app.";
CM_ SG_ 991 UI_autoshiftDRState "Reports the User Interface (UI) autoshift Drive/Reverse state.";
CM_ SG_ 991 UI_wifiBtModuleType "Reports the type of Wi-Fi and Bluetooth (BT) module.";
CM_ SG_ 991 UI_sohHealthStatus "Touchscreen user interface computer: soh health status";
CM_ SG_ 991 UI_selfParkState "Reports the auto park state changes.; raw 255 = signal not available (SNA)";
CM_ SG_ 991 UI_summonDeviceIndex "Reports which device is being used to control summon.";
CM_ SG_ 991 UI_sentryModeCameraDetection "Touchscreen user interface computer: sentry mode camera detection";
CM_ SG_ 991 UI_wakeOnIPActive "Touchscreen user interface computer: wake on IP active";
CM_ BO_ 988 "Touchscreen user interface computer message: summon goal";
CM_ SG_ 988 UI_goalLatitude "Touchscreen user interface computer: goal latitude";
CM_ SG_ 988 UI_goalLongitude "Touchscreen user interface computer: goal longitude";
CM_ SG_ 988 UI_goalOrientation "Touchscreen user interface computer: goal orientation";
CM_ BO_ 663 "Touchscreen user interface computer message: suspension control";
CM_ SG_ 663 UI_adaptiveRideRequest "UI customer adaptive ride request for air suspension.";
CM_ SG_ 663 UI_suspensionLoweringRequest "Touchscreen user interface computer: suspension lowering request; raw 3 = signal not available (SNA)";
CM_ SG_ 663 UI_geofenceLevelingRequest "Geofence level request from customer; raw 5 = signal not available (SNA)";
CM_ SG_ 663 UI_jackModeToggleRequest "Touchscreen user interface computer: jack mode toggle request";
CM_ SG_ 663 UI_adaptiveTuningRequest0 "Touchscreen user interface computer: adaptive tuning request0";
CM_ SG_ 663 UI_adaptiveTuningRequest1 "Touchscreen user interface computer: adaptive tuning request1";
CM_ SG_ 663 UI_roadRoughnessLookahead "Touchscreen user interface computer: road roughness lookahead; raw 127 = signal not available (SNA)";
CM_ SG_ 663 UI_roadRoughnessStart "Touchscreen user interface computer: road roughness start; raw 31 = signal not available (SNA)";
CM_ SG_ 663 UI_mapVersionUsed "Touchscreen user interface computer: map version used; raw 255 = signal not available (SNA)";
CM_ SG_ 663 UI_suspensionControlCounter "Touchscreen user interface computer: suspension control counter";
CM_ SG_ 663 UI_suspensionLevelRequest "Touchscreen user interface computer: suspension level request";
CM_ SG_ 663 UI_suspensionControlChecksum "Touchscreen user interface computer: suspension control checksum";
CM_ BO_ 661 "Touchscreen user interface computer message: system monitor";
CM_ SG_ 661 UI_systemMonitorIndex "Touchscreen user interface computer: system monitor index";
CM_ SG_ 661 UI_SystemMemUsage "Monitors system memory usage";
CM_ SG_ 661 UI_QtCarMemUsage "Monitors memory usage of the primary User Interface application";
CM_ SG_ 661 UI_QtCarCPUUsage "Monitors CPU usage of the primary User Interface application";
CM_ SG_ 661 UI_emmcStatus "Touchscreen user interface computer: emmc status";
CM_ SG_ 661 UI_SystemCPUUsage "Monitors system CPU usage";
CM_ SG_ 661 UI_HomeHealth "Touchscreen user interface computer: home health";
CM_ SG_ 661 UI_VarHealth "Touchscreen user interface computer: var health";
CM_ SG_ 661 UI_LogHealth "Touchscreen user interface computer: log health";
CM_ SG_ 661 UI_TmpfsHealth "Touchscreen user interface computer: tmpfs health";
CM_ SG_ 661 UI_emmcDataWritten "Touchscreen user interface computer: emmc data written";
CM_ SG_ 661 UI_emmcTotalErases "Touchscreen user interface computer: emmc total erases";
CM_ BO_ 1064 "Touchscreen user interface computer message: telemetry control";
CM_ SG_ 1064 UI_TCR_enable "Touchscreen user interface computer: TCR enable";
CM_ SG_ 1064 UI_TCR_moveStateStanding "Touchscreen user interface computer: TCR move state standing";
CM_ SG_ 1064 UI_TCR_moveStateStopped "Touchscreen user interface computer: TCR move state stopped";
CM_ SG_ 1064 UI_TCR_moveStateMoving "Touchscreen user interface computer: TCR move state moving";
CM_ SG_ 1064 UI_TCR_moveStateIndeterm "Touchscreen user interface computer: TCR move state indeterm";
CM_ SG_ 1064 UI_TCR_classConstElem "Touchscreen user interface computer: TCR class const elem";
CM_ SG_ 1064 UI_TCR_classMovingPed "Touchscreen user interface computer: TCR class moving ped";
CM_ SG_ 1064 UI_TCR_classMovingTwoWheel "Touchscreen user interface computer: TCR class moving two wheel";
CM_ SG_ 1064 UI_TCR_classMovingFourWheel "Touchscreen user interface computer: TCR class moving four wheel";
CM_ SG_ 1064 UI_TCR_classUnknown "Touchscreen user interface computer: TCR class unknown";
CM_ SG_ 1064 UI_TCR_downSampleFactor "Touchscreen user interface computer: TCR down sample factor";
CM_ SG_ 1064 UI_TCR_wExist "Touchscreen user interface computer: TCR w exist";
CM_ SG_ 1064 UI_TCR_vehSpeed "Touchscreen user interface computer: TCR veh speed";
CM_ SG_ 1064 UI_TCR_minRCS "Touchscreen user interface computer: TCR min RCS";
CM_ SG_ 1064 UI_TCR_maxDy "Touchscreen user interface computer: TCR max dy";
CM_ SG_ 1064 UI_TCR_maxObjects "Touchscreen user interface computer: TCR max objects";
CM_ SG_ 1064 UI_TCR_maxRoadClass "Touchscreen user interface computer: TCR max road class";
CM_ BO_ 856 "Touchscreen user interface computer message: tpms mode";
CM_ SG_ 856 UI_TPMSMode "Touchscreen user interface computer: TPMS mode";
CM_ SG_ 856 UI_TPMSLearnIDMode "Touchscreen user interface computer: TPMS learn ID mode";
CM_ SG_ 856 UI_sizeOfWheelSelect "Touchscreen user interface computer: size of wheel select";
CM_ SG_ 856 UI_sizeOfReqCANAutoLearn "Touchscreen user interface computer: size of req CAN auto learn";
CM_ BO_ 952 "Touchscreen user interface computer message: tpms RC psetting";
CM_ SG_ 952 UI_setRCPFront "Touchscreen user interface computer: set RCP front";
CM_ SG_ 952 UI_setRCPRear "Touchscreen user interface computer: set RCP rear";
CM_ BO_ 787 "Touchscreen user interface computer message: track mode settings";
CM_ SG_ 787 UI_trackModeRequest "User selected track mode";
CM_ SG_ 787 UI_trackRotationTendency "Touchscreen user interface computer: track rotation tendency";
CM_ SG_ 787 UI_trackStabilityAssist "Touchscreen user interface computer: track stability assist";
CM_ SG_ 787 UI_trackPostCooling "Touchscreen user interface computer: track post cooling";
CM_ SG_ 787 UI_trackCmpOverclock "Touchscreen user interface computer: track cmp overclock";
CM_ SG_ 787 UI_trackModeBrakeTemps "Touchscreen user interface computer: track mode brake temps";
CM_ SG_ 787 UI_trackDrivePowerAvailability "Reports power deployment strategy for Track Mode. Ranges from endurance limit to maximum power.";
CM_ SG_ 787 UI_trackModeSettingsCounter "Touchscreen user interface computer: track mode settings counter";
CM_ SG_ 787 UI_trackModeSettingsChecksum "Touchscreen user interface computer: track mode settings checksum";
CM_ BO_ 130 "Touchscreen user interface computer message: trip planning";
CM_ SG_ 130 UI_tripPlanningActive "Indicates that there is active route in navigation with a valid energy at destination prediction.";
CM_ SG_ 130 UI_navToSupercharger "Navigation destination is a supercharger";
CM_ SG_ 130 UI_navFastchargerType "when navigation is turned on, this enum identifies the type of fastcharger the car is navigating to based on the rated power from sc_locations";
CM_ SG_ 130 UI_battPreconditionOnNavState "Indicates to battery and thermal systems whether the battery should be actively heated, passively heated, actively cooled, or passively cooled";
CM_ SG_ 130 UI_requestActiveBatteryHeating "Flag to request BMS enable active battery heating";
CM_ SG_ 130 UI_battPreconditionOnNavPowerReq "The preconditioning power that Trip Planner is requesting from the thermal system to use for battery preconditioning (cooling or heating).; raw 127 = signal not available (SNA)";
CM_ SG_ 130 UI_battPreconditionOnNavTargetT "The pack temperature that Trip Planner is targeting upon arriving to a fast charger.; raw 255 = signal not available (SNA)";
CM_ SG_ 130 UI_ambientTempAtDestination "Touchscreen user interface computer: ambient temp at destination; raw 128 = signal not available (SNA)";
CM_ SG_ 130 UI_energyAtDestination "expected energy at destination in kWh for current navigation route; raw 32768 = signal not available (SNA)";
CM_ BO_ 139 "Touchscreen user interface computer message: trip planning2";
CM_ SG_ 139 UI_maxSpeedToReachDestination "maximum speed to reach destination without significant risk of running out of energy; raw 65535 = signal not available (SNA)";
CM_ SG_ 139 UI_remainingWeightedRMSSpeed "Touchscreen user interface computer: remaining weighted RMS speed; raw 65535 = signal not available (SNA)";
CM_ SG_ 139 UI_timeToDestination "remaining time to reach destination; raw 65535 = signal not available (SNA)";
CM_ BO_ 1173 "Touchscreen user interface computer message: trip planning3";
CM_ SG_ 1173 UI_predictedEnergy "initially predicted energy in kWh for current location along navigation route; raw 32768 = signal not available (SNA)";
CM_ SG_ 1173 UI_predictedEnergyLearned "Touchscreen user interface computer: predicted energy learned; raw 32768 = signal not available (SNA)";
CM_ SG_ 1173 UI_hindsightEnergy "hindsight energy, the model predicted energy based on measured speed and acceleration for the current location along navigation route; raw 32768 = signal not available (SNA)";
CM_ SG_ 1173 UI_hindsightEnergyLearned "Touchscreen user interface computer: hindsight energy learned; raw 32768 = signal not available (SNA)";
CM_ BO_ 1174 "Touchscreen user interface computer message: trip planning4";
CM_ SG_ 1174 UI_longTermEnergyModelError "Touchscreen user interface computer: long term energy model error; raw 128 = signal not available (SNA)";
CM_ SG_ 1174 UI_longTermRmsSpeedRatio "Touchscreen user interface computer: long term rms speed ratio; raw 255 = signal not available (SNA)";
CM_ SG_ 1174 UI_gradeCorrectedEnergy "Touchscreen user interface computer: grade corrected energy; raw 32768 = signal not available (SNA)";
CM_ SG_ 1174 UI_gradeCorrectedEnergyLearned "Touchscreen user interface computer: grade corrected energy learned; raw 32768 = signal not available (SNA)";
CM_ BO_ 1175 "Touchscreen user interface computer message: trip planning5";
CM_ SG_ 1175 UI_battPreconditionOnNavTime "Touchscreen user interface computer: batt precondition on nav time; raw 65535 = signal not available (SNA)";
CM_ SG_ 1175 UI_maxBattPreconditionOnNavTime "Touchscreen user interface computer: max batt precondition on nav time; raw 65535 = signal not available (SNA)";
CM_ SG_ 1175 UI_tripPlanChargingTargetPercent "Touchscreen user interface computer: trip plan charging target percent; raw 1023 = signal not available (SNA)";
CM_ BO_ 1827 "Touchscreen user interface computer message: uss thresholds x";
CM_ SG_ 1827 UI_ussSensorIdX "Touchscreen user interface computer: uss sensor id x";
CM_ SG_ 1827 UI_ussThresholdX0 "Touchscreen user interface computer: uss threshold X0";
CM_ SG_ 1827 UI_ussThresholdX1 "Touchscreen user interface computer: uss threshold X1";
CM_ SG_ 1827 UI_ussThresholdX2 "Touchscreen user interface computer: uss threshold X2";
CM_ SG_ 1827 UI_ussThresholdX3 "Touchscreen user interface computer: uss threshold X3";
CM_ SG_ 1827 UI_ussThresholdX4 "Touchscreen user interface computer: uss threshold X4";
CM_ SG_ 1827 UI_ussThresholdX5 "Touchscreen user interface computer: uss threshold X5";
CM_ SG_ 1827 UI_ussThresholdX6 "Touchscreen user interface computer: uss threshold X6";
CM_ SG_ 1827 UI_ussThresholdX7 "Touchscreen user interface computer: uss threshold X7";
CM_ SG_ 1827 UI_ussThresholdX8 "Touchscreen user interface computer: uss threshold X8";
CM_ SG_ 1827 UI_ussThresholdX9 "Touchscreen user interface computer: uss threshold X9";
CM_ SG_ 1827 UI_ussThresholdX10 "Touchscreen user interface computer: uss threshold X10";
CM_ SG_ 1827 UI_ussThresholdX11 "Touchscreen user interface computer: uss threshold X11";
CM_ SG_ 1827 UI_ussThresholdXControl "Touchscreen user interface computer: uss threshold x control";
BA_DEF_ BO_ "GenMsgCycleTime" INT 0 3600000;
BA_DEF_ BO_ "GenMsgSendType" ENUM "Cyclic","NotUsed","NotUsed","NotUsed","NotUsed","NotUsed","NotUsed","IfActive","NoMsgSendType","NotUsed";
BA_DEF_ BO_ "VFrameFormat" ENUM "StandardCAN","ExtendedCAN","reserved","J1939PG","reserved","reserved","reserved","reserved","reserved","reserved","reserved","reserved","reserved","reserved","StandardCAN_FD","ExtendedCAN_FD";
BA_DEF_ BO_ "CANFD_BRS" ENUM "0","1";
BA_DEF_ SG_ "GenSigSNA" STRING;
BA_DEF_ SG_ "SystemSignalLongSymbol" STRING;
BA_DEF_ SG_ "Confidence" ENUM "validated","plausible","layout-only","contradicted";
BA_DEF_DEF_ "GenMsgCycleTime" 0;
BA_DEF_DEF_ "GenMsgSendType" "NoMsgSendType";
BA_DEF_DEF_ "VFrameFormat" "StandardCAN";
BA_DEF_DEF_ "CANFD_BRS" "1";
BA_DEF_DEF_ "GenSigSNA" "";
BA_DEF_DEF_ "SystemSignalLongSymbol" "";
BA_DEF_DEF_ "Confidence" "layout-only";
BA_ "GenMsgCycleTime" BO_ 1021 500;
BA_ "GenMsgSendType" BO_ 1021 0;
BA_ "GenMsgCycleTime" BO_ 819 500;
BA_ "GenMsgSendType" BO_ 819 0;
BA_ "GenMsgCycleTime" BO_ 659 500;
BA_ "GenMsgSendType" BO_ 659 0;
BA_ "GenMsgCycleTime" BO_ 531 500;
BA_ "GenMsgSendType" BO_ 531 0;
BA_ "GenMsgCycleTime" BO_ 664 500;
BA_ "GenMsgSendType" BO_ 664 0;
BA_ "GenMsgCycleTime" BO_ 679 500;
BA_ "GenMsgSendType" BO_ 679 0;
BA_ "GenMsgCycleTime" BO_ 1280 5000;
BA_ "GenMsgSendType" BO_ 1280 0;
BA_ "GenMsgCycleTime" BO_ 2043 2000;
BA_ "GenMsgSendType" BO_ 2043 0;
BA_ "GenMsgCycleTime" BO_ 1096 1000;
BA_ "GenMsgSendType" BO_ 1096 0;
BA_ "GenMsgCycleTime" BO_ 1016 1000;
BA_ "GenMsgSendType" BO_ 1016 0;
BA_ "GenMsgCycleTime" BO_ 568 500;
BA_ "GenMsgSendType" BO_ 568 0;
BA_ "GenMsgCycleTime" BO_ 536 500;
BA_ "GenMsgSendType" BO_ 536 0;
BA_ "GenMsgCycleTime" BO_ 645 500;
BA_ "GenMsgSendType" BO_ 645 0;
BA_ "GenMsgCycleTime" BO_ 647 500;
BA_ "GenMsgSendType" BO_ 647 0;
BA_ "GenMsgCycleTime" BO_ 1971 500;
BA_ "GenMsgSendType" BO_ 1971 0;
BA_ "GenMsgCycleTime" BO_ 984 1000;
BA_ "GenMsgSendType" BO_ 984 0;
BA_ "GenMsgCycleTime" BO_ 1279 1000;
BA_ "GenMsgSendType" BO_ 1279 0;
BA_ "GenMsgCycleTime" BO_ 1139 500;
BA_ "GenMsgSendType" BO_ 1139 0;
BA_ "GenMsgCycleTime" BO_ 1267 500;
BA_ "GenMsgSendType" BO_ 1267 0;
BA_ "GenMsgCycleTime" BO_ 804 1000;
BA_ "GenMsgSendType" BO_ 804 0;
BA_ "GenMsgCycleTime" BO_ 985 1000;
BA_ "GenMsgSendType" BO_ 985 0;
BA_ "GenMsgCycleTime" BO_ 755 500;
BA_ "GenMsgSendType" BO_ 755 0;
BA_ "GenMsgCycleTime" BO_ 989 1000;
BA_ "GenMsgSendType" BO_ 989 0;
BA_ "GenMsgCycleTime" BO_ 79 1000;
BA_ "GenMsgSendType" BO_ 79 0;
BA_ "GenMsgCycleTime" BO_ 1011 1000;
BA_ "GenMsgSendType" BO_ 1011 0;
BA_ "GenMsgCycleTime" BO_ 443 500;
BA_ "GenMsgSendType" BO_ 443 0;
BA_ "GenMsgCycleTime" BO_ 987 1000;
BA_ "GenMsgSendType" BO_ 987 0;
BA_ "GenMsgCycleTime" BO_ 955 1000;
BA_ "GenMsgSendType" BO_ 955 0;
BA_ "GenMsgCycleTime" BO_ 827 1000;
BA_ "GenMsgSendType" BO_ 827 0;
BA_ "GenMsgCycleTime" BO_ 629 5000;
BA_ "GenMsgSendType" BO_ 629 0;
BA_ "GenMsgCycleTime" BO_ 820 500;
BA_ "GenMsgSendType" BO_ 820 0;
BA_ "GenMsgCycleTime" BO_ 698 500;
BA_ "GenMsgSendType" BO_ 698 0;
BA_ "GenMsgCycleTime" BO_ 826 1000;
BA_ "GenMsgSendType" BO_ 826 0;
BA_ "GenMsgCycleTime" BO_ 632 500;
BA_ "GenMsgSendType" BO_ 632 0;
BA_ "GenMsgCycleTime" BO_ 723 1000;
BA_ "GenMsgSendType" BO_ 723 0;
BA_ "GenMsgCycleTime" BO_ 563 500;
BA_ "GenMsgSendType" BO_ 563 0;
BA_ "GenMsgCycleTime" BO_ 699 500;
BA_ "GenMsgSendType" BO_ 699 0;
BA_ "GenMsgCycleTime" BO_ 851 1000;
BA_ "GenMsgSendType" BO_ 851 0;
BA_ "GenMsgCycleTime" BO_ 991 500;
BA_ "GenMsgSendType" BO_ 991 0;
BA_ "GenMsgCycleTime" BO_ 988 1000;
BA_ "GenMsgSendType" BO_ 988 0;
BA_ "GenMsgCycleTime" BO_ 663 500;
BA_ "GenMsgSendType" BO_ 663 0;
BA_ "GenMsgCycleTime" BO_ 661 15000;
BA_ "GenMsgSendType" BO_ 661 0;
BA_ "GenMsgCycleTime" BO_ 1064 1000;
BA_ "GenMsgSendType" BO_ 1064 0;
BA_ "GenMsgCycleTime" BO_ 952 1000;
BA_ "GenMsgSendType" BO_ 952 0;
BA_ "GenMsgCycleTime" BO_ 787 500;
BA_ "GenMsgSendType" BO_ 787 0;
BA_ "GenMsgCycleTime" BO_ 130 1000;
BA_ "GenMsgSendType" BO_ 130 0;
BA_ "GenMsgCycleTime" BO_ 139 1000;
BA_ "GenMsgSendType" BO_ 139 0;
BA_ "GenMsgCycleTime" BO_ 1173 1000;
BA_ "GenMsgSendType" BO_ 1173 0;
BA_ "GenMsgCycleTime" BO_ 1174 1000;
BA_ "GenMsgSendType" BO_ 1174 0;
BA_ "GenMsgCycleTime" BO_ 1175 1000;
BA_ "GenMsgSendType" BO_ 1175 0;
BA_ "Confidence" SG_ 1021 UI_autopilotControlIndex 1;
BA_ "Confidence" SG_ 1021 UI_hovEnabled 0;
BA_ "Confidence" SG_ 1021 UI_donDisableAutoWiperDuration 1;
BA_ "Confidence" SG_ 1021 UI_donDisableOnAutoWiperSpeed 1;
BA_ "Confidence" SG_ 1021 UI_blindspotMinSpeed 1;
BA_ "Confidence" SG_ 1021 UI_blindspotDistance 1;
BA_ "Confidence" SG_ 1021 UI_blindspotTTC 1;
BA_ "Confidence" SG_ 1021 UI_donStopEndOfRampBuffer 1;
BA_ "Confidence" SG_ 1021 UI_donDisableCutin 1;
BA_ "Confidence" SG_ 1021 UI_smartSetSpeedOffset 0;
BA_ "Confidence" SG_ 1021 UI_smartSetSpeedOffsetType 0;
BA_ "Confidence" SG_ 1021 UI_fsdStopsControlEnabled 0;
BA_ "Confidence" SG_ 1021 UI_smartSetSpeed 0;
BA_ "Confidence" SG_ 1021 UI_automaticSetSpeedOffset 0;
BA_ "Confidence" SG_ 1021 UI_homelinkNearby 1;
BA_ "Confidence" SG_ 1021 UI_enableFullSelfDriving 0;
BA_ "Confidence" SG_ 1021 UI_hasFullSelfDriving 0;
BA_ "Confidence" SG_ 1021 UI_autosteerActivation 0;
BA_ "Confidence" SG_ 1021 UI_autopilotDrivingProfile 1;
BA_ "Confidence" SG_ 1021 UI_fsdBetaRequest 0;
BA_ "Confidence" SG_ 1021 UI_fullSelfDrivingSuspended 0;
BA_ "Confidence" SG_ 1021 UI_disableOptionalLaneChanges 0;
BA_ "Confidence" SG_ 1021 UI_selectableCameraRequest 0;
BA_ "GenSigSNA" SG_ 1021 UI_selectableCameraRequest "15";
BA_ "Confidence" SG_ 1021 UI_overrideSleepWithSuspend 1;
BA_ "Confidence" SG_ 1021 UI_driverMonitorConfirmation 0;
BA_ "Confidence" SG_ 1021 UI_parkAssistUseVision 0;
BA_ "Confidence" SG_ 1021 UI_noStalkConfirmAlertHaptic 0;
BA_ "Confidence" SG_ 1021 UI_regulatoryLaneAssistLevel 1;
BA_ "Confidence" SG_ 1021 UI_noStalkConfirmAlertChime 0;
BA_ "Confidence" SG_ 1021 UI_factorySummonEnable 0;
BA_ "Confidence" SG_ 1021 UI_apmv3Branch 1;
BA_ "Confidence" SG_ 1021 UI_enableCabinCamera 0;
BA_ "Confidence" SG_ 1021 UI_enableAutopilotStopWarning 0;
BA_ "Confidence" SG_ 1021 UI_enableVisionSpeedControl 0;
BA_ "Confidence" SG_ 1021 UI_enableTeslaAutopark 0;
BA_ "Confidence" SG_ 1021 UI_autoTurnSignalMode 0;
BA_ "Confidence" SG_ 1021 UI_enableCabinAudioRecording 0;
BA_ "SystemSignalLongSymbol" SG_ 1021 UI_enableApproachingEmergencyVeh "UI_enableApproachingEmergencyVehicleDetection";
BA_ "SystemSignalLongSymbol" SG_ 1021 UI_enableStartFsdFromParkBrakeCo "UI_enableStartFsdFromParkBrakeConfirmation";
BA_ "Confidence" SG_ 1021 UI_fsdMaxSpeedOffsetPercentage 1;
BA_ "Confidence" SG_ 819 UI_openChargePortDoorRequest 0;
BA_ "Confidence" SG_ 819 UI_closeChargePortDoorRequest 0;
BA_ "Confidence" SG_ 819 UI_chargeEnableRequest 0;
BA_ "Confidence" SG_ 819 UI_brickVLoggingRequest 1;
BA_ "Confidence" SG_ 819 UI_brickBalancingDisabled 1;
BA_ "Confidence" SG_ 819 UI_dSocAlertThreshold 1;
BA_ "Confidence" SG_ 819 UI_acChargeCurrentLimit 0;
BA_ "GenSigSNA" SG_ 819 UI_acChargeCurrentLimit "127";
BA_ "Confidence" SG_ 819 UI_dSocAlertEnable 1;
BA_ "Confidence" SG_ 819 UI_chargeTerminationPct 0;
BA_ "Confidence" SG_ 819 UI_scheduledDepartureEnabled 0;
BA_ "Confidence" SG_ 819 UI_chargePortLatchRequest 0;
BA_ "Confidence" SG_ 819 UI_socSnapshotExpirationTime 1;
BA_ "Confidence" SG_ 819 UI_cpInletHeaterRequest 0;
BA_ "Confidence" SG_ 659 UI_steeringTuneRequest 0;
BA_ "Confidence" SG_ 659 UI_tractionControlMode 0;
BA_ "Confidence" SG_ 659 UI_parkBrakeRequest 0;
BA_ "GenSigSNA" SG_ 659 UI_parkBrakeRequest "3";
BA_ "Confidence" SG_ 659 UI_winchModeRequest 0;
BA_ "Confidence" SG_ 659 UI_zeroSpeedConfirmed 1;
BA_ "GenSigSNA" SG_ 659 UI_zeroSpeedConfirmed "3";
BA_ "Confidence" SG_ 659 UI_trailerMode 0;
BA_ "Confidence" SG_ 659 UI_distanceUnits 1;
BA_ "Confidence" SG_ 659 UI_accOvertakeEnable 0;
BA_ "GenSigSNA" SG_ 659 UI_accOvertakeEnable "3";
BA_ "Confidence" SG_ 659 UI_aebEnable 0;
BA_ "GenSigSNA" SG_ 659 UI_aebEnable "3";
BA_ "Confidence" SG_ 659 UI_aesEnable 0;
BA_ "GenSigSNA" SG_ 659 UI_aesEnable "3";
BA_ "Confidence" SG_ 659 UI_ahlbEnable 0;
BA_ "GenSigSNA" SG_ 659 UI_ahlbEnable "3";
BA_ "Confidence" SG_ 659 UI_autoLaneChangeEnable 0;
BA_ "GenSigSNA" SG_ 659 UI_autoLaneChangeEnable "3";
BA_ "Confidence" SG_ 659 UI_winchProxUserOverride 0;
BA_ "Confidence" SG_ 659 UI_autoParkRequest 0;
BA_ "GenSigSNA" SG_ 659 UI_autoParkRequest "15";
BA_ "Confidence" SG_ 659 UI_bsdEnable 0;
BA_ "GenSigSNA" SG_ 659 UI_bsdEnable "3";
BA_ "Confidence" SG_ 659 UI_fcwEnable 0;
BA_ "GenSigSNA" SG_ 659 UI_fcwEnable "3";
BA_ "Confidence" SG_ 659 UI_fcwSensitivity 0;
BA_ "GenSigSNA" SG_ 659 UI_fcwSensitivity "3";
BA_ "Confidence" SG_ 659 UI_latControlEnable 0;
BA_ "GenSigSNA" SG_ 659 UI_latControlEnable "3";
BA_ "Confidence" SG_ 659 UI_ldwEnable 0;
BA_ "GenSigSNA" SG_ 659 UI_ldwEnable "3";
BA_ "Confidence" SG_ 659 UI_pedalSafetyEnable 1;
BA_ "GenSigSNA" SG_ 659 UI_pedalSafetyEnable "3";
BA_ "Confidence" SG_ 659 UI_pedalMap_epas 1;
BA_ "Confidence" SG_ 659 UI_redLightStopSignEnable 1;
BA_ "GenSigSNA" SG_ 659 UI_redLightStopSignEnable "3";
BA_ "Confidence" SG_ 659 UI_selfParkTune 1;
BA_ "GenSigSNA" SG_ 659 UI_selfParkTune "15";
BA_ "Confidence" SG_ 531 UI_cruiseSpeedCommand 0;
BA_ "Confidence" SG_ 664 UI_csaOfframpCurvC2 1;
BA_ "Confidence" SG_ 664 UI_csaOfframpCurvC3 1;
BA_ "Confidence" SG_ 664 UI_csaOfframpCurvRange 1;
BA_ "Confidence" SG_ 679 UI_csaRoadCurvC2 1;
BA_ "Confidence" SG_ 679 UI_csaRoadCurvC3 1;
BA_ "Confidence" SG_ 679 UI_csaRoadCurvRange 1;
BA_ "Confidence" SG_ 1280 UI_debugEcuTarget 1;
BA_ "Confidence" SG_ 2043 UI_debugDampingRequestFLC 1;
BA_ "GenSigSNA" SG_ 2043 UI_debugDampingRequestFLC "255";
BA_ "Confidence" SG_ 2043 UI_debugDampingRequestFLR 1;
BA_ "GenSigSNA" SG_ 2043 UI_debugDampingRequestFLR "255";
BA_ "Confidence" SG_ 2043 UI_debugDampingRequestFRC 1;
BA_ "GenSigSNA" SG_ 2043 UI_debugDampingRequestFRC "255";
BA_ "Confidence" SG_ 2043 UI_debugDampingRequestFRR 1;
BA_ "GenSigSNA" SG_ 2043 UI_debugDampingRequestFRR "255";
BA_ "Confidence" SG_ 2043 UI_debugDampingRequestRLC 1;
BA_ "GenSigSNA" SG_ 2043 UI_debugDampingRequestRLC "255";
BA_ "Confidence" SG_ 2043 UI_debugDampingRequestRLR 1;
BA_ "GenSigSNA" SG_ 2043 UI_debugDampingRequestRLR "255";
BA_ "Confidence" SG_ 2043 UI_debugDampingRequestRRC 1;
BA_ "GenSigSNA" SG_ 2043 UI_debugDampingRequestRRC "255";
BA_ "Confidence" SG_ 2043 UI_debugDampingRequestRRR 1;
BA_ "GenSigSNA" SG_ 2043 UI_debugDampingRequestRRR "255";
BA_ "Confidence" SG_ 1096 UI_anonDebugFlag1 1;
BA_ "Confidence" SG_ 1096 UI_anonDebugFlag2 1;
BA_ "Confidence" SG_ 1096 UI_anonDebugFlag3 1;
BA_ "Confidence" SG_ 1096 UI_anonDebugFlag4 1;
BA_ "Confidence" SG_ 1016 UI_autopilotControlRequest 1;
BA_ "Confidence" SG_ 1016 UI_ulcStalkConfirm 0;
BA_ "Confidence" SG_ 1016 UI_curvSpeedAdaptDisable 1;
BA_ "Confidence" SG_ 1016 UI_lssLkaEnabled 0;
BA_ "Confidence" SG_ 1016 UI_lssLdwEnabled 0;
BA_ "Confidence" SG_ 1016 UI_exceptionListEnable 1;
BA_ "Confidence" SG_ 1016 UI_roadCheckDisable 1;
BA_ "Confidence" SG_ 1016 UI_driveOnMapsEnable 0;
BA_ "Confidence" SG_ 1016 UI_handsOnRequirementDisable 1;
BA_ "Confidence" SG_ 1016 UI_fuseLanesDisable 1;
BA_ "Confidence" SG_ 1016 UI_fuseHPPDisable 1;
BA_ "Confidence" SG_ 1016 UI_fuseVehiclesDisable 1;
BA_ "Confidence" SG_ 1016 UI_visionSpeedType 1;
BA_ "Confidence" SG_ 1016 UI_curvatureDatabaseOnly 1;
BA_ "Confidence" SG_ 1016 UI_lssElkEnabled 0;
BA_ "Confidence" SG_ 1016 UI_summonExitType 1;
BA_ "GenSigSNA" SG_ 1016 UI_summonExitType "3";
BA_ "Confidence" SG_ 1016 UI_summonEntryType 1;
BA_ "GenSigSNA" SG_ 1016 UI_summonEntryType "3";
BA_ "Confidence" SG_ 1016 UI_selfParkRequest 0;
BA_ "GenSigSNA" SG_ 1016 UI_selfParkRequest "15";
BA_ "Confidence" SG_ 1016 UI_summonReverseDist 1;
BA_ "GenSigSNA" SG_ 1016 UI_summonReverseDist "63";
BA_ "Confidence" SG_ 1016 UI_drivingSide 1;
BA_ "Confidence" SG_ 1016 UI_accFollowDistanceSetting 1;
BA_ "GenSigSNA" SG_ 1016 UI_accFollowDistanceSetting "7";
BA_ "Confidence" SG_ 1016 UI_followNavRouteEnable 0;
BA_ "Confidence" SG_ 1016 UI_ulcSpeedConfig 0;
BA_ "Confidence" SG_ 1016 UI_ulcBlindSpotConfig 1;
BA_ "Confidence" SG_ 1016 UI_suppressExitPassingLane 0;
BA_ "Confidence" SG_ 1016 UI_smartSummonType 0;
BA_ "Confidence" SG_ 1016 UI_source3D 1;
BA_ "Confidence" SG_ 1016 UI_isaSpeedingChimeMuted 0;
BA_ "Confidence" SG_ 568 UI_mapSpeedLimitDependency 1;
BA_ "GenSigSNA" SG_ 568 UI_mapSpeedLimitDependency "7";
BA_ "Confidence" SG_ 568 UI_roadClass 0;
BA_ "GenSigSNA" SG_ 568 UI_roadClass "0";
BA_ "Confidence" SG_ 568 UI_mapSpeedUnits 1;
BA_ "Confidence" SG_ 568 UI_mapSpeedLimit 1;
BA_ "GenSigSNA" SG_ 568 UI_mapSpeedLimit "31";
BA_ "Confidence" SG_ 568 UI_mapSpeedLimitType 1;
BA_ "GenSigSNA" SG_ 568 UI_mapSpeedLimitType "7";
BA_ "Confidence" SG_ 568 UI_countryCode 1;
BA_ "GenSigSNA" SG_ 568 UI_countryCode "1023";
BA_ "Confidence" SG_ 568 UI_navRouteActive 0;
BA_ "Confidence" SG_ 568 UI_parallelAutoparkEnabled 0;
BA_ "Confidence" SG_ 568 UI_perpendicularAutoparkEnabled 0;
BA_ "Confidence" SG_ 568 UI_nextBranchDist 1;
BA_ "GenSigSNA" SG_ 568 UI_nextBranchDist "31";
BA_ "Confidence" SG_ 568 UI_controlledAccess 0;
BA_ "Confidence" SG_ 568 UI_autosteerRestricted 0;
BA_ "Confidence" SG_ 536 UI_roadSign 1;
BA_ "GenSigSNA" SG_ 536 UI_roadSign "255";
BA_ "Confidence" SG_ 536 UI_splineLocConfidence 1;
BA_ "GenSigSNA" SG_ 536 UI_splineLocConfidence "0";
BA_ "Confidence" SG_ 536 UI_stopSignStopLineDist 1;
BA_ "GenSigSNA" SG_ 536 UI_stopSignStopLineDist "1023";
BA_ "Confidence" SG_ 536 UI_stopSignStopLineConf 1;
BA_ "GenSigSNA" SG_ 536 UI_stopSignStopLineConf "0";
BA_ "Confidence" SG_ 536 UI_trafficLightStopLineDist 1;
BA_ "GenSigSNA" SG_ 536 UI_trafficLightStopLineDist "1023";
BA_ "Confidence" SG_ 536 UI_trafficLightStopLineConf 1;
BA_ "GenSigSNA" SG_ 536 UI_trafficLightStopLineConf "0";
BA_ "Confidence" SG_ 536 UI_baseMapSpeedLimitMPS 1;
BA_ "GenSigSNA" SG_ 536 UI_baseMapSpeedLimitMPS "255";
BA_ "Confidence" SG_ 536 UI_bottomQrtlFleetSpeedMPS 1;
BA_ "GenSigSNA" SG_ 536 UI_bottomQrtlFleetSpeedMPS "255";
BA_ "Confidence" SG_ 536 UI_topQrtlFleetSpeedMPS 1;
BA_ "GenSigSNA" SG_ 536 UI_topQrtlFleetSpeedMPS "255";
BA_ "Confidence" SG_ 536 UI_meanFleetSplineSpeedMPS 1;
BA_ "GenSigSNA" SG_ 536 UI_meanFleetSplineSpeedMPS "255";
BA_ "Confidence" SG_ 536 UI_medianFleetSpeedMPS 1;
BA_ "GenSigSNA" SG_ 536 UI_medianFleetSpeedMPS "255";
BA_ "Confidence" SG_ 536 UI_meanFleetSplineAccelMPS2 1;
BA_ "GenSigSNA" SG_ 536 UI_meanFleetSplineAccelMPS2 "255";
BA_ "Confidence" SG_ 536 UI_rampType 1;
BA_ "GenSigSNA" SG_ 536 UI_rampType "0";
BA_ "Confidence" SG_ 536 UI_valhallaRamp 1;
BA_ "GenSigSNA" SG_ 536 UI_valhallaRamp "0";
BA_ "Confidence" SG_ 536 UI_currSplineIdFull 1;
BA_ "GenSigSNA" SG_ 536 UI_currSplineIdFull "0";
BA_ "Confidence" SG_ 645 UI_driverProfileRecallIndex 1;
BA_ "GenSigSNA" SG_ 645 UI_driverProfileRecallIndex "0";
BA_ "Confidence" SG_ 645 UI_driverProfileRecallStop 0;
BA_ "Confidence" SG_ 645 UI_frontSeatRecallActive 0;
BA_ "Confidence" SG_ 645 UI_frontSeatTrackPos 1;
BA_ "Confidence" SG_ 645 UI_frontSeatBackPos 1;
BA_ "Confidence" SG_ 645 UI_frontSeatLiftPos 1;
BA_ "Confidence" SG_ 645 UI_frontSeatTiltPos 1;
BA_ "Confidence" SG_ 645 UI_steeringColumnUpDownPos 1;
BA_ "Confidence" SG_ 645 UI_steeringColumnInOutPos 1;
BA_ "Confidence" SG_ 645 UI_leftMirrorTiltXPosition 0;
BA_ "Confidence" SG_ 645 UI_leftMirrorTiltYPosition 0;
BA_ "Confidence" SG_ 645 UI_rightMirrorTiltXPosition 1;
BA_ "Confidence" SG_ 645 UI_rightMirrorTiltYPosition 1;
BA_ "Confidence" SG_ 645 UI_customMirrorDipPositionsSet 0;
BA_ "Confidence" SG_ 645 UI_leftMirrorDipXPosition 0;
BA_ "Confidence" SG_ 645 UI_leftMirrorDipYPosition 0;
BA_ "Confidence" SG_ 645 UI_rightMirrorDipXPosition 1;
BA_ "Confidence" SG_ 645 UI_rightMirrorDipYPosition 1;
BA_ "Confidence" SG_ 645 UI_modifyMirrorDipRequest 0;
BA_ "Confidence" SG_ 647 UI_driverProfileLinkedKeySHA1 1;
BA_ "GenSigSNA" SG_ 647 UI_driverProfileLinkedKeySHA1 "4294967295";
BA_ "Confidence" SG_ 647 UI_driverProfileIndex 0;
BA_ "Confidence" SG_ 647 UI_driverProfileSelectionType 0;
BA_ "Confidence" SG_ 647 UI_driverProfilePositionAdjusted 0;
BA_ "Confidence" SG_ 647 UI_activeKeyRequested 0;
BA_ "Confidence" SG_ 984 UI_elevation 1;
BA_ "GenSigSNA" SG_ 984 UI_elevation "8191";
BA_ "Confidence" SG_ 984 UI_navElevation 1;
BA_ "GenSigSNA" SG_ 984 UI_navElevation "8191";
BA_ "Confidence" SG_ 1279 UI_energyConsumptionInfoIndex 1;
BA_ "Confidence" SG_ 1279 UI_energyLossTotal_epa 0;
BA_ "Confidence" SG_ 1279 UI_energyLossDriving_epa 0;
BA_ "Confidence" SG_ 1279 UI_energyLossClimate_epa 0;
BA_ "Confidence" SG_ 1279 UI_energyLossBattCond_epa 0;
BA_ "Confidence" SG_ 1279 UI_energyLossElevation_epa 0;
BA_ "Confidence" SG_ 1279 UI_energyLossAcc_epa 0;
BA_ "Confidence" SG_ 1279 UI_energyLossTotalSinceCharge_ep 0;
BA_ "SystemSignalLongSymbol" SG_ 1279 UI_energyLossTotalSinceCharge_ep "UI_energyLossTotalSinceCharge_epa";
BA_ "Confidence" SG_ 1279 UI_energyLossDrivingSinceCharge_ 0;
BA_ "SystemSignalLongSymbol" SG_ 1279 UI_energyLossDrivingSinceCharge_ "UI_energyLossDrivingSinceCharge_epa";
BA_ "Confidence" SG_ 1279 UI_energyLossClimateSinceCharge_ 0;
BA_ "SystemSignalLongSymbol" SG_ 1279 UI_energyLossClimateSinceCharge_ "UI_energyLossClimateSinceCharge_epa";
BA_ "Confidence" SG_ 1279 UI_energyLossBattCondSinceCharge 0;
BA_ "SystemSignalLongSymbol" SG_ 1279 UI_energyLossBattCondSinceCharge "UI_energyLossBattCondSinceCharge_epa";
BA_ "Confidence" SG_ 1279 UI_energyLossElevationSinceCharg 0;
BA_ "SystemSignalLongSymbol" SG_ 1279 UI_energyLossElevationSinceCharg "UI_energyLossElevationSinceCharge_epa";
BA_ "Confidence" SG_ 1279 UI_energyLossAccSinceCharge_epa 0;
BA_ "Confidence" SG_ 1279 UI_energyLossTotalSinceTripStart 0;
BA_ "Confidence" SG_ 1279 UI_energyLossDrivingSinceTripSta 0;
BA_ "SystemSignalLongSymbol" SG_ 1279 UI_energyLossDrivingSinceTripSta "UI_energyLossDrivingSinceTripStart";
BA_ "Confidence" SG_ 1279 UI_energyLossClimateSinceTripSta 0;
BA_ "SystemSignalLongSymbol" SG_ 1279 UI_energyLossClimateSinceTripSta "UI_energyLossClimateSinceTripStart";
BA_ "Confidence" SG_ 1279 UI_energyLossBattCondSinceTripSt 0;
BA_ "SystemSignalLongSymbol" SG_ 1279 UI_energyLossBattCondSinceTripSt "UI_energyLossBattCondSinceTripStart";
BA_ "Confidence" SG_ 1279 UI_energyLossElevationSinceTripS 0;
BA_ "SystemSignalLongSymbol" SG_ 1279 UI_energyLossElevationSinceTripS "UI_energyLossElevationSinceTripStart";
BA_ "Confidence" SG_ 1279 UI_energyLossAccSinceTripStart 0;
BA_ "Confidence" SG_ 1279 UI_energyDeltaTotal_epa 0;
BA_ "Confidence" SG_ 1279 UI_energyDeltaDriving_epa 0;
BA_ "Confidence" SG_ 1279 UI_energyDeltaClimate_epa 0;
BA_ "Confidence" SG_ 1279 UI_energyDeltaBattCond_epa 0;
BA_ "Confidence" SG_ 1279 UI_energyDeltaElevation_epa 0;
BA_ "Confidence" SG_ 1279 UI_energyDeltaAcc_epa 0;
BA_ "Confidence" SG_ 1279 UI_uiDeltaOffsetTotal_epa 0;
BA_ "Confidence" SG_ 1279 UI_uiDeltaOffsetDriving_epa 0;
BA_ "Confidence" SG_ 1279 UI_uiDeltaOffsetClimate_epa 0;
BA_ "Confidence" SG_ 1279 UI_uiDeltaOffsetBattCond_epa 0;
BA_ "Confidence" SG_ 1279 UI_uiDeltaOffsetElevation_epa 0;
BA_ "Confidence" SG_ 1279 UI_uiDeltaOffsetAcc_epa 0;
BA_ "Confidence" SG_ 1279 UI_rawToUiEnergyRatio_epa 0;
BA_ "Confidence" SG_ 1279 UI_driveDistance_epa 0;
BA_ "Confidence" SG_ 1279 UI_energyDeltaTotalSinceCharge_e 0;
BA_ "SystemSignalLongSymbol" SG_ 1279 UI_energyDeltaTotalSinceCharge_e "UI_energyDeltaTotalSinceCharge_epa";
BA_ "Confidence" SG_ 1279 UI_energyDeltaDrivingSinceCharge 0;
BA_ "SystemSignalLongSymbol" SG_ 1279 UI_energyDeltaDrivingSinceCharge "UI_energyDeltaDrivingSinceCharge_epa";
BA_ "Confidence" SG_ 1279 UI_energyDeltaClimateSinceCharge 0;
BA_ "SystemSignalLongSymbol" SG_ 1279 UI_energyDeltaClimateSinceCharge "UI_energyDeltaClimateSinceCharge_epa";
BA_ "Confidence" SG_ 1279 UI_energyDeltaBattCondSinceCharg 0;
BA_ "SystemSignalLongSymbol" SG_ 1279 UI_energyDeltaBattCondSinceCharg "UI_energyDeltaBattCondSinceCharge_epa";
BA_ "Confidence" SG_ 1279 UI_energyDeltaElevationSinceChar 0;
BA_ "SystemSignalLongSymbol" SG_ 1279 UI_energyDeltaElevationSinceChar "UI_energyDeltaElevationSinceCharge_epa";
BA_ "Confidence" SG_ 1279 UI_energyDeltaAccSinceCharge_epa 0;
BA_ "Confidence" SG_ 1279 UI_uiDeltaOffsetTotalSinceCharge 0;
BA_ "SystemSignalLongSymbol" SG_ 1279 UI_uiDeltaOffsetTotalSinceCharge "UI_uiDeltaOffsetTotalSinceCharge_epa";
BA_ "Confidence" SG_ 1279 UI_uiDeltaOffsetDrivingSinceChar 0;
BA_ "SystemSignalLongSymbol" SG_ 1279 UI_uiDeltaOffsetDrivingSinceChar "UI_uiDeltaOffsetDrivingSinceCharge_epa";
BA_ "Confidence" SG_ 1279 UI_uiDeltaOffsetClimateSinceChar 0;
BA_ "SystemSignalLongSymbol" SG_ 1279 UI_uiDeltaOffsetClimateSinceChar "UI_uiDeltaOffsetClimateSinceCharge_epa";
BA_ "Confidence" SG_ 1279 UI_uiDeltaOffsetBattCondSinceCha 0;
BA_ "SystemSignalLongSymbol" SG_ 1279 UI_uiDeltaOffsetBattCondSinceCha "UI_uiDeltaOffsetBattCondSinceCharge_epa";
BA_ "Confidence" SG_ 1279 UI_uiDeltaOffsetElevationSinceCh 0;
BA_ "SystemSignalLongSymbol" SG_ 1279 UI_uiDeltaOffsetElevationSinceCh "UI_uiDeltaOffsetElevationSinceCharge_epa";
BA_ "Confidence" SG_ 1279 UI_uiDeltaOffsetAccSinceCharge_e 0;
BA_ "SystemSignalLongSymbol" SG_ 1279 UI_uiDeltaOffsetAccSinceCharge_e "UI_uiDeltaOffsetAccSinceCharge_epa";
BA_ "Confidence" SG_ 1279 UI_rawToUiEnergyRatioSinceCharge 0;
BA_ "SystemSignalLongSymbol" SG_ 1279 UI_rawToUiEnergyRatioSinceCharge "UI_rawToUiEnergyRatioSinceCharge_epa";
BA_ "Confidence" SG_ 1279 UI_driveDistanceSinceCharge_epa 0;
BA_ "Confidence" SG_ 1279 UI_energyDeltaTotalSinceTripStar 0;
BA_ "SystemSignalLongSymbol" SG_ 1279 UI_energyDeltaTotalSinceTripStar "UI_energyDeltaTotalSinceTripStart";
BA_ "Confidence" SG_ 1279 UI_energyDeltaDrivingSinceTripSt 0;
BA_ "SystemSignalLongSymbol" SG_ 1279 UI_energyDeltaDrivingSinceTripSt "UI_energyDeltaDrivingSinceTripStart";
BA_ "Confidence" SG_ 1279 UI_energyDeltaClimateSinceTripSt 0;
BA_ "SystemSignalLongSymbol" SG_ 1279 UI_energyDeltaClimateSinceTripSt "UI_energyDeltaClimateSinceTripStart";
BA_ "Confidence" SG_ 1279 UI_energyDeltaBattCondSinceTripS 0;
BA_ "SystemSignalLongSymbol" SG_ 1279 UI_energyDeltaBattCondSinceTripS "UI_energyDeltaBattCondSinceTripStart";
BA_ "Confidence" SG_ 1279 UI_energyDeltaElevationSinceTrip 0;
BA_ "SystemSignalLongSymbol" SG_ 1279 UI_energyDeltaElevationSinceTrip "UI_energyDeltaElevationSinceTripStart";
BA_ "Confidence" SG_ 1279 UI_energyDeltaAccSinceTripStart 0;
BA_ "Confidence" SG_ 1279 UI_uiDeltaOffsetTotalSinceTripSt 0;
BA_ "SystemSignalLongSymbol" SG_ 1279 UI_uiDeltaOffsetTotalSinceTripSt "UI_uiDeltaOffsetTotalSinceTripStart";
BA_ "Confidence" SG_ 1279 UI_uiDeltaOffsetDrivingSinceTrip 0;
BA_ "SystemSignalLongSymbol" SG_ 1279 UI_uiDeltaOffsetDrivingSinceTrip "UI_uiDeltaOffsetDrivingSinceTripStart";
BA_ "Confidence" SG_ 1279 UI_uiDeltaOffsetClimateSinceTrip 0;
BA_ "SystemSignalLongSymbol" SG_ 1279 UI_uiDeltaOffsetClimateSinceTrip "UI_uiDeltaOffsetClimateSinceTripStart";
BA_ "Confidence" SG_ 1279 UI_uiDeltaOffsetBattCondSinceTri 0;
BA_ "SystemSignalLongSymbol" SG_ 1279 UI_uiDeltaOffsetBattCondSinceTri "UI_uiDeltaOffsetBattCondSinceTripStart";
BA_ "Confidence" SG_ 1279 UI_uiDeltaOffsetElevationSinceTr 0;
BA_ "SystemSignalLongSymbol" SG_ 1279 UI_uiDeltaOffsetElevationSinceTr "UI_uiDeltaOffsetElevationSinceTripStart";
BA_ "Confidence" SG_ 1279 UI_uiDeltaOffsetAccSinceTripStar 0;
BA_ "SystemSignalLongSymbol" SG_ 1279 UI_uiDeltaOffsetAccSinceTripStar "UI_uiDeltaOffsetAccSinceTripStart";
BA_ "Confidence" SG_ 1279 UI_rawToUiEnergyRatioSinceTripSt 0;
BA_ "SystemSignalLongSymbol" SG_ 1279 UI_rawToUiEnergyRatioSinceTripSt "UI_rawToUiEnergyRatioSinceTripStart";
BA_ "Confidence" SG_ 1279 UI_driveDistanceSinceTripStart 0;
BA_ "Confidence" SG_ 1279 UI_trailerMass 0;
BA_ "Confidence" SG_ 1139 UI_nmKeepAwakeReason 1;
BA_ "GenSigSNA" SG_ 1139 UI_nmKeepAwakeReason "0";
BA_ "Confidence" SG_ 1139 UI_wakeupTime 0;
BA_ "Confidence" SG_ 985 UI_gpsHDOP 1;
BA_ "Confidence" SG_ 985 UI_gpsVehicleHeading 1;
BA_ "Confidence" SG_ 985 UI_gpsVehicleSpeed 1;
BA_ "Confidence" SG_ 985 UI_userSpeedOffset 1;
BA_ "Confidence" SG_ 985 UI_mapSpeedLimitUnits 0;
BA_ "Confidence" SG_ 985 UI_userSpeedOffsetUnits 1;
BA_ "Confidence" SG_ 985 UI_mppSpeedLimit 0;
BA_ "Confidence" SG_ 985 UI_gpsNmeaMIA 0;
BA_ "Confidence" SG_ 985 UI_gpsAntennaDisconnected 0;
BA_ "Confidence" SG_ 985 UI_conditionalLimitActive 0;
BA_ "Confidence" SG_ 985 UI_conditionalSpeedLimit 0;
BA_ "GenSigSNA" SG_ 985 UI_conditionalSpeedLimit "31";
BA_ "Confidence" SG_ 755 UI_hvacReqTempSetpointLeft 0;
BA_ "Confidence" SG_ 755 UI_hvacReqAutoBlowerLevel 0;
BA_ "Confidence" SG_ 755 UI_hvacReqTempSetpointRight 0;
BA_ "Confidence" SG_ 755 UI_hvacReqAirDistributionMode 0;
BA_ "Confidence" SG_ 755 UI_hvacReqBlowerSegment 0;
BA_ "Confidence" SG_ 755 UI_hvacReqRecirc 0;
BA_ "Confidence" SG_ 755 UI_hvacReqACDisable 0;
BA_ "Confidence" SG_ 755 UI_hvacDefogState 0;
BA_ "Confidence" SG_ 755 UI_hvacReqUserPowerState 0;
BA_ "Confidence" SG_ 755 UI_hvacReqSecondRowState 0;
BA_ "Confidence" SG_ 755 UI_hvacReqKeepClimateOn 0;
BA_ "Confidence" SG_ 755 UI_hvacReqBioWeaponDefMode 0;
BA_ "SystemSignalLongSymbol" SG_ 755 UI_hvacPhoneCallAirFlowAdjustEna "UI_hvacPhoneCallAirFlowAdjustEnabled";
BA_ "SystemSignalLongSymbol" SG_ 755 UI_enableHvacWeatherDataBasedHum "UI_enableHvacWeatherDataBasedHumidityControls";
BA_ "Confidence" SG_ 755 UI_hvacReqTempSetpointCOP 0;
BA_ "Confidence" SG_ 755 UI_hvacClimateNudgeStatus 1;
BA_ "Confidence" SG_ 989 UI_latitudeOffset 1;
BA_ "Confidence" SG_ 989 UI_longitudeOffset 1;
BA_ "Confidence" SG_ 79 UI_latitude 1;
BA_ "Confidence" SG_ 79 UI_longitude 1;
BA_ "Confidence" SG_ 79 UI_gpsAccuracy 1;
BA_ "GenSigSNA" SG_ 79 UI_gpsAccuracy "127";
BA_ "Confidence" SG_ 1011 UI_odometer 0;
BA_ "GenSigSNA" SG_ 1011 UI_odometer "16777215";
BA_ "Confidence" SG_ 443 UI_usbFrontHubPowerStateRequest 0;
BA_ "GenSigSNA" SG_ 443 UI_usbFrontHubPowerStateRequest "0";
BA_ "Confidence" SG_ 987 UI_phoneLatitude 1;
BA_ "Confidence" SG_ 987 UI_phoneLongitude 1;
BA_ "Confidence" SG_ 987 UI_phoneGpsAccuracy 1;
BA_ "GenSigSNA" SG_ 987 UI_phoneGpsAccuracy "127";
BA_ "Confidence" SG_ 955 UI_powerExpected 1;
BA_ "Confidence" SG_ 955 UI_powerIdeal 1;
BA_ "Confidence" SG_ 827 UI_idlePowerConsumption 0;
BA_ "Confidence" SG_ 827 UI_chargeTimeUntilTerminationPct 0;
BA_ "GenSigSNA" SG_ 827 UI_chargeTimeUntilTerminationPct "2047";
BA_ "Confidence" SG_ 827 UI_chargeTimeUntilReadyToDepart 0;
BA_ "GenSigSNA" SG_ 827 UI_chargeTimeUntilReadyToDepart "2047";
BA_ "Confidence" SG_ 629 UI_powerRationalityConfigIndex 1;
BA_ "Confidence" SG_ 629 UI_vcleftCfgRationalityThreshold 1;
BA_ "GenSigSNA" SG_ 629 UI_vcleftCfgRationalityThreshold "0";
BA_ "SystemSignalLongSymbol" SG_ 629 UI_vcleftCfgRationalityThreshold "UI_vcleftCfgRationalityThreshold0";
BA_ "Confidence" SG_ 629 UI_vcleftCfgRationalityTime0 1;
BA_ "GenSigSNA" SG_ 629 UI_vcleftCfgRationalityTime0 "0";
BA_ "Confidence" SG_ 629 UI_vcleftCfgRationalityThre_0001 1;
BA_ "GenSigSNA" SG_ 629 UI_vcleftCfgRationalityThre_0001 "0";
BA_ "SystemSignalLongSymbol" SG_ 629 UI_vcleftCfgRationalityThre_0001 "UI_vcleftCfgRationalityThreshold1";
BA_ "Confidence" SG_ 629 UI_vcleftCfgRationalityTime1 1;
BA_ "GenSigSNA" SG_ 629 UI_vcleftCfgRationalityTime1 "0";
BA_ "Confidence" SG_ 629 UI_vcleftCfgRationalityStaticA 1;
BA_ "GenSigSNA" SG_ 629 UI_vcleftCfgRationalityStaticA "65535";
BA_ "Confidence" SG_ 629 UI_vcleftCfgRationalityStaticB 1;
BA_ "GenSigSNA" SG_ 629 UI_vcleftCfgRationalityStaticB "32768";
BA_ "Confidence" SG_ 629 UI_vcleftCfgRationalityStaticC 1;
BA_ "GenSigSNA" SG_ 629 UI_vcleftCfgRationalityStaticC "32768";
BA_ "Confidence" SG_ 629 UI_vcleftCfgRationalityDynamicA 1;
BA_ "GenSigSNA" SG_ 629 UI_vcleftCfgRationalityDynamicA "65535";
BA_ "Confidence" SG_ 629 UI_vcleftCfgRationalityDynamicB 1;
BA_ "GenSigSNA" SG_ 629 UI_vcleftCfgRationalityDynamicB "32768";
BA_ "Confidence" SG_ 629 UI_vcleftCfgRationalityDynamicC 1;
BA_ "GenSigSNA" SG_ 629 UI_vcleftCfgRationalityDynamicC "32768";
BA_ "Confidence" SG_ 629 UI_vcrightCfgRationalityThreshol 1;
BA_ "GenSigSNA" SG_ 629 UI_vcrightCfgRationalityThreshol "0";
BA_ "SystemSignalLongSymbol" SG_ 629 UI_vcrightCfgRationalityThreshol "UI_vcrightCfgRationalityThreshold0";
BA_ "Confidence" SG_ 629 UI_vcrightCfgRationalityTime0 1;
BA_ "GenSigSNA" SG_ 629 UI_vcrightCfgRationalityTime0 "0";
BA_ "Confidence" SG_ 629 UI_vcrightCfgRationalityThr_0001 1;
BA_ "GenSigSNA" SG_ 629 UI_vcrightCfgRationalityThr_0001 "0";
BA_ "SystemSignalLongSymbol" SG_ 629 UI_vcrightCfgRationalityThr_0001 "UI_vcrightCfgRationalityThreshold1";
BA_ "Confidence" SG_ 629 UI_vcrightCfgRationalityTime1 1;
BA_ "GenSigSNA" SG_ 629 UI_vcrightCfgRationalityTime1 "0";
BA_ "Confidence" SG_ 629 UI_vcrightCfgRationalityStaticA 1;
BA_ "GenSigSNA" SG_ 629 UI_vcrightCfgRationalityStaticA "65535";
BA_ "Confidence" SG_ 629 UI_vcrightCfgRationalityStaticB 1;
BA_ "GenSigSNA" SG_ 629 UI_vcrightCfgRationalityStaticB "32768";
BA_ "Confidence" SG_ 629 UI_vcrightCfgRationalityStaticC 1;
BA_ "GenSigSNA" SG_ 629 UI_vcrightCfgRationalityStaticC "32768";
BA_ "Confidence" SG_ 629 UI_vcrightCfgRationalityDynamicA 1;
BA_ "GenSigSNA" SG_ 629 UI_vcrightCfgRationalityDynamicA "65535";
BA_ "Confidence" SG_ 629 UI_vcrightCfgRationalityDynamicB 1;
BA_ "GenSigSNA" SG_ 629 UI_vcrightCfgRationalityDynamicB "32768";
BA_ "Confidence" SG_ 629 UI_vcrightCfgRationalityDynamicC 1;
BA_ "GenSigSNA" SG_ 629 UI_vcrightCfgRationalityDynamicC "32768";
BA_ "Confidence" SG_ 629 UI_vcleftCfgCutoffThreshold0 1;
BA_ "GenSigSNA" SG_ 629 UI_vcleftCfgCutoffThreshold0 "0";
BA_ "Confidence" SG_ 629 UI_vcleftCfgCutoffTime0 1;
BA_ "GenSigSNA" SG_ 629 UI_vcleftCfgCutoffTime0 "0";
BA_ "Confidence" SG_ 629 UI_vcleftCfgCutoffThreshold1 1;
BA_ "GenSigSNA" SG_ 629 UI_vcleftCfgCutoffThreshold1 "0";
BA_ "Confidence" SG_ 629 UI_vcleftCfgCutoffTime1 1;
BA_ "GenSigSNA" SG_ 629 UI_vcleftCfgCutoffTime1 "0";
BA_ "Confidence" SG_ 629 UI_vcleftCfgCutoffStaticA 1;
BA_ "GenSigSNA" SG_ 629 UI_vcleftCfgCutoffStaticA "65535";
BA_ "Confidence" SG_ 629 UI_vcleftCfgCutoffStaticB 1;
BA_ "GenSigSNA" SG_ 629 UI_vcleftCfgCutoffStaticB "32768";
BA_ "Confidence" SG_ 629 UI_vcleftCfgCutoffStaticC 1;
BA_ "GenSigSNA" SG_ 629 UI_vcleftCfgCutoffStaticC "32768";
BA_ "Confidence" SG_ 629 UI_vcleftCfgCutoffDynamicA 1;
BA_ "GenSigSNA" SG_ 629 UI_vcleftCfgCutoffDynamicA "65535";
BA_ "Confidence" SG_ 629 UI_vcleftCfgCutoffDynamicB 1;
BA_ "GenSigSNA" SG_ 629 UI_vcleftCfgCutoffDynamicB "32768";
BA_ "Confidence" SG_ 629 UI_vcleftCfgCutoffDynamicC 1;
BA_ "GenSigSNA" SG_ 629 UI_vcleftCfgCutoffDynamicC "32768";
BA_ "Confidence" SG_ 629 UI_vcrightCfgCutoffThreshold0 1;
BA_ "GenSigSNA" SG_ 629 UI_vcrightCfgCutoffThreshold0 "0";
BA_ "Confidence" SG_ 629 UI_vcrightCfgCutoffTime0 1;
BA_ "GenSigSNA" SG_ 629 UI_vcrightCfgCutoffTime0 "0";
BA_ "Confidence" SG_ 629 UI_vcrightCfgCutoffThreshold1 1;
BA_ "GenSigSNA" SG_ 629 UI_vcrightCfgCutoffThreshold1 "0";
BA_ "Confidence" SG_ 629 UI_vcrightCfgCutoffTime1 1;
BA_ "GenSigSNA" SG_ 629 UI_vcrightCfgCutoffTime1 "0";
BA_ "Confidence" SG_ 629 UI_vcrightCfgCutoffStaticA 1;
BA_ "GenSigSNA" SG_ 629 UI_vcrightCfgCutoffStaticA "65535";
BA_ "Confidence" SG_ 629 UI_vcrightCfgCutoffStaticB 1;
BA_ "GenSigSNA" SG_ 629 UI_vcrightCfgCutoffStaticB "32768";
BA_ "Confidence" SG_ 629 UI_vcrightCfgCutoffStaticC 1;
BA_ "GenSigSNA" SG_ 629 UI_vcrightCfgCutoffStaticC "32768";
BA_ "Confidence" SG_ 629 UI_vcrightCfgCutoffDynamicA 1;
BA_ "GenSigSNA" SG_ 629 UI_vcrightCfgCutoffDynamicA "65535";
BA_ "Confidence" SG_ 629 UI_vcrightCfgCutoffDynamicB 1;
BA_ "GenSigSNA" SG_ 629 UI_vcrightCfgCutoffDynamicB "32768";
BA_ "Confidence" SG_ 629 UI_vcrightCfgCutoffDynamicC 1;
BA_ "GenSigSNA" SG_ 629 UI_vcrightCfgCutoffDynamicC "32768";
BA_ "Confidence" SG_ 820 UI_systemPowerLimit 1;
BA_ "GenSigSNA" SG_ 820 UI_systemPowerLimit "31";
BA_ "Confidence" SG_ 820 UI_pedalMap 0;
BA_ "Confidence" SG_ 820 UI_enableRegenBackfill 0;
BA_ "Confidence" SG_ 820 UI_systemTorqueLimit 1;
BA_ "GenSigSNA" SG_ 820 UI_systemTorqueLimit "63";
BA_ "Confidence" SG_ 820 UI_closureConfirmed 1;
BA_ "Confidence" SG_ 820 UI_regenTorqueMax 0;
BA_ "Confidence" SG_ 820 UI_limitMode 0;
BA_ "SystemSignalLongSymbol" SG_ 820 UI_factoryCustomerDrivingModeReq "UI_factoryCustomerDrivingModeRequest";
BA_ "Confidence" SG_ 820 UI_motorOnMode 0;
BA_ "Confidence" SG_ 820 UI_wasteMode 1;
BA_ "Confidence" SG_ 820 UI_wasteModeRegenLimit 1;
BA_ "Confidence" SG_ 820 UI_stoppingMode 1;
BA_ "Confidence" SG_ 820 UI_speedLimit 1;
BA_ "GenSigSNA" SG_ 820 UI_speedLimit "511";
BA_ "Confidence" SG_ 820 UI_enableSmartShift 1;
BA_ "Confidence" SG_ 820 UI_navVehParallelToRdCanContinue 1;
BA_ "GenSigSNA" SG_ 820 UI_navVehParallelToRdCanContinue "0";
BA_ "Confidence" SG_ 698 UI_radarTargetDx 1;
BA_ "Confidence" SG_ 698 UI_radarTargetDxEnd 1;
BA_ "Confidence" SG_ 826 UI_ratedRange 0;
BA_ "Confidence" SG_ 826 UI_soe 0;
BA_ "Confidence" SG_ 826 UI_uSoe 0;
BA_ "Confidence" SG_ 826 UI_softPackLimitPct 1;
BA_ "Confidence" SG_ 826 UI_targetFullPackEnergy 1;
BA_ "Confidence" SG_ 632 UI_roadCurvC0 1;
BA_ "Confidence" SG_ 632 UI_roadCurvC1 1;
BA_ "Confidence" SG_ 632 UI_roadCurvC2 1;
BA_ "Confidence" SG_ 632 UI_roadCurvC3 1;
BA_ "Confidence" SG_ 632 UI_roadCurvRange 1;
BA_ "Confidence" SG_ 632 UI_roadCurvHealth 1;
BA_ "Confidence" SG_ 723 UI_solarAzimuthAngle 1;
BA_ "GenSigSNA" SG_ 723 UI_solarAzimuthAngle "32768";
BA_ "Confidence" SG_ 723 UI_solarAzimuthAngleCarRef 1;
BA_ "GenSigSNA" SG_ 723 UI_solarAzimuthAngleCarRef "255";
BA_ "Confidence" SG_ 723 UI_isSunUp 0;
BA_ "GenSigSNA" SG_ 723 UI_isSunUp "3";
BA_ "Confidence" SG_ 723 UI_solarElevationAngle 0;
BA_ "GenSigSNA" SG_ 723 UI_solarElevationAngle "127";
BA_ "Confidence" SG_ 723 UI_screenPCBTemperature 0;
BA_ "Confidence" SG_ 723 UI_minsToSunset 0;
BA_ "Confidence" SG_ 723 UI_minsToSunrise 0;
BA_ "Confidence" SG_ 563 UI_gearRequest 0;
BA_ "GenSigSNA" SG_ 563 UI_gearRequest "0";
BA_ "Confidence" SG_ 563 UI_autopilotRequest 1;
BA_ "Confidence" SG_ 563 UI_fullScreenMode 1;
BA_ "Confidence" SG_ 563 UI_gearStripShowing 1;
BA_ "Confidence" SG_ 563 UI_gearStripLocation 1;
BA_ "Confidence" SG_ 563 UI_gearStripForceShow 1;
BA_ "Confidence" SG_ 563 UI_autoParkAvailable 1;
BA_ "Confidence" SG_ 563 UI_gearStripSuppressActive 1;
BA_ "Confidence" SG_ 563 UI_gearNeutralPressed 1;
BA_ "Confidence" SG_ 699 UI_centerDisplayRunning 0;
BA_ "Confidence" SG_ 699 UI_centerDisplaySM 1;
BA_ "Confidence" SG_ 699 UI_centerDisplayPowerOn 0;
BA_ "Confidence" SG_ 851 UI_touchActive 0;
BA_ "Confidence" SG_ 851 UI_audioActive 0;
BA_ "Confidence" SG_ 851 UI_cellActive 0;
BA_ "Confidence" SG_ 851 UI_displayReady 0;
BA_ "Confidence" SG_ 851 UI_displayOn 0;
BA_ "Confidence" SG_ 851 UI_wifiActive 0;
BA_ "Confidence" SG_ 851 UI_wifiConnected 0;
BA_ "Confidence" SG_ 851 UI_readyForDrive 0;
BA_ "Confidence" SG_ 851 UI_cellConnected 0;
BA_ "Confidence" SG_ 851 UI_vpnActive 0;
BA_ "Confidence" SG_ 851 UI_autopilotTrial 1;
BA_ "Confidence" SG_ 851 UI_factoryReset 0;
BA_ "GenSigSNA" SG_ 851 UI_factoryReset "0";
BA_ "Confidence" SG_ 851 UI_gpsActive 0;
BA_ "Confidence" SG_ 851 UI_cellNetworkTechnology 0;
BA_ "GenSigSNA" SG_ 851 UI_cellNetworkTechnology "15";
BA_ "Confidence" SG_ 851 UI_cellReceiverPower 1;
BA_ "Confidence" SG_ 851 UI_falseTouchCounter 0;
BA_ "Confidence" SG_ 851 UI_cellSignalBars 0;
BA_ "GenSigSNA" SG_ 851 UI_cellSignalBars "7";
BA_ "Confidence" SG_ 851 UI_trailerModeTelltale 0;
BA_ "Confidence" SG_ 851 UI_pcbTemperature 0;
BA_ "Confidence" SG_ 851 UI_cpuTemperature 0;
BA_ "Confidence" SG_ 991 UI_userActivity 0;
BA_ "Confidence" SG_ 991 UI_activeTouchPoints 0;
BA_ "Confidence" SG_ 991 UI_linkState 0;
BA_ "Confidence" SG_ 991 UI_sentryModeState 1;
BA_ "GenSigSNA" SG_ 991 UI_sentryModeState "6";
BA_ "Confidence" SG_ 991 UI_autopilotSentryRequest 0;
BA_ "Confidence" SG_ 991 UI_mobileAppConnected 0;
BA_ "Confidence" SG_ 991 UI_autoshiftDRState 0;
BA_ "Confidence" SG_ 991 UI_wifiBtModuleType 0;
BA_ "Confidence" SG_ 991 UI_sohHealthStatus 1;
BA_ "Confidence" SG_ 991 UI_selfParkState 0;
BA_ "GenSigSNA" SG_ 991 UI_selfParkState "255";
BA_ "Confidence" SG_ 991 UI_summonDeviceIndex 0;
BA_ "Confidence" SG_ 988 UI_goalLatitude 1;
BA_ "Confidence" SG_ 988 UI_goalLongitude 1;
BA_ "Confidence" SG_ 988 UI_goalOrientation 1;
BA_ "Confidence" SG_ 663 UI_adaptiveRideRequest 0;
BA_ "Confidence" SG_ 663 UI_suspensionLoweringRequest 1;
BA_ "GenSigSNA" SG_ 663 UI_suspensionLoweringRequest "3";
BA_ "Confidence" SG_ 663 UI_geofenceLevelingRequest 0;
BA_ "GenSigSNA" SG_ 663 UI_geofenceLevelingRequest "5";
BA_ "Confidence" SG_ 663 UI_jackModeToggleRequest 1;
BA_ "Confidence" SG_ 663 UI_adaptiveTuningRequest0 1;
BA_ "Confidence" SG_ 663 UI_adaptiveTuningRequest1 1;
BA_ "Confidence" SG_ 663 UI_roadRoughnessLookahead 1;
BA_ "GenSigSNA" SG_ 663 UI_roadRoughnessLookahead "127";
BA_ "Confidence" SG_ 663 UI_roadRoughnessStart 1;
BA_ "GenSigSNA" SG_ 663 UI_roadRoughnessStart "31";
BA_ "Confidence" SG_ 663 UI_mapVersionUsed 1;
BA_ "GenSigSNA" SG_ 663 UI_mapVersionUsed "255";
BA_ "Confidence" SG_ 663 UI_suspensionLevelRequest 1;
BA_ "Confidence" SG_ 661 UI_systemMonitorIndex 1;
BA_ "Confidence" SG_ 661 UI_SystemMemUsage 0;
BA_ "Confidence" SG_ 661 UI_QtCarMemUsage 0;
BA_ "Confidence" SG_ 661 UI_QtCarCPUUsage 0;
BA_ "Confidence" SG_ 661 UI_SystemCPUUsage 0;
BA_ "Confidence" SG_ 1064 UI_TCR_minRCS 1;
BA_ "Confidence" SG_ 1064 UI_TCR_maxDy 1;
BA_ "Confidence" SG_ 856 UI_TPMSMode 1;
BA_ "Confidence" SG_ 856 UI_TPMSLearnIDMode 1;
BA_ "Confidence" SG_ 856 UI_sizeOfWheelSelect 1;
BA_ "Confidence" SG_ 952 UI_setRCPFront 1;
BA_ "Confidence" SG_ 952 UI_setRCPRear 1;
BA_ "Confidence" SG_ 787 UI_trackModeRequest 0;
BA_ "Confidence" SG_ 787 UI_trackRotationTendency 1;
BA_ "Confidence" SG_ 787 UI_trackStabilityAssist 1;
BA_ "Confidence" SG_ 787 UI_trackPostCooling 1;
BA_ "Confidence" SG_ 787 UI_trackCmpOverclock 1;
BA_ "Confidence" SG_ 787 UI_trackModeBrakeTemps 1;
BA_ "Confidence" SG_ 787 UI_trackDrivePowerAvailability 0;
BA_ "Confidence" SG_ 130 UI_tripPlanningActive 0;
BA_ "Confidence" SG_ 130 UI_navToSupercharger 0;
BA_ "Confidence" SG_ 130 UI_navFastchargerType 0;
BA_ "Confidence" SG_ 130 UI_battPreconditionOnNavState 0;
BA_ "Confidence" SG_ 130 UI_requestActiveBatteryHeating 0;
BA_ "Confidence" SG_ 130 UI_battPreconditionOnNavPowerReq 0;
BA_ "GenSigSNA" SG_ 130 UI_battPreconditionOnNavPowerReq "127";
BA_ "Confidence" SG_ 130 UI_battPreconditionOnNavTargetT 0;
BA_ "GenSigSNA" SG_ 130 UI_battPreconditionOnNavTargetT "255";
BA_ "Confidence" SG_ 130 UI_ambientTempAtDestination 1;
BA_ "GenSigSNA" SG_ 130 UI_ambientTempAtDestination "128";
BA_ "Confidence" SG_ 130 UI_energyAtDestination 0;
BA_ "GenSigSNA" SG_ 130 UI_energyAtDestination "32768";
BA_ "Confidence" SG_ 139 UI_maxSpeedToReachDestination 0;
BA_ "GenSigSNA" SG_ 139 UI_maxSpeedToReachDestination "65535";
BA_ "Confidence" SG_ 139 UI_remainingWeightedRMSSpeed 1;
BA_ "GenSigSNA" SG_ 139 UI_remainingWeightedRMSSpeed "65535";
BA_ "Confidence" SG_ 139 UI_timeToDestination 0;
BA_ "GenSigSNA" SG_ 139 UI_timeToDestination "65535";
BA_ "Confidence" SG_ 1173 UI_predictedEnergy 0;
BA_ "GenSigSNA" SG_ 1173 UI_predictedEnergy "32768";
BA_ "Confidence" SG_ 1173 UI_predictedEnergyLearned 1;
BA_ "GenSigSNA" SG_ 1173 UI_predictedEnergyLearned "32768";
BA_ "Confidence" SG_ 1173 UI_hindsightEnergy 0;
BA_ "GenSigSNA" SG_ 1173 UI_hindsightEnergy "32768";
BA_ "Confidence" SG_ 1173 UI_hindsightEnergyLearned 1;
BA_ "GenSigSNA" SG_ 1173 UI_hindsightEnergyLearned "32768";
BA_ "Confidence" SG_ 1174 UI_longTermEnergyModelError 1;
BA_ "GenSigSNA" SG_ 1174 UI_longTermEnergyModelError "128";
BA_ "Confidence" SG_ 1174 UI_longTermRmsSpeedRatio 1;
BA_ "GenSigSNA" SG_ 1174 UI_longTermRmsSpeedRatio "255";
BA_ "Confidence" SG_ 1174 UI_gradeCorrectedEnergy 1;
BA_ "GenSigSNA" SG_ 1174 UI_gradeCorrectedEnergy "32768";
BA_ "Confidence" SG_ 1174 UI_gradeCorrectedEnergyLearned 1;
BA_ "GenSigSNA" SG_ 1174 UI_gradeCorrectedEnergyLearned "32768";
BA_ "Confidence" SG_ 1175 UI_battPreconditionOnNavTime 1;
BA_ "GenSigSNA" SG_ 1175 UI_battPreconditionOnNavTime "65535";
BA_ "Confidence" SG_ 1175 UI_maxBattPreconditionOnNavTime 1;
BA_ "GenSigSNA" SG_ 1175 UI_maxBattPreconditionOnNavTime "65535";
BA_ "Confidence" SG_ 1175 UI_tripPlanChargingTargetPercent 1;
BA_ "GenSigSNA" SG_ 1175 UI_tripPlanChargingTargetPercent "1023";
BA_ "Confidence" SG_ 1827 UI_ussSensorIdX 1;
VAL_ 1021 UI_autopilotControlIndex 7 "7" 6 "6" 5 "5" 4 "4" 3 "3" 2 "2" 1 "1" 0 "0" ;
VAL_ 1021 UI_hovEnabled 1 "HOV_ON" 0 "HOV_OFF" ;
VAL_ 1021 UI_donDisableAutoWiperDuration 6 "OFF" 5 "120_S" 4 "60_S" 3 "30_S" 2 "15_S" 1 "5_S" 0 "DEFAULT" ;
VAL_ 1021 UI_donDisableOnAutoWiperSpeed 15 "INVALID" 14 "14" 13 "13" 12 "12" 11 "11" 10 "10" 9 "9" 8 "8" 7 "7" 6 "6" 5 "5" 4 "4" 3 "3" 2 "2" 1 "1" 0 "OFF" ;
VAL_ 1021 UI_blindspotMinSpeed 10 "OFF" 9 "45_KPH" 8 "40_KPH" 7 "35_KPH" 6 "30_KPH" 5 "25_KPH" 4 "20_KPH" 3 "15_KPH" 2 "10_KPH" 1 "5_KPH" 0 "DEFAULT" ;
VAL_ 1021 UI_blindspotDistance 5 "OFF" 4 "4_M" 3 "2_M" 2 "1_M" 1 "0P5_M" 0 "DEFAULT" ;
VAL_ 1021 UI_blindspotTTC 7 "OFF" 6 "5_S" 5 "3_S" 4 "4_S" 3 "2_S" 2 "1_S" 1 "0P5_S" 0 "DEFAULT" ;
VAL_ 1021 UI_donStopEndOfRampBuffer 4 "OFF" 3 "45_M" 2 "30_M" 1 "15_M" 0 "DEFAULT" ;
VAL_ 1021 UI_donDisableCutin 1 "ON" 0 "OFF" ;
VAL_ 1021 UI_smartSetSpeedOffsetType 1 "PERCENTAGE_OFFSET" 0 "FIXED_OFFSET" ;
VAL_ 1021 UI_homelinkNearby 1 "NEARBY" 0 "NOT_NEARBY" ;
VAL_ 1021 UI_autosteerActivation 1 "DOUBLE_CLICK" 0 "SINGLE_CLICK" ;
VAL_ 1021 UI_autopilotDrivingProfile 3 "MAD_MAX" 2 "ASSERTIVE" 1 "NORMAL" 0 "CHILL" ;
VAL_ 1021 UI_fsdBetaRequest 1 "FSD_REQUEST_ACTIVE" 0 "FSD_REQUEST_NOT_ACTIVE" ;
VAL_ 1021 UI_selectableCameraRequest 15 "SNA" 13 "REPEATERS_BACKUP" 12 "FASCIA" 11 "GRID_VIEW" 10 "OCTA" 9 "BACKUP" 8 "RIGHT_REPEATER" 7 "RIGHT_PILLAR" 6 "LEFT_REPEATER" 5 "LEFT_PILLAR" 4 "FRONT_NARROW" 3 "FRONT_FISHEYE" 2 "FRONT_MAIN" 1 "SELFIE" 0 "NONE" ;
VAL_ 1021 UI_overrideSleepWithSuspend 1 "ENABLED" 0 "DISABLED" ;
VAL_ 1021 UI_regulatoryLaneAssistLevel 1 "ASSIST" 0 "WARNING" ;
VAL_ 1021 UI_apmv3Branch 5 "DEMO" 4 "EAP" 3 "STAGE2" 2 "DEV" 1 "STAGE" 0 "LIVE" ;
VAL_ 1021 UI_autoTurnSignalMode 1 "UI_AUTO_TURN_SIGNAL_MODE_AUTO_CANCEL" 0 "UI_AUTO_TURN_SIGNAL_MODE_OFF" ;
VAL_ 819 UI_brickVLoggingRequest 1 "TRUE" 0 "FALSE" ;
VAL_ 819 UI_brickBalancingDisabled 1 "TRUE" 0 "FALSE" ;
VAL_ 819 UI_acChargeCurrentLimit 127 "SNA" ;
VAL_ 819 UI_chargePortLatchRequest 2 "UI_LATCH_REQUEST_DISENGAGE" 1 "UI_LATCH_REQUEST_ENGAGE" 0 "UI_LATCH_REQUEST_NONE" ;
VAL_ 819 UI_cpInletHeaterRequest 2 "HEATER_MANUAL_OVERRIDE" 1 "HEATER_AUTO" 0 "HEATER_OFF" ;
VAL_ 659 UI_steeringTuneRequest 2 "STEERING_TUNE_SPORT" 1 "STEERING_TUNE_STANDARD" 0 "STEERING_TUNE_COMFORT" ;
VAL_ 659 UI_tractionControlMode 7 "TC_SLIPPERY_SURFACE_SELECTED" 6 "TC_OFFROAD_ASSIST_SELECTED" 5 "TC_DYNO_MODE_SELECTED" 4 "TC_ROLLS_MODE_SELECTED" 3 "TC_DEV_MODE_2_SELECTED" 2 "TC_DEV_MODE_1_SELECTED" 1 "TC_SLIP_START_SELECTED" 0 "TC_NORMAL_SELECTED" ;
VAL_ 659 UI_parkBrakeRequest 3 "PARK_BRAKE_REQUEST_SNA" 1 "PARK_BRAKE_REQUEST_PRESSED" 0 "PARK_BRAKE_REQUEST_IDLE" ;
VAL_ 659 UI_winchModeRequest 3 "WINCH_MODE_DIALOGUE_OPEN" 2 "WINCH_MODE_EXIT" 1 "WINCH_MODE_ENTER" 0 "WINCH_MODE_IDLE" ;
VAL_ 659 UI_zeroSpeedConfirmed 3 "SNA" 2 "UNUSED" 1 "CONFIRMED" 0 "CANCELED" ;
VAL_ 659 UI_trailerMode 1 "TRAILER_MODE_ON" 0 "TRAILER_MODE_OFF" ;
VAL_ 659 UI_distanceUnits 1 "MILES" 0 "KM" ;
VAL_ 659 UI_accOvertakeEnable 3 "SNA" 1 "ACC_OVERTAKE_ON" 0 "ACC_OVERTAKE_OFF" ;
VAL_ 659 UI_aebEnable 3 "SNA" 1 "AEB_ON" 0 "AEB_OFF" ;
VAL_ 659 UI_aesEnable 3 "SNA" 1 "AES_ON" 0 "AES_OFF" ;
VAL_ 659 UI_ahlbEnable 3 "SNA" 1 "AHLB_ON" 0 "AHLB_OFF" ;
VAL_ 659 UI_autoLaneChangeEnable 3 "SNA" 1 "ON" 0 "OFF" ;
VAL_ 659 UI_autoParkRequest 15 "SNA" 12 "BEGIN_PARKING" 11 "RESUME" 10 "PAUSE" 9 "SEARCH" 8 "COMPLETE" 7 "ABORT" 6 "PARALLEL_PULL_OUT_TO_RIGHT" 5 "PARALLEL_PULL_OUT_TO_LEFT" 4 "PARK_RIGHT_CROSS" 3 "PARK_RIGHT_PARALLEL" 2 "PARK_LEFT_CROSS" 1 "PARK_LEFT_PARALLEL" 0 "NONE" ;
VAL_ 659 UI_bsdEnable 3 "SNA" 1 "BSD_ON" 0 "BSD_OFF" ;
VAL_ 659 UI_fcwEnable 3 "SNA" 1 "FCW_ON" 0 "FCW_OFF" ;
VAL_ 659 UI_fcwSensitivity 3 "SNA" 2 "AEB_SENSITIVITY_LATE" 1 "AEB_SENSITIVITY_AVERAGE" 0 "AEB_SENSITIVITY_EARLY" ;
VAL_ 659 UI_latControlEnable 3 "LATERAL_CONTROL_SNA" 2 "LATERAL_CONTROL_UNAVAILABLE" 1 "LATERAL_CONTROL_ON" 0 "LATERAL_CONTROL_OFF" ;
VAL_ 659 UI_ldwEnable 3 "SNA" 1 "LDW_TRIGGERS_HAPTIC" 0 "NO_HAPTIC" ;
VAL_ 659 UI_pedalSafetyEnable 3 "SNA" 1 "PEDAL_SAFETY_ON" 0 "PEDAL_SAFETY_OFF" ;
VAL_ 659 UI_pedalMap_epas 2 "PERFORMANCE" 1 "SPORT" 0 "CHILL" ;
VAL_ 659 UI_redLightStopSignEnable 3 "SNA" 1 "RLSSW_ON" 0 "RLSSW_OFF" ;
VAL_ 659 UI_selfParkTune 15 "SNA" ;
VAL_ 531 UI_cruiseSpeedCommand 6 "CRUISE_SPEED_SNAP_SPEEDO" 5 "CRUISE_SPEED_SNAP" 4 "CRUISE_SPEED_DEC_LONG" 3 "CRUISE_SPEED_DEC_SHORT" 2 "CRUISE_SPEED_INC_LONG" 1 "CRUISE_SPEED_INC_SHORT" 0 "CRUISE_SPEED_IDLE" ;
VAL_ 1280 UI_debugEcuTarget 21 "PMRE2" 20 "PMRE2L" 19 "PMRE1L" 18 "DIRE2" 17 "DIRE1R" 16 "DIRE1L" 15 "PMRER" 14 "PMREL" 13 "DIRER" 12 "DIREL" 11 "PMR" 10 "PMF" 9 "DIR" 8 "DIF" 7 "VCFRONT" 6 "VCRIGHT" 5 "BMS" 4 "PMS" 3 "PM" 2 "DIS" 1 "DI" ;
VAL_ 2043 UI_debugDampingRequestFLC 255 "SNA" ;
VAL_ 2043 UI_debugDampingRequestFLR 255 "SNA" ;
VAL_ 2043 UI_debugDampingRequestFRC 255 "SNA" ;
VAL_ 2043 UI_debugDampingRequestFRR 255 "SNA" ;
VAL_ 2043 UI_debugDampingRequestRLC 255 "SNA" ;
VAL_ 2043 UI_debugDampingRequestRLR 255 "SNA" ;
VAL_ 2043 UI_debugDampingRequestRRC 255 "SNA" ;
VAL_ 2043 UI_debugDampingRequestRRR 255 "SNA" ;
VAL_ 1096 UI_anonDebugFlag1 1 "ON" 0 "OFF" ;
VAL_ 1096 UI_anonDebugFlag2 1 "ON" 0 "OFF" ;
VAL_ 1096 UI_anonDebugFlag3 1 "ON" 0 "OFF" ;
VAL_ 1096 UI_anonDebugFlag4 1 "ON" 0 "OFF" ;
VAL_ 1016 UI_autopilotControlRequest 1 "NEXT_GEN_CTRL" 0 "LEGACY_LAT_CTRL" ;
VAL_ 1016 UI_curvSpeedAdaptDisable 1 "OFF" 0 "ON" ;
VAL_ 1016 UI_lssLkaEnabled 1 "LKA_ON" 0 "LKA_OFF" ;
VAL_ 1016 UI_lssLdwEnabled 1 "LDW_ON" 0 "LDW_OFF" ;
VAL_ 1016 UI_exceptionListEnable 1 "ON" 0 "OFF" ;
VAL_ 1016 UI_roadCheckDisable 1 "OFF" 0 "ON" ;
VAL_ 1016 UI_driveOnMapsEnable 1 "DOM_ON" 0 "DOM_OFF" ;
VAL_ 1016 UI_handsOnRequirementDisable 1 "OFF" 0 "ON" ;
VAL_ 1016 UI_fuseLanesDisable 1 "OFF" 0 "ON" ;
VAL_ 1016 UI_fuseHPPDisable 1 "OFF" 0 "ON" ;
VAL_ 1016 UI_fuseVehiclesDisable 1 "OFF" 0 "ON" ;
VAL_ 1016 UI_visionSpeedType 3 "OPTIMIZED" 2 "TWO_SECOND" 1 "ONE_SECOND" 0 "DISABLED" ;
VAL_ 1016 UI_curvatureDatabaseOnly 1 "ON" 0 "OFF" ;
VAL_ 1016 UI_lssElkEnabled 1 "ELK_ON" 0 "ELK_OFF" ;
VAL_ 1016 UI_summonExitType 3 "SNA" 2 "TURN_LEFT" 1 "TURN_RIGHT" 0 "STRAIGHT" ;
VAL_ 1016 UI_summonEntryType 3 "SNA" 2 "TURN_LEFT" 1 "TURN_RIGHT" 0 "STRAIGHT" ;
VAL_ 1016 UI_selfParkRequest 15 "SNA" 12 "SMART_SUMMON_NO_OP" 11 "SMART_SUMMON" 10 "AUTO_SUMMON_PRIMED" 9 "AUTO_SUMMON_CANCEL" 8 "AUTO_SUMMON_REVERSE" 7 "AUTO_SUMMON_FORWARD" 6 "RESUME" 5 "PAUSE" 4 "PRIME" 3 "ABORT" 2 "SELF_PARK_REVERSE" 1 "SELF_PARK_FORWARD" 0 "NONE" ;
VAL_ 1016 UI_summonReverseDist 63 "SNA" ;
VAL_ 1016 UI_drivingSide 2 "UNKNOWN" 1 "RIGHT" 0 "LEFT" ;
VAL_ 1016 UI_accFollowDistanceSetting 7 "SNA" 6 "7" 5 "6" 4 "5" 3 "4" 2 "3" 1 "2" 0 "1" ;
VAL_ 1016 UI_followNavRouteEnable 1 "NAV_ROUTE_ON" 0 "NAV_ROUTE_OFF" ;
VAL_ 1016 UI_ulcSpeedConfig 3 "SPEED_BASED_ULC_MAD_MAX" 2 "SPEED_BASED_ULC_AVERAGE" 1 "SPEED_BASED_ULC_MILD" 0 "SPEED_BASED_ULC_DISABLED" ;
VAL_ 1016 UI_ulcBlindSpotConfig 2 "MAD_MAX" 1 "AGGRESSIVE" 0 "STANDARD" ;
VAL_ 1016 UI_smartSummonType 2 "SMART_AUTOPARK" 1 "FIND_ME" 0 "PIN_DROP" ;
VAL_ 1016 UI_source3D 2 "XYZ_PREDICTION" 1 "Z_FROM_PATH_PREDICTION" 0 "Z_FROM_MAP" ;
VAL_ 568 UI_mapSpeedLimitDependency 7 "SNA" 6 "LANE" 5 "SEASON" 4 "TIME" 3 "SNOW" 2 "RAIN" 1 "SCHOOL" 0 "NONE" ;
VAL_ 568 UI_roadClass 6 "CLASS_6_MINOR" 5 "CLASS_5" 4 "CLASS_4" 3 "CLASS_3" 2 "CLASS_2" 1 "CLASS_1_MAJOR" 0 "UNKNOWN_INVALID_SNA" ;
VAL_ 568 UI_mapSpeedUnits 1 "KPH" 0 "MPH" ;
VAL_ 568 UI_mapSpeedLimit 31 "SNA" 30 "UNLIMITED" 29 "LESS_OR_EQ_160" 28 "LESS_OR_EQ_150" 27 "LESS_OR_EQ_140" 26 "LESS_OR_EQ_130" 25 "LESS_OR_EQ_120" 24 "LESS_OR_EQ_115" 23 "LESS_OR_EQ_110" 22 "LESS_OR_EQ_105" 21 "LESS_OR_EQ_100" 20 "LESS_OR_EQ_95" 19 "LESS_OR_EQ_90" 18 "LESS_OR_EQ_85" 17 "LESS_OR_EQ_80" 16 "LESS_OR_EQ_75" 15 "LESS_OR_EQ_70" 14 "LESS_OR_EQ_65" 13 "LESS_OR_EQ_60" 12 "LESS_OR_EQ_55" 11 "LESS_OR_EQ_50" 10 "LESS_OR_EQ_45" 9 "LESS_OR_EQ_40" 8 "LESS_OR_EQ_35" 7 "LESS_OR_EQ_30" 6 "LESS_OR_EQ_25" 5 "LESS_OR_EQ_20" 4 "LESS_OR_EQ_15" 3 "LESS_OR_EQ_10" 2 "LESS_OR_EQ_7" 1 "LESS_OR_EQ_5" 0 "UNKNOWN" ;
VAL_ 568 UI_mapSpeedLimitType 7 "UNKNOWN_SNA" 4 "BUMPS" 3 "DEPENDENT" 2 "ADVISORY" 1 "REGULAR" ;
VAL_ 568 UI_countryCode 1023 "SNA" 0 "UNKNOWN" ;
VAL_ 568 UI_nextBranchDist 31 "SNA" ;
VAL_ 536 UI_roadSign 255 "SNA" 5 "SPLINE_ID_FULL" 4 "SPEED_SPLINE" 3 "SPEED_LIMIT" 2 "TRAFFIC_LIGHT" 1 "STOP_SIGN" 0 "NONE" ;
VAL_ 536 UI_splineLocConfidence 0 "SNA" ;
VAL_ 536 UI_stopSignStopLineDist 1023 "SNA" ;
VAL_ 536 UI_stopSignStopLineConf 0 "SNA" ;
VAL_ 536 UI_trafficLightStopLineDist 1023 "SNA" ;
VAL_ 536 UI_trafficLightStopLineConf 0 "SNA" ;
VAL_ 536 UI_baseMapSpeedLimitMPS 255 "SNA" ;
VAL_ 536 UI_bottomQrtlFleetSpeedMPS 255 "SNA" ;
VAL_ 536 UI_topQrtlFleetSpeedMPS 255 "SNA" ;
VAL_ 536 UI_meanFleetSplineSpeedMPS 255 "SNA" ;
VAL_ 536 UI_medianFleetSpeedMPS 255 "SNA" ;
VAL_ 536 UI_meanFleetSplineAccelMPS2 255 "SNA" ;
VAL_ 536 UI_rampType 4 "INTERCHANGE_EXIT" 3 "INTERCHANGE_ENTRANCE" 2 "EXIT" 1 "ENTRANCE" 0 "NONE_SNA" ;
VAL_ 536 UI_valhallaRamp 2 "ON_RAMP" 1 "NOT_ON_RAMP" 0 "SNA" ;
VAL_ 536 UI_currSplineIdFull 0 "SNA" ;
VAL_ 645 UI_driverProfileRecallIndex 5 "5" 4 "4" 3 "3" 2 "2" 1 "1" 0 "SNA" ;
VAL_ 645 UI_modifyMirrorDipRequest 2 "MODIFY_MIRROR_DIP_REQUEST_DIPPED" 1 "MODIFY_MIRROR_DIP_REQUEST_UNDIPPED" 0 "MODIFY_MIRROR_DIP_REQUEST_NONE" ;
VAL_ 647 UI_driverProfileLinkedKeySHA1 4294967295 "SNA" ;
VAL_ 647 UI_driverProfileSelectionType 3 "DRIVER_PROFILE_SELECTION_TYPE_NONE" 2 "DRIVER_PROFILE_SELECTION_TYPE_AUTOMATIC_NO_OP" 1 "DRIVER_PROFILE_SELECTION_TYPE_AUTOMATIC_RESTORE" 0 "DRIVER_PROFILE_SELECTION_TYPE_MANUAL" ;
VAL_ 984 UI_elevation 8191 "SNA" ;
VAL_ 984 UI_navElevation 8191 "SNA" ;
VAL_ 1279 UI_energyConsumptionInfoIndex 21 "21" 20 "20" 19 "19" 18 "18" 17 "17" 16 "16" 15 "15" 14 "14" 13 "13" 12 "12" 11 "11" 10 "10" 9 "9" 8 "8" 7 "7" 6 "6" 5 "5" 4 "4" 3 "3" 2 "2" 1 "1" 0 "0" ;
VAL_ 1139 UI_nmKeepAwakeReason 31 "UI_KEEPAWAKE_REASON_AUTO_CONDITIONING_START" 30 "UI_KEEPAWAKE_REASON_WINDOW_CONTROL" 29 "UI_KEEPAWAKE_REASON_GET_VEHICLE_CONFIGURATION" 28 "UI_KEEPAWAKE_REASON_MOTHERSHIP_SMS_OWNER_WAKE_UP" 27 "UI_KEEPAWAKE_REASON_MOTHERSHIP_SMS_GARAGE_WAKE_UP" 26 "UI_KEEPAWAKE_REASON_MOTHERSHIP_SMS_VEHICLE_TASK" 25 "UI_KEEPAWAKE_REASON_MOTHERSHIP_SMS_YOUVE_GOT_MAIL" 24 "UI_KEEPAWAKE_REASON_WAKE_UP" 23 "UI_KEEPAWAKE_REASON_FIRMWARE_HANDSHAKE" 22 "UI_KEEPAWAKE_REASON_VEHICLE_DATA" 21 "UI_KEEPAWAKE_REASON_DIAG_VITALS" 20 "UI_KEEPAWAKE_REASON_URGENT_UPLOAD" 19 "UI_KEEPAWAKE_REASON_UI_REQUEST_AP_KEEPALIVE" 18 "UI_KEEPAWAKE_REASON_STEAM" 17 "UI_KEEPAWAKE_REASON_CHARGING" 16 "UI_KEEPAWAKE_REASON_UI_HVAC_REQUEST" 15 "UI_KEEPAWAKE_REASON_USER_NOTIFICATION_TIMER" 14 "UI_KEEPAWAKE_REASON_ODIN" 13 "UI_KEEPAWAKE_REASON_MEDIA_DOWNLOAD" 12 "UI_KEEPAWAKE_REASON_SENTRY_MODE" 11 "UI_KEEPAWAKE_REASON_SELFTEST" 10 "UI_KEEPAWAKE_REASON_ECALL_ACTIVE" 9 "UI_KEEPAWAKE_REASON_UPDATE_COUNTDOWN" 8 "UI_KEEPAWAKE_REASON_AUTOFUSER" 7 "UI_KEEPAWAKE_REASON_HERMES" 6 "UI_KEEPAWAKE_REASON_UPDATER" 5 "UI_KEEPAWAKE_REASON_MODEM_RESET" 4 "UI_KEEPAWAKE_REASON_UNKNOWN_REMOTE_REQUEST" 3 "UI_KEEPAWAKE_REASON_PM_CHECKING" 2 "UI_KEEPAWAKE_REASON_GUI_NEVER_SLEEP_SET" 1 "UI_KEEPAWAKE_REASON_KEEPALIVEACTIVE" 0 "UI_KEEPAWAKE_REASON_NONE_SNA" ;
VAL_ 985 UI_mapSpeedLimitUnits 1 "KPH" 0 "MPH" ;
VAL_ 985 UI_userSpeedOffsetUnits 1 "KPH" 0 "MPH" ;
VAL_ 985 UI_conditionalSpeedLimit 31 "SNA" ;
VAL_ 755 UI_hvacReqTempSetpointLeft 26 "HI" 0 "LO" ;
VAL_ 755 UI_hvacReqAutoBlowerLevel 4 "VERY_HIGH" 3 "HIGH" 2 "MEDIUM" 1 "LOW" 0 "VERY_LOW" ;
VAL_ 755 UI_hvacReqTempSetpointRight 26 "HI" 0 "LO" ;
VAL_ 755 UI_hvacReqAirDistributionMode 7 "MANUAL_DEFROST_PANEL_FLOOR" 6 "MANUAL_DEFROST_PANEL" 5 "MANUAL_DEFROST_FLOOR" 4 "MANUAL_DEFROST" 3 "MANUAL_PANEL_FLOOR" 2 "MANUAL_PANEL" 1 "MANUAL_FLOOR" 0 "AUTO" ;
VAL_ 755 UI_hvacReqBlowerSegment 11 "AUTO" 10 "10" 9 "9" 8 "8" 7 "7" 6 "6" 5 "5" 4 "4" 3 "3" 2 "2" 1 "1" 0 "OFF" ;
VAL_ 755 UI_hvacReqRecirc 2 "FRESH" 1 "RECIRC" 0 "AUTO" ;
VAL_ 755 UI_hvacReqACDisable 2 "ON" 1 "OFF" 0 "AUTO" ;
VAL_ 755 UI_hvacDefogState 3 "AUTO_DEFOG" 2 "DEFROST" 1 "DEFOG" 0 "NONE" ;
VAL_ 755 UI_hvacReqUserPowerState 4 "OVERHEAT_PROTECT" 3 "OVERHEAT_PROTECT_FANONLY" 2 "PRECONDITION" 1 "ON" 0 "OFF" ;
VAL_ 755 UI_hvacReqSecondRowState 4 "HIGH" 3 "MED" 2 "LOW" 1 "OFF" 0 "AUTO" ;
VAL_ 755 UI_hvacReqKeepClimateOn 3 "KEEP_CLIMATE_ON_REQ_PARTY" 2 "KEEP_CLIMATE_ON_REQ_DOG" 1 "KEEP_CLIMATE_ON_REQ_ON" 0 "KEEP_CLIMATE_ON_REQ_OFF" ;
VAL_ 755 UI_hvacReqTempSetpointCOP 2 "HIGH" 1 "MEDIUM" 0 "LOW" ;
VAL_ 755 UI_hvacClimateNudgeStatus 4 "CLOSED_WITH_EXTERIOR_NUDGE" 3 "OPEN_WITH_NUDGE" 2 "OPEN_NO_NUDGE" 1 "CLOSED_WITH_NUDGE" 0 "CLOSED_NO_NUDGE" ;
VAL_ 79 UI_gpsAccuracy 127 "SNA" ;
VAL_ 1011 UI_odometer 16777215 "SNA" ;
VAL_ 443 UI_usbFrontHubPowerStateRequest 2 "POWER_ON" 1 "POWER_NO_PREFERENCE" 0 "POWER_REQUEST_SNA" ;
VAL_ 987 UI_phoneGpsAccuracy 127 "SNA" ;
VAL_ 827 UI_chargeTimeUntilTerminationPct 2047 "SNA" 1440 "MAXVAL" ;
VAL_ 827 UI_chargeTimeUntilReadyToDepart 2047 "SNA" 1440 "MAXVAL" ;
VAL_ 629 UI_powerRationalityConfigIndex 255 "INVALID" 11 "VCRIGHT_DYNAMIC_CURVE_CUTOFF_CONFIG" 10 "VCRIGHT_STATIC_CURVE_CUTOFF_CONFIG" 9 "VCRIGHT_FAST_BLOW_CUTOFF_CONFIG" 8 "VCLEFT_DYNAMIC_CURVE_CUTOFF_CONFIG" 7 "VCLEFT_STATIC_CURVE_CUTOFF_CONFIG" 6 "VCLEFT_FAST_BLOW_CUTOFF_CONFIG" 5 "VCRIGHT_DYNAMIC_CURVE_CONFIG" 4 "VCRIGHT_STATIC_CURVE_CONFIG" 3 "VCRIGHT_FAST_BLOW_CONFIG" 2 "VCLEFT_DYNAMIC_CURVE_CONFIG" 1 "VCLEFT_STATIC_CURVE_CONFIG" 0 "VCLEFT_FAST_BLOW_CONFIG" ;
VAL_ 629 UI_vcleftCfgRationalityThreshold 15 "VC_THRESHOLD_CONFIG_15" 14 "VC_THRESHOLD_CONFIG_14" 13 "VC_THRESHOLD_CONFIG_13" 12 "VC_THRESHOLD_CONFIG_12" 11 "VC_THRESHOLD_CONFIG_11" 10 "VC_THRESHOLD_CONFIG_10" 9 "VC_THRESHOLD_CONFIG_9" 8 "VC_THRESHOLD_CONFIG_8" 7 "VC_THRESHOLD_CONFIG_7" 6 "VC_THRESHOLD_CONFIG_6" 5 "VC_THRESHOLD_CONFIG_5" 4 "VC_THRESHOLD_CONFIG_4" 3 "VC_THRESHOLD_CONFIG_3" 2 "VC_THRESHOLD_CONFIG_2" 1 "VC_THRESHOLD_CONFIG_1" 0 "SNA" ;
VAL_ 629 UI_vcleftCfgRationalityTime0 15 "VC_THRESHOLD_CONFIG_15" 14 "VC_THRESHOLD_CONFIG_14" 13 "VC_THRESHOLD_CONFIG_13" 12 "VC_THRESHOLD_CONFIG_12" 11 "VC_THRESHOLD_CONFIG_11" 10 "VC_THRESHOLD_CONFIG_10" 9 "VC_THRESHOLD_CONFIG_9" 8 "VC_THRESHOLD_CONFIG_8" 7 "VC_THRESHOLD_CONFIG_7" 6 "VC_THRESHOLD_CONFIG_6" 5 "VC_THRESHOLD_CONFIG_5" 4 "VC_THRESHOLD_CONFIG_4" 3 "VC_THRESHOLD_CONFIG_3" 2 "VC_THRESHOLD_CONFIG_2" 1 "VC_THRESHOLD_CONFIG_1" 0 "SNA" ;
VAL_ 629 UI_vcleftCfgRationalityThre_0001 15 "VC_THRESHOLD_CONFIG_15" 14 "VC_THRESHOLD_CONFIG_14" 13 "VC_THRESHOLD_CONFIG_13" 12 "VC_THRESHOLD_CONFIG_12" 11 "VC_THRESHOLD_CONFIG_11" 10 "VC_THRESHOLD_CONFIG_10" 9 "VC_THRESHOLD_CONFIG_9" 8 "VC_THRESHOLD_CONFIG_8" 7 "VC_THRESHOLD_CONFIG_7" 6 "VC_THRESHOLD_CONFIG_6" 5 "VC_THRESHOLD_CONFIG_5" 4 "VC_THRESHOLD_CONFIG_4" 3 "VC_THRESHOLD_CONFIG_3" 2 "VC_THRESHOLD_CONFIG_2" 1 "VC_THRESHOLD_CONFIG_1" 0 "SNA" ;
VAL_ 629 UI_vcleftCfgRationalityTime1 15 "VC_THRESHOLD_CONFIG_15" 14 "VC_THRESHOLD_CONFIG_14" 13 "VC_THRESHOLD_CONFIG_13" 12 "VC_THRESHOLD_CONFIG_12" 11 "VC_THRESHOLD_CONFIG_11" 10 "VC_THRESHOLD_CONFIG_10" 9 "VC_THRESHOLD_CONFIG_9" 8 "VC_THRESHOLD_CONFIG_8" 7 "VC_THRESHOLD_CONFIG_7" 6 "VC_THRESHOLD_CONFIG_6" 5 "VC_THRESHOLD_CONFIG_5" 4 "VC_THRESHOLD_CONFIG_4" 3 "VC_THRESHOLD_CONFIG_3" 2 "VC_THRESHOLD_CONFIG_2" 1 "VC_THRESHOLD_CONFIG_1" 0 "SNA" ;
VAL_ 629 UI_vcleftCfgRationalityStaticA 65535 "SNA" ;
VAL_ 629 UI_vcleftCfgRationalityStaticB -32768 "SNA" ;
VAL_ 629 UI_vcleftCfgRationalityStaticC -32768 "SNA" ;
VAL_ 629 UI_vcleftCfgRationalityDynamicA 65535 "SNA" ;
VAL_ 629 UI_vcleftCfgRationalityDynamicB -32768 "SNA" ;
VAL_ 629 UI_vcleftCfgRationalityDynamicC -32768 "SNA" ;
VAL_ 629 UI_vcrightCfgRationalityThreshol 15 "VC_THRESHOLD_CONFIG_15" 14 "VC_THRESHOLD_CONFIG_14" 13 "VC_THRESHOLD_CONFIG_13" 12 "VC_THRESHOLD_CONFIG_12" 11 "VC_THRESHOLD_CONFIG_11" 10 "VC_THRESHOLD_CONFIG_10" 9 "VC_THRESHOLD_CONFIG_9" 8 "VC_THRESHOLD_CONFIG_8" 7 "VC_THRESHOLD_CONFIG_7" 6 "VC_THRESHOLD_CONFIG_6" 5 "VC_THRESHOLD_CONFIG_5" 4 "VC_THRESHOLD_CONFIG_4" 3 "VC_THRESHOLD_CONFIG_3" 2 "VC_THRESHOLD_CONFIG_2" 1 "VC_THRESHOLD_CONFIG_1" 0 "SNA" ;
VAL_ 629 UI_vcrightCfgRationalityTime0 15 "VC_THRESHOLD_CONFIG_15" 14 "VC_THRESHOLD_CONFIG_14" 13 "VC_THRESHOLD_CONFIG_13" 12 "VC_THRESHOLD_CONFIG_12" 11 "VC_THRESHOLD_CONFIG_11" 10 "VC_THRESHOLD_CONFIG_10" 9 "VC_THRESHOLD_CONFIG_9" 8 "VC_THRESHOLD_CONFIG_8" 7 "VC_THRESHOLD_CONFIG_7" 6 "VC_THRESHOLD_CONFIG_6" 5 "VC_THRESHOLD_CONFIG_5" 4 "VC_THRESHOLD_CONFIG_4" 3 "VC_THRESHOLD_CONFIG_3" 2 "VC_THRESHOLD_CONFIG_2" 1 "VC_THRESHOLD_CONFIG_1" 0 "SNA" ;
VAL_ 629 UI_vcrightCfgRationalityThr_0001 15 "VC_THRESHOLD_CONFIG_15" 14 "VC_THRESHOLD_CONFIG_14" 13 "VC_THRESHOLD_CONFIG_13" 12 "VC_THRESHOLD_CONFIG_12" 11 "VC_THRESHOLD_CONFIG_11" 10 "VC_THRESHOLD_CONFIG_10" 9 "VC_THRESHOLD_CONFIG_9" 8 "VC_THRESHOLD_CONFIG_8" 7 "VC_THRESHOLD_CONFIG_7" 6 "VC_THRESHOLD_CONFIG_6" 5 "VC_THRESHOLD_CONFIG_5" 4 "VC_THRESHOLD_CONFIG_4" 3 "VC_THRESHOLD_CONFIG_3" 2 "VC_THRESHOLD_CONFIG_2" 1 "VC_THRESHOLD_CONFIG_1" 0 "SNA" ;
VAL_ 629 UI_vcrightCfgRationalityTime1 15 "VC_THRESHOLD_CONFIG_15" 14 "VC_THRESHOLD_CONFIG_14" 13 "VC_THRESHOLD_CONFIG_13" 12 "VC_THRESHOLD_CONFIG_12" 11 "VC_THRESHOLD_CONFIG_11" 10 "VC_THRESHOLD_CONFIG_10" 9 "VC_THRESHOLD_CONFIG_9" 8 "VC_THRESHOLD_CONFIG_8" 7 "VC_THRESHOLD_CONFIG_7" 6 "VC_THRESHOLD_CONFIG_6" 5 "VC_THRESHOLD_CONFIG_5" 4 "VC_THRESHOLD_CONFIG_4" 3 "VC_THRESHOLD_CONFIG_3" 2 "VC_THRESHOLD_CONFIG_2" 1 "VC_THRESHOLD_CONFIG_1" 0 "SNA" ;
VAL_ 629 UI_vcrightCfgRationalityStaticA 65535 "SNA" ;
VAL_ 629 UI_vcrightCfgRationalityStaticB -32768 "SNA" ;
VAL_ 629 UI_vcrightCfgRationalityStaticC -32768 "SNA" ;
VAL_ 629 UI_vcrightCfgRationalityDynamicA 65535 "SNA" ;
VAL_ 629 UI_vcrightCfgRationalityDynamicB -32768 "SNA" ;
VAL_ 629 UI_vcrightCfgRationalityDynamicC -32768 "SNA" ;
VAL_ 629 UI_vcleftCfgCutoffThreshold0 15 "VC_THRESHOLD_CONFIG_15" 14 "VC_THRESHOLD_CONFIG_14" 13 "VC_THRESHOLD_CONFIG_13" 12 "VC_THRESHOLD_CONFIG_12" 11 "VC_THRESHOLD_CONFIG_11" 10 "VC_THRESHOLD_CONFIG_10" 9 "VC_THRESHOLD_CONFIG_9" 8 "VC_THRESHOLD_CONFIG_8" 7 "VC_THRESHOLD_CONFIG_7" 6 "VC_THRESHOLD_CONFIG_6" 5 "VC_THRESHOLD_CONFIG_5" 4 "VC_THRESHOLD_CONFIG_4" 3 "VC_THRESHOLD_CONFIG_3" 2 "VC_THRESHOLD_CONFIG_2" 1 "VC_THRESHOLD_CONFIG_1" 0 "SNA" ;
VAL_ 629 UI_vcleftCfgCutoffTime0 15 "VC_THRESHOLD_CONFIG_15" 14 "VC_THRESHOLD_CONFIG_14" 13 "VC_THRESHOLD_CONFIG_13" 12 "VC_THRESHOLD_CONFIG_12" 11 "VC_THRESHOLD_CONFIG_11" 10 "VC_THRESHOLD_CONFIG_10" 9 "VC_THRESHOLD_CONFIG_9" 8 "VC_THRESHOLD_CONFIG_8" 7 "VC_THRESHOLD_CONFIG_7" 6 "VC_THRESHOLD_CONFIG_6" 5 "VC_THRESHOLD_CONFIG_5" 4 "VC_THRESHOLD_CONFIG_4" 3 "VC_THRESHOLD_CONFIG_3" 2 "VC_THRESHOLD_CONFIG_2" 1 "VC_THRESHOLD_CONFIG_1" 0 "SNA" ;
VAL_ 629 UI_vcleftCfgCutoffThreshold1 15 "VC_THRESHOLD_CONFIG_15" 14 "VC_THRESHOLD_CONFIG_14" 13 "VC_THRESHOLD_CONFIG_13" 12 "VC_THRESHOLD_CONFIG_12" 11 "VC_THRESHOLD_CONFIG_11" 10 "VC_THRESHOLD_CONFIG_10" 9 "VC_THRESHOLD_CONFIG_9" 8 "VC_THRESHOLD_CONFIG_8" 7 "VC_THRESHOLD_CONFIG_7" 6 "VC_THRESHOLD_CONFIG_6" 5 "VC_THRESHOLD_CONFIG_5" 4 "VC_THRESHOLD_CONFIG_4" 3 "VC_THRESHOLD_CONFIG_3" 2 "VC_THRESHOLD_CONFIG_2" 1 "VC_THRESHOLD_CONFIG_1" 0 "SNA" ;
VAL_ 629 UI_vcleftCfgCutoffTime1 15 "VC_THRESHOLD_CONFIG_15" 14 "VC_THRESHOLD_CONFIG_14" 13 "VC_THRESHOLD_CONFIG_13" 12 "VC_THRESHOLD_CONFIG_12" 11 "VC_THRESHOLD_CONFIG_11" 10 "VC_THRESHOLD_CONFIG_10" 9 "VC_THRESHOLD_CONFIG_9" 8 "VC_THRESHOLD_CONFIG_8" 7 "VC_THRESHOLD_CONFIG_7" 6 "VC_THRESHOLD_CONFIG_6" 5 "VC_THRESHOLD_CONFIG_5" 4 "VC_THRESHOLD_CONFIG_4" 3 "VC_THRESHOLD_CONFIG_3" 2 "VC_THRESHOLD_CONFIG_2" 1 "VC_THRESHOLD_CONFIG_1" 0 "SNA" ;
VAL_ 629 UI_vcleftCfgCutoffStaticA 65535 "SNA" ;
VAL_ 629 UI_vcleftCfgCutoffStaticB -32768 "SNA" ;
VAL_ 629 UI_vcleftCfgCutoffStaticC -32768 "SNA" ;
VAL_ 629 UI_vcleftCfgCutoffDynamicA 65535 "SNA" ;
VAL_ 629 UI_vcleftCfgCutoffDynamicB -32768 "SNA" ;
VAL_ 629 UI_vcleftCfgCutoffDynamicC -32768 "SNA" ;
VAL_ 629 UI_vcrightCfgCutoffThreshold0 15 "VC_THRESHOLD_CONFIG_15" 14 "VC_THRESHOLD_CONFIG_14" 13 "VC_THRESHOLD_CONFIG_13" 12 "VC_THRESHOLD_CONFIG_12" 11 "VC_THRESHOLD_CONFIG_11" 10 "VC_THRESHOLD_CONFIG_10" 9 "VC_THRESHOLD_CONFIG_9" 8 "VC_THRESHOLD_CONFIG_8" 7 "VC_THRESHOLD_CONFIG_7" 6 "VC_THRESHOLD_CONFIG_6" 5 "VC_THRESHOLD_CONFIG_5" 4 "VC_THRESHOLD_CONFIG_4" 3 "VC_THRESHOLD_CONFIG_3" 2 "VC_THRESHOLD_CONFIG_2" 1 "VC_THRESHOLD_CONFIG_1" 0 "SNA" ;
VAL_ 629 UI_vcrightCfgCutoffTime0 15 "VC_THRESHOLD_CONFIG_15" 14 "VC_THRESHOLD_CONFIG_14" 13 "VC_THRESHOLD_CONFIG_13" 12 "VC_THRESHOLD_CONFIG_12" 11 "VC_THRESHOLD_CONFIG_11" 10 "VC_THRESHOLD_CONFIG_10" 9 "VC_THRESHOLD_CONFIG_9" 8 "VC_THRESHOLD_CONFIG_8" 7 "VC_THRESHOLD_CONFIG_7" 6 "VC_THRESHOLD_CONFIG_6" 5 "VC_THRESHOLD_CONFIG_5" 4 "VC_THRESHOLD_CONFIG_4" 3 "VC_THRESHOLD_CONFIG_3" 2 "VC_THRESHOLD_CONFIG_2" 1 "VC_THRESHOLD_CONFIG_1" 0 "SNA" ;
VAL_ 629 UI_vcrightCfgCutoffThreshold1 15 "VC_THRESHOLD_CONFIG_15" 14 "VC_THRESHOLD_CONFIG_14" 13 "VC_THRESHOLD_CONFIG_13" 12 "VC_THRESHOLD_CONFIG_12" 11 "VC_THRESHOLD_CONFIG_11" 10 "VC_THRESHOLD_CONFIG_10" 9 "VC_THRESHOLD_CONFIG_9" 8 "VC_THRESHOLD_CONFIG_8" 7 "VC_THRESHOLD_CONFIG_7" 6 "VC_THRESHOLD_CONFIG_6" 5 "VC_THRESHOLD_CONFIG_5" 4 "VC_THRESHOLD_CONFIG_4" 3 "VC_THRESHOLD_CONFIG_3" 2 "VC_THRESHOLD_CONFIG_2" 1 "VC_THRESHOLD_CONFIG_1" 0 "SNA" ;
VAL_ 629 UI_vcrightCfgCutoffTime1 15 "VC_THRESHOLD_CONFIG_15" 14 "VC_THRESHOLD_CONFIG_14" 13 "VC_THRESHOLD_CONFIG_13" 12 "VC_THRESHOLD_CONFIG_12" 11 "VC_THRESHOLD_CONFIG_11" 10 "VC_THRESHOLD_CONFIG_10" 9 "VC_THRESHOLD_CONFIG_9" 8 "VC_THRESHOLD_CONFIG_8" 7 "VC_THRESHOLD_CONFIG_7" 6 "VC_THRESHOLD_CONFIG_6" 5 "VC_THRESHOLD_CONFIG_5" 4 "VC_THRESHOLD_CONFIG_4" 3 "VC_THRESHOLD_CONFIG_3" 2 "VC_THRESHOLD_CONFIG_2" 1 "VC_THRESHOLD_CONFIG_1" 0 "SNA" ;
VAL_ 629 UI_vcrightCfgCutoffStaticA 65535 "SNA" ;
VAL_ 629 UI_vcrightCfgCutoffStaticB -32768 "SNA" ;
VAL_ 629 UI_vcrightCfgCutoffStaticC -32768 "SNA" ;
VAL_ 629 UI_vcrightCfgCutoffDynamicA 65535 "SNA" ;
VAL_ 629 UI_vcrightCfgCutoffDynamicB -32768 "SNA" ;
VAL_ 629 UI_vcrightCfgCutoffDynamicC -32768 "SNA" ;
VAL_ 820 UI_systemPowerLimit 31 "SNA" ;
VAL_ 820 UI_pedalMap 2 "PERFORMANCE" 1 "SPORT" 0 "CHILL" ;
VAL_ 820 UI_systemTorqueLimit 63 "SNA" ;
VAL_ 820 UI_closureConfirmed 3 "TRUNK" 2 "PROX" 1 "FRUNK" 0 "NONE" ;
VAL_ 820 UI_limitMode 3 "LIMIT_SERVICE" 2 "LIMIT_FACTORY" 1 "LIMIT_VALET" 0 "LIMIT_NORMAL" ;
VAL_ 820 UI_motorOnMode 2 "MOTORONMODE_REAR_ONLY" 1 "MOTORONMODE_FRONT_ONLY" 0 "MOTORONMODE_NORMAL" ;
VAL_ 820 UI_wasteMode 3 "BURN_IN" 2 "FULL" 1 "PARTIAL" 0 "NONE" ;
VAL_ 820 UI_wasteModeRegenLimit 3 "0A" 2 "10A" 1 "30A" 0 "MAX" ;
VAL_ 820 UI_stoppingMode 2 "HOLD" 1 "CREEP" 0 "STANDARD" ;
VAL_ 820 UI_speedLimit 511 "SNA" ;
VAL_ 820 UI_enableSmartShift 2 "ENABLED_P_R_D" 1 "ENABLED_P" 0 "OFF" ;
VAL_ 820 UI_navVehParallelToRdCanContinue 2 "TRUE" 1 "FALSE" 0 "SNA" ;
VAL_ 698 UI_radarTargetDx 255 "NO_OBJECT" ;
VAL_ 698 UI_radarTargetDxEnd 255 "NO_OBJECT" ;
VAL_ 632 UI_roadCurvHealth 3 "DATABASE" 2 "AVAILABLE" 1 "DEGRADED" 0 "UNAVAILABLE" ;
VAL_ 723 UI_solarAzimuthAngle -32768 "SNA" ;
VAL_ 723 UI_solarAzimuthAngleCarRef 255 "SNA" ;
VAL_ 723 UI_isSunUp 3 "SUN_SNA" 1 "SUN_UP" 0 "SUN_DOWN" ;
VAL_ 723 UI_solarElevationAngle 127 "SNA" ;
VAL_ 563 UI_gearRequest 4 "GEAR_REQUEST_DRIVE" 3 "GEAR_REQUEST_NEUTRAL" 2 "GEAR_REQUEST_REVERSE" 1 "GEAR_REQUEST_PARK" 0 "GEAR_REQUEST_IDLE_SNA" ;
VAL_ 563 UI_autopilotRequest 1 "PRESSED" 0 "IDLE" ;
VAL_ 563 UI_gearStripLocation 1 "RIGHT" 0 "LEFT" ;
VAL_ 699 UI_centerDisplaySM 4 "DOWN" 3 "TIMING_OUT" 2 "STALLING" 1 "UP" 0 "START" ;
VAL_ 851 UI_autopilotTrial 3 "ACTIVE" 2 "STOP" 1 "START" 0 "NONE" ;
VAL_ 851 UI_factoryReset 3 "CUSTOMER" 2 "DIAGNOSTIC" 1 "DEVELOPER" 0 "NONE_SNA" ;
VAL_ 851 UI_cellNetworkTechnology 15 "CELL_NETWORK_SNA" 14 "CELL_NETWORK_NGRAN" 13 "CELL_NETWORK_5GSA" 12 "CELL_NETWORK_5GNSA" 11 "CELL_NETWORK_LTE5GCN" 10 "CELL_NETWORK_WCDMA" 9 "CELL_NETWORK_CDMA" 8 "CELL_NETWORK_GSM" 7 "CELL_NETWORK_LTE" 6 "CELL_NETWORK_HSPA" 5 "CELL_NETWORK_HSUPA" 4 "CELL_NETWORK_HSDPA" 3 "CELL_NETWORK_UMTS" 2 "CELL_NETWORK_EDGE" 1 "CELL_NETWORK_GPRS" 0 "CELL_NETWORK_NONE" ;
VAL_ 851 UI_cellSignalBars 7 "SNA" 5 "FIVE" 4 "FOUR" 3 "THREE" 2 "TWO" 1 "ONE" 0 "ZERO" ;
VAL_ 851 UI_trailerModeTelltale 3 "TRAILER_MODE_TELLTALE_RED" 2 "TRAILER_MODE_TELLTALE_YELLOW" 1 "TRAILER_MODE_TELLTALE_BLUE" 0 "TRAILER_MODE_TELLTALE_OFF" ;
VAL_ 991 UI_userActivity 1 "USER_ACTIVE" 0 "USER_IDLE" ;
VAL_ 991 UI_linkState 2 "LINK_STATE_WIFI" 1 "LINK_STATE_CELL" 0 "LINK_STATE_NONE" ;
VAL_ 991 UI_sentryModeState 6 "SNA" 5 "QUIET" 4 "PANIC" 3 "AWARE" 2 "ARMED" 1 "IDLE" 0 "OFF" ;
VAL_ 991 UI_mobileAppConnected 1 "CONNECTED" 0 "NOT_CONNECTED" ;
VAL_ 991 UI_autoshiftDRState 6 "AUTOSHIFT_DR_STATE_BRAKE_GEAR_SHIFT_CONFIRMED_D" 5 "AUTOSHIFT_DR_STATE_BRAKE_GEAR_SHIFT_CONFIRMED_R" 4 "AUTOSHIFT_DR_STATE_BRAKE_STEERING_AND_BRAKE_CONFIRMED" 3 "AUTOSHIFT_DR_STATE_ONLY_STEERING_CONFIRMED" 2 "AUTOSHIFT_DR_STATE_ONLY_BRAKE_CONFIRMED" 1 "AUTOSHIFT_DR_STATE_PROMPT_SHOWING_UNCONFIRMED" 0 "AUTOSHIFT_DR_STATE_INACTIVE" ;
VAL_ 991 UI_wifiBtModuleType 4 "ELEKTRA" 3 "TCU4G" 2 "BCM4359" 1 "QCA6595" 0 "UNKNOWN" ;
VAL_ 991 UI_sohHealthStatus 3 "OK" 2 "REDUCED" 1 "NO_INTERNET" 0 "UNKNOWN" ;
VAL_ 991 UI_selfParkState 255 "SNA" 52 "SELF_PARK_USER_PAUSED" 51 "SELF_PARK_REMOTE_PRE_ABORT" 50 "SELF_PARK_RESUME" 49 "SELF_PARK_PAUSE" 48 "SELF_PARK_DV_MISMATCH" 47 "SELF_PARK_DI_PANIC" 46 "SELF_PARK_POST_ACTIVE_FAILURE" 45 "SELF_PARK_POST_ACTIVE_SUCCESS" 44 "SELF_PARK_CANCEL_AUTO_SUMMON" 43 "SELF_PARK_REMOTE_ABORT" 42 "SELF_PARK_OBSTACLE_NOT_CLEARED" 41 "SELF_PARK_OBSTACLE_CLEARED" 40 "SELF_PARK_OPEN_GATE" 39 "SELF_PARK_ACTIVE" 38 "SELF_PARK_STARTED_REVERSE" 37 "SELF_PARK_STARTED_FORWARD" 36 "SELF_PARK_NOT_STARTED_TIMEOUT" 35 "SELF_PARK_PRIMED" 34 "SELF_PARK_PREPRIMED" 33 "SELF_PARK_TURN_ON_DRIVE_RAIL" 32 "SELF_PARK_DETECT_KEY_FOB" 31 "SELF_PARK_WAKE_UP_BUSES" 30 "SELF_PARK_CONNECTING_BLUETOOTH" 29 "SELF_PARK_UNAVAILABLE_CAR_WASH_MODE" 28 "SELF_PARK_UNAVAILABLE_CAR_ALARM" 27 "SELF_PARK_UNAVAILABLE_CRASH_STATE" 26 "SELF_PARK_UNAVAILABLE_DRAG_STRIP_MODE" 25 "SELF_PARK_UNAVAILABLE_TRACK_MODE" 24 "SELF_PARK_UNAVAILABLE_SERVICE_MODE" 23 "SELF_PARK_UNAVAILABLE_DOG_MODE" 22 "SELF_PARK_UNAVAILABLE_GAME_MODE" 21 "SELF_PARK_UNAVAILABLE_BLUETOOTH_CONNECT_TIMEOUT" 20 "SELF_PARK_UNAVAILABLE_WAKEUP_TIMEOUT" 19 "SELF_PARK_UNAVAILABLE_NO_BLUETOOTH_DEVICES_PAIRED" 18 "SELF_PARK_UNAVAILABLE_BRAKE_PRESSED" 17 "SELF_PARK_UNAVAILABLE_ROAD_GRADE" 16 "SELF_PARK_UNAVAILABLE_TRAILER_MODE" 15 "SELF_PARK_UNAVAILABLE_KEY_FOB_BATTERY_LOW" 14 "SELF_PARK_UNAVAILABLE_KEY_FOB_NOT_DETECTED" 13 "SELF_PARK_UNAVAILABLE_PARK_SENSOR_ISSUE" 12 "SELF_PARK_UNAVAILABLE_AUTOSTEER_NOT_ENABLED" 11 "SELF_PARK_UNAVAILABLE_LV_BUS_SUPPORT_ISSUE" 10 "SELF_PARK_UNAVAILABLE_ON_PUBLIC_ROAD" 9 "SELF_PARK_UNAVAILABLE_PARKED_TOO_LONG" 8 "SELF_PARK_UNAVAILABLE_DOOR_OPEN" 7 "SELF_PARK_UNAVAILABLE_TRUNK_OPEN" 6 "SELF_PARK_UNAVAILABLE_FRUNK_OPEN" 5 "SELF_PARK_UNAVAILABLE_PLUGGED_IN" 4 "SELF_PARK_UNAVAILABLE_NOT_PARKED" 3 "SELF_PARK_UNAVAILABLE" 2 "SELF_PARK_IDLE" 1 "SELF_PARK_DRIVING" 0 "SELF_PARK_DISABLED" ;
VAL_ 991 UI_summonDeviceIndex 3 "UNKNOWN" 2 "DEVICE_2" 1 "DEVICE_1" 0 "DEVICE_0" ;
VAL_ 663 UI_adaptiveRideRequest 3 "ADAPTIVE_RIDE_REQUEST_ADVANCED" 2 "ADAPTIVE_RIDE_REQUEST_SPORT" 1 "ADAPTIVE_RIDE_REQUEST_AUTO" 0 "ADAPTIVE_RIDE_REQUEST_COMFORT" ;
VAL_ 663 UI_suspensionLoweringRequest 3 "SNA" 2 "AUTO" 1 "ALWAYS" 0 "NEVER" ;
VAL_ 663 UI_geofenceLevelingRequest 5 "GEOFENCE_LEVELING_REQUEST_SNA" 4 "GEOFENCE_LEVELING_REQUEST_VERY_HIGH_PERSIST" 3 "GEOFENCE_LEVELING_REQUEST_HIGH_PERSIST" 2 "GEOFENCE_LEVELING_REQUEST_VERY_HIGH_TEMPORARY" 1 "GEOFENCE_LEVELING_REQUEST_HIGH_TEMPORARY" 0 "GEOFENCE_LEVELING_REQUEST_NONE" ;
VAL_ 663 UI_jackModeToggleRequest 1 "ACTIVE" 0 "NONE" ;
VAL_ 663 UI_roadRoughnessLookahead 127 "SNA" ;
VAL_ 663 UI_roadRoughnessStart 31 "SNA" ;
VAL_ 663 UI_mapVersionUsed 255 "SNA" ;
VAL_ 663 UI_suspensionLevelRequest 7 "VERY_HIGH_LEVEL_PERSIST" 6 "HIGH_LEVEL_PERSIST" 5 "VERY_HIGH_LEVEL_TEMPORARY" 4 "HIGH_LEVEL_TEMPORARY" 3 "STANDARD_LEVEL" 2 "LOW_LEVEL" 1 "VERY_LOW_LEVEL" 0 "NONE" ;
VAL_ 661 UI_systemMonitorIndex 1 "1" 0 "0" ;
VAL_ 856 UI_TPMSMode 2 "PERFORMANCE_MODE" 1 "NORMAL_MODE" 0 "UNUSED_MODE" ;
VAL_ 856 UI_TPMSLearnIDMode 4 "AUTO_LOCATION_ACTIVE_AFTER_PWR" 3 "AUTO_LEARN_ACTIVE_AFTER_PWR" 2 "AUTO_LOCATION_ACTIVE_BY_MANUAL" 1 "AUTO_LEARN_ACTIVE_BY_MANUAL" 0 "NO_ID_LEARN_FUNCTION" ;
VAL_ 856 UI_sizeOfWheelSelect 2 "19_INCH_WHEEL" 1 "18_INCH_WHEEL" 0 "UNUSED" ;
VAL_ 787 UI_trackModeRequest 2 "TRACK_MODE_REQUEST_OFF" 1 "TRACK_MODE_REQUEST_ON" 0 "TRACK_MODE_REQUEST_IDLE" ;
VAL_ 787 UI_trackPostCooling 1 "ON" 0 "OFF" ;
VAL_ 787 UI_trackCmpOverclock 1 "ON" 0 "OFF" ;
VAL_ 787 UI_trackModeBrakeTemps 1 "ON" 0 "OFF" ;
VAL_ 787 UI_trackDrivePowerAvailability 2 "TRACK_MODE_POWER_MAX" 1 "TRACK_MODE_POWER_MIDDLE" 0 "TRACK_MODE_POWER_ENDURANCE" ;
VAL_ 130 UI_navFastchargerType 4 "V4" 3 "V3" 2 "V2" 1 "LOW_POWER" 0 "NONE" ;
VAL_ 130 UI_battPreconditionOnNavState 3 "ACTIVE_COOL" 2 "PASSIVE_COOL" 1 "ACTIVE_HEAT" 0 "PASSIVE_HEAT" ;
VAL_ 130 UI_battPreconditionOnNavPowerReq 127 "SNA" 126 "MAX" -126 "MIN" ;
VAL_ 130 UI_battPreconditionOnNavTargetT 255 "SNA" 254 "MAX" 0 "MIN" ;
VAL_ 130 UI_ambientTempAtDestination -128 "SNA" ;
VAL_ 130 UI_energyAtDestination -32767 "TRIP_TOO_LONG" -32768 "SNA" ;
VAL_ 139 UI_maxSpeedToReachDestination 65535 "SNA" 65534 "UNREACHABLE" 65533 "MAXVAL" ;
VAL_ 139 UI_remainingWeightedRMSSpeed 65535 "SNA" 65534 "MAXVAL" ;
VAL_ 139 UI_timeToDestination 65535 "SNA" 65534 "MAXVAL" ;
VAL_ 1173 UI_predictedEnergy -32767 "TRIP_TOO_LONG" -32768 "SNA" ;
VAL_ 1173 UI_predictedEnergyLearned -32767 "TRIP_TOO_LONG" -32768 "SNA" ;
VAL_ 1173 UI_hindsightEnergy -32767 "TRIP_TOO_LONG" -32768 "SNA" ;
VAL_ 1173 UI_hindsightEnergyLearned -32767 "TRIP_TOO_LONG" -32768 "SNA" ;
VAL_ 1174 UI_longTermEnergyModelError 127 "MAXVAL" -128 "SNA" ;
VAL_ 1174 UI_longTermRmsSpeedRatio 255 "SNA" 254 "MAXVAL" ;
VAL_ 1174 UI_gradeCorrectedEnergy -32767 "TRIP_TOO_LONG" -32768 "SNA" ;
VAL_ 1174 UI_gradeCorrectedEnergyLearned -32767 "TRIP_TOO_LONG" -32768 "SNA" ;
VAL_ 1175 UI_battPreconditionOnNavTime 65535 "SNA" 65534 "MAXVAL" ;
VAL_ 1175 UI_maxBattPreconditionOnNavTime 65535 "SNA" 65534 "MAXVAL" ;
VAL_ 1175 UI_tripPlanChargingTargetPercent 1023 "SNA" ;
VAL_ 1827 UI_ussSensorIdX 5 "FRONT_SIDE" 4 "FRONT_CORNER" 3 "FRONT_INNER" 2 "REAR_SIDE" 1 "REAR_CORNER" 0 "REAR_INNER" ;
